VERSION ""

NS_ :

BS_:

BU_: Battery_Management_Cntrl_1 PowertrainControlModule AtmosphericSensor SafetyRestraintSystem2 Aftertreatment_2_GasOutlet Aftertreatment_2_GasIntake DieselParticulateFilterControl Turbocharger SafetyRestraintSystem1 CabDisplay2 Aftertreatment_1_GasOutlet Aftertreatment_1_GasIntake OnBoardDataLogger OffBoardDiagnosticTool2 OffBoardDiagnosticTool1 FileServer ParkingBrakeController SeatController2 FanDriveController SteeringColumnUnit CommunicationUnitRadio CommunicationUnitSatellite CommunicationUnitCellular PropulsionBatteryCharger ChassisController2 ChassisController1 EngineValveControl AuxiliaryHeater2 AuxiliaryHeater1 ClutchUnit RampControl InformationSystem1 SuspensionSystemController2 OilSensor VehicleDynamicStability ExhaustEmissionController TransmissionDisplay2 TransmissionDisplay1 ClimateControl2 WaterPumpController RearAxleSteeringController LightingOperatorControl SeatController1 IgnitionController2 IgnitionController1 TirePressureController CabController2 CabController1 PneumaticSystemController SuspensionSystemController1 HydraulicPumpController EnduranceBrakingSystem RetarderExhaustEngine2 OnBoardDiagnosticUnit HeadwayController RetarderExhaustEngine1 CabDisplay1 ManagementComputer VirtualTerminal OffVehicleGateway PowerTakeOffFront HitchControl AuxiliaryValveControl BodyController TractorTrailerBridge1 StarterSystem ElectricalSystem VehicleSecurity VehicleNavigation AerodynamicControl ElectricalChargingSystem ClimateControl1 TripRecorder InstrumentCluster SuspensionDriveAxle2 SuspensionDriveAxle1 SuspensionSteerAxle SteeringController FuelSystem CruiseControl RetarderDriveline RetarderEngine BrakesDriveAxle2 BrakesDriveAxle1 BrakesSystemController BrakesSteerAxle AxleDrive2 AxleDrive1 AxleSteering PowerTakeOff ShiftConsoleSecondary ShiftConsolePrimary Transmission2 Transmission1 Engine2 Engine1

BO_ 2566705662 DM53: 22 Vector__XXX
 SG_ DTC1 : 16|32@1+ (1,0) [0|4294967295] "" Vector__XXX
 SG_ FlashProtectLamp : 8|2@1+ (1,0) [0|3] "" Vector__XXX
 SG_ FlashAmberWarningLamp : 10|2@1+ (1,0) [0|3] "" Vector__XXX
 SG_ FlashRedStopLamp : 12|2@1+ (1,0) [0|3] "" Vector__XXX
 SG_ FlashMalfuncIndicatorLamp : 14|2@1+ (1,0) [0|3] "" Vector__XXX
 SG_ ProtectLampStatus : 0|2@1+ (1,0) [0|3] "" Vector__XXX
 SG_ AmberWarningLampStatus : 2|2@1+ (1,0) [0|3] "" Vector__XXX
 SG_ RedStopLampState : 4|2@1+ (1,0) [0|3] "" Vector__XXX
 SG_ MalfunctionIndicatorLampStatus : 6|2@1+ (1,0) [0|3] "" Vector__XXX
 SG_ DTC5 : 144|32@1+ (1,0) [0|4294967295] "" Vector__XXX
 SG_ DTC4 : 112|32@1+ (1,0) [0|4294967295] "" Vector__XXX
 SG_ DTC3 : 80|32@1+ (1,0) [0|4294967295] "" Vector__XXX
 SG_ DTC2 : 48|32@1+ (1,0) [0|4294967295] "" Vector__XXX

BO_ 2566706174 DM55: 0 Vector__XXX

BO_ 2349465342 SRASI_2304: 8 Vector__XXX
 SG_ StaticRollAngleStatus_5583 : 8|3@1+ (1,0) [0|7] "" Vector__XXX
 SG_ StaticRollAngle_5582 : 0|8@1+ (1,-125) [-90|90] "deg" Vector__XXX

BO_ 2498777086 ECCAI2: 8 Vector__XXX
 SG_ EngCyl2AverageCombustionDuration : 48|16@1+ (0.0078125,0) [0|501.99] "deg" Vector__XXX
 SG_ EngCyl2AvrgCntrOfCmbustionTiming : 32|16@1+ (0.0078125,-250) [-250|250.992] "deg" Vector__XXX
 SG_ EngCyl2AvrgStrtOfCmbustionTiming : 16|16@1+ (0.0078125,-250) [-250|250.992] "deg" Vector__XXX
 SG_ EngCyl2IndctedMeanEffectivePress : 0|16@1+ (0.0001220703125,-1) [-1|6.84362793] "MPa" Vector__XXX

BO_ 2498776830 ECCAI1: 8 Vector__XXX
 SG_ EngCyl1AverageCombustionDuration : 48|16@1+ (0.0078125,0) [0|501.99] "deg" Vector__XXX
 SG_ EngCyl1AvrgCntrOfCmbustionTiming : 32|16@1+ (0.0078125,-250) [-250|250.992] "deg" Vector__XXX
 SG_ EngCyl1AvrgStrtOfCmbustionTiming : 16|16@1+ (0.0078125,-250) [-250|250.992] "deg" Vector__XXX
 SG_ EngCyl1IndctedMeanEffectivePress : 0|16@1+ (0.0001220703125,-1) [-1|6.84362793] "MPa" Vector__XXX

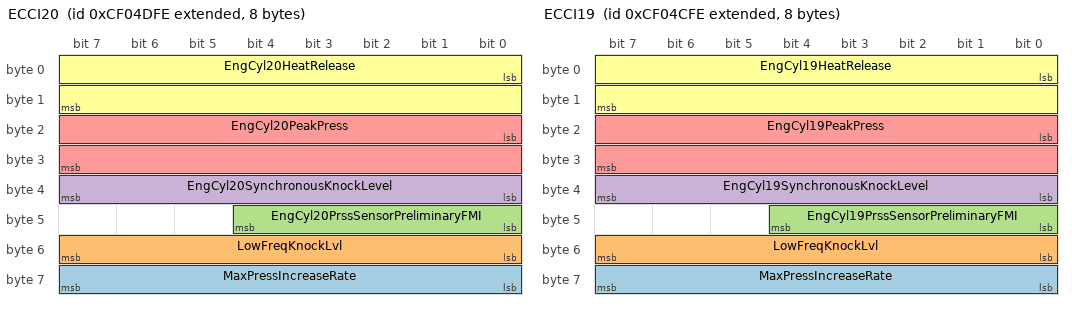
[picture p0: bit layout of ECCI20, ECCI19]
BO_ 2364558846 ECCI20: 8 Vector__XXX
 SG_ MaxPressIncreaseRate : 56|8@1+ (16,0) [0|4000] "kPa/deg crank angle" Vector__XXX
 SG_ LowFreqKnockLvl : 48|8@1+ (1,0) [0|250] "%" Vector__XXX
 SG_ EngCyl20PrssSensorPreliminaryFMI : 40|5@1+ (1,0) [0|31] "" Vector__XXX
 SG_ EngCyl20SynchronousKnockLevel : 32|8@1+ (1,0) [0|250] "%" Vector__XXX
 SG_ EngCyl20PeakPress : 16|16@1+ (0.0009765625,0) [0|62.74902344] "MPa" Vector__XXX
 SG_ EngCyl20HeatRelease : 0|16@1+ (0.0001220703125,-1) [-1|6.84362793] "kJ/l" Vector__XXX

BO_ 2364558590 ECCI19: 8 Vector__XXX
 SG_ MaxPressIncreaseRate : 56|8@1+ (16,0) [0|4000] "kPa/deg crank angle" Vector__XXX
 SG_ LowFreqKnockLvl : 48|8@1+ (1,0) [0|250] "%" Vector__XXX
 SG_ EngCyl19PrssSensorPreliminaryFMI : 40|5@1+ (1,0) [0|31] "" Vector__XXX
 SG_ EngCyl19SynchronousKnockLevel : 32|8@1+ (1,0) [0|250] "%" Vector__XXX
 SG_ EngCyl19PeakPress : 16|16@1+ (0.0009765625,0) [0|62.74902344] "MPa" Vector__XXX
 SG_ EngCyl19HeatRelease : 0|16@1+ (0.0001220703125,-1) [-1|6.84362793] "kJ/l" Vector__XXX

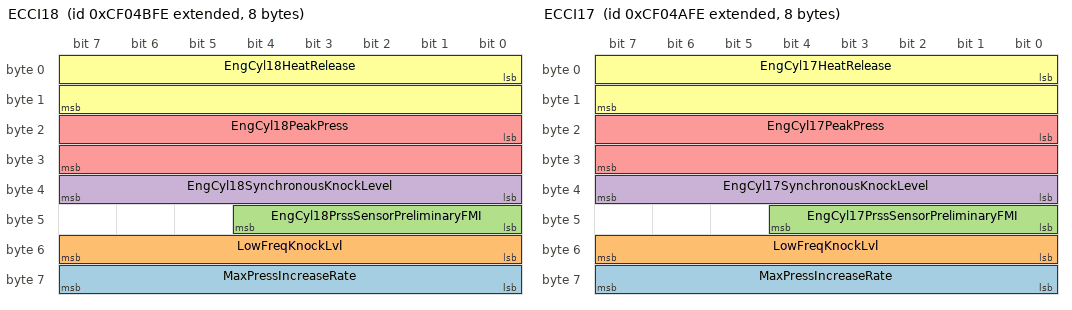
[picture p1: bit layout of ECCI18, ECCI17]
BO_ 2364558334 ECCI18: 8 Vector__XXX
 SG_ MaxPressIncreaseRate : 56|8@1+ (16,0) [0|4000] "kPa/deg crank angle" Vector__XXX
 SG_ LowFreqKnockLvl : 48|8@1+ (1,0) [0|250] "%" Vector__XXX
 SG_ EngCyl18PrssSensorPreliminaryFMI : 40|5@1+ (1,0) [0|31] "" Vector__XXX
 SG_ EngCyl18SynchronousKnockLevel : 32|8@1+ (1,0) [0|250] "%" Vector__XXX
 SG_ EngCyl18PeakPress : 16|16@1+ (0.0009765625,0) [0|62.74902344] "MPa" Vector__XXX
 SG_ EngCyl18HeatRelease : 0|16@1+ (0.0001220703125,-1) [-1|6.84362793] "kJ/l" Vector__XXX

BO_ 2364558078 ECCI17: 8 Vector__XXX
 SG_ MaxPressIncreaseRate : 56|8@1+ (16,0) [0|4000] "kPa/deg crank angle" Vector__XXX
 SG_ LowFreqKnockLvl : 48|8@1+ (1,0) [0|250] "%" Vector__XXX
 SG_ EngCyl17PrssSensorPreliminaryFMI : 40|5@1+ (1,0) [0|31] "" Vector__XXX
 SG_ EngCyl17SynchronousKnockLevel : 32|8@1+ (1,0) [0|250] "%" Vector__XXX
 SG_ EngCyl17PeakPress : 16|16@1+ (0.0009765625,0) [0|62.74902344] "MPa" Vector__XXX
 SG_ EngCyl17HeatRelease : 0|16@1+ (0.0001220703125,-1) [-1|6.84362793] "kJ/l" Vector__XXX

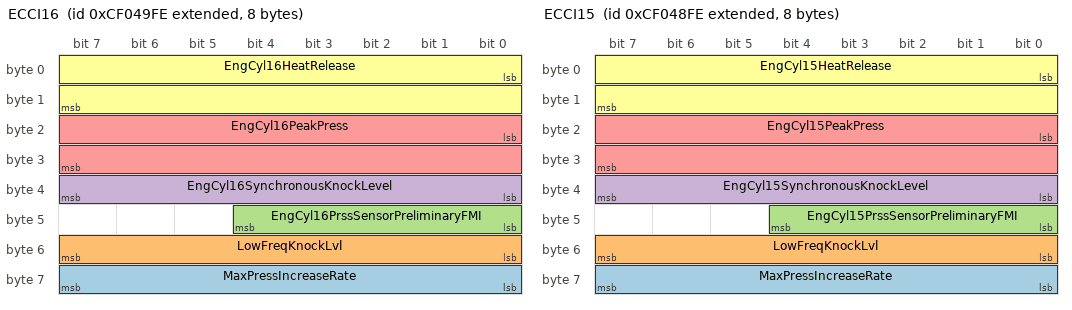
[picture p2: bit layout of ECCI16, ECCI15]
BO_ 2364557822 ECCI16: 8 Vector__XXX
 SG_ MaxPressIncreaseRate : 56|8@1+ (16,0) [0|4000] "kPa/deg crank angle" Vector__XXX
 SG_ LowFreqKnockLvl : 48|8@1+ (1,0) [0|250] "%" Vector__XXX
 SG_ EngCyl16PrssSensorPreliminaryFMI : 40|5@1+ (1,0) [0|31] "" Vector__XXX
 SG_ EngCyl16SynchronousKnockLevel : 32|8@1+ (1,0) [0|250] "%" Vector__XXX
 SG_ EngCyl16PeakPress : 16|16@1+ (0.0009765625,0) [0|62.74902344] "MPa" Vector__XXX
 SG_ EngCyl16HeatRelease : 0|16@1+ (0.0001220703125,-1) [-1|6.84362793] "kJ/l" Vector__XXX

BO_ 2364557566 ECCI15: 8 Vector__XXX
 SG_ MaxPressIncreaseRate : 56|8@1+ (16,0) [0|4000] "kPa/deg crank angle" Vector__XXX
 SG_ LowFreqKnockLvl : 48|8@1+ (1,0) [0|250] "%" Vector__XXX
 SG_ EngCyl15PrssSensorPreliminaryFMI : 40|5@1+ (1,0) [0|31] "" Vector__XXX
 SG_ EngCyl15SynchronousKnockLevel : 32|8@1+ (1,0) [0|250] "%" Vector__XXX
 SG_ EngCyl15PeakPress : 16|16@1+ (0.0009765625,0) [0|62.74902344] "MPa" Vector__XXX
 SG_ EngCyl15HeatRelease : 0|16@1+ (0.0001220703125,-1) [-1|6.84362793] "kJ/l" Vector__XXX

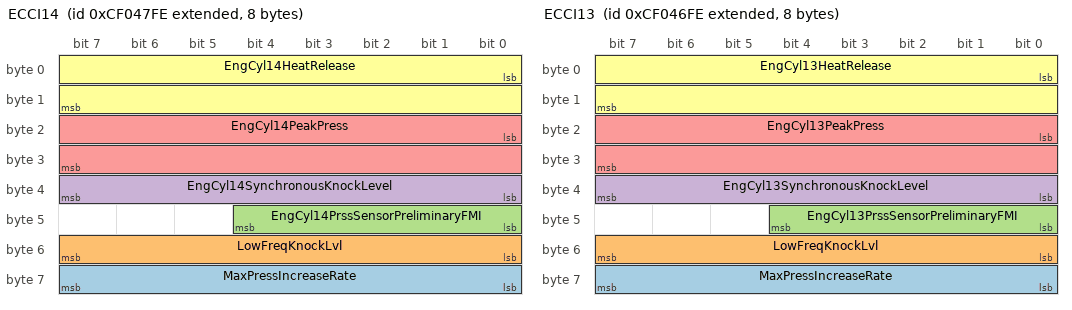
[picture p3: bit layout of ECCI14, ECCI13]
BO_ 2364557310 ECCI14: 8 Vector__XXX
 SG_ MaxPressIncreaseRate : 56|8@1+ (16,0) [0|4000] "kPa/deg crank angle" Vector__XXX
 SG_ LowFreqKnockLvl : 48|8@1+ (1,0) [0|250] "%" Vector__XXX
 SG_ EngCyl14PrssSensorPreliminaryFMI : 40|5@1+ (1,0) [0|31] "" Vector__XXX
 SG_ EngCyl14SynchronousKnockLevel : 32|8@1+ (1,0) [0|250] "%" Vector__XXX
 SG_ EngCyl14PeakPress : 16|16@1+ (0.0009765625,0) [0|62.74902344] "MPa" Vector__XXX
 SG_ EngCyl14HeatRelease : 0|16@1+ (0.0001220703125,-1) [-1|6.84362793] "kJ/l" Vector__XXX

BO_ 2364557054 ECCI13: 8 Vector__XXX
 SG_ MaxPressIncreaseRate : 56|8@1+ (16,0) [0|4000] "kPa/deg crank angle" Vector__XXX
 SG_ LowFreqKnockLvl : 48|8@1+ (1,0) [0|250] "%" Vector__XXX
 SG_ EngCyl13PrssSensorPreliminaryFMI : 40|5@1+ (1,0) [0|31] "" Vector__XXX
 SG_ EngCyl13SynchronousKnockLevel : 32|8@1+ (1,0) [0|250] "%" Vector__XXX
 SG_ EngCyl13PeakPress : 16|16@1+ (0.0009765625,0) [0|62.74902344] "MPa" Vector__XXX
 SG_ EngCyl13HeatRelease : 0|16@1+ (0.0001220703125,-1) [-1|6.84362793] "kJ/l" Vector__XXX

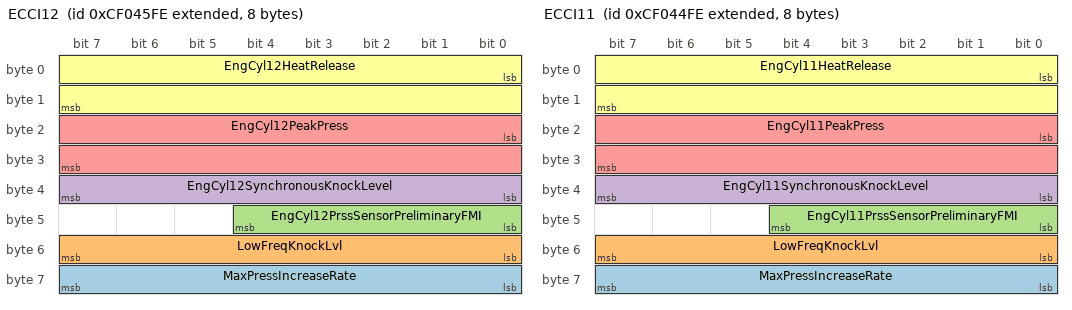
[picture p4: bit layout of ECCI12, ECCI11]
BO_ 2364556798 ECCI12: 8 Vector__XXX
 SG_ MaxPressIncreaseRate : 56|8@1+ (16,0) [0|4000] "kPa/deg crank angle" Vector__XXX
 SG_ LowFreqKnockLvl : 48|8@1+ (1,0) [0|250] "%" Vector__XXX
 SG_ EngCyl12PrssSensorPreliminaryFMI : 40|5@1+ (1,0) [0|31] "" Vector__XXX
 SG_ EngCyl12SynchronousKnockLevel : 32|8@1+ (1,0) [0|250] "%" Vector__XXX
 SG_ EngCyl12PeakPress : 16|16@1+ (0.0009765625,0) [0|62.74902344] "MPa" Vector__XXX
 SG_ EngCyl12HeatRelease : 0|16@1+ (0.0001220703125,-1) [-1|6.84362793] "kJ/l" Vector__XXX

BO_ 2364556542 ECCI11: 8 Vector__XXX
 SG_ MaxPressIncreaseRate : 56|8@1+ (16,0) [0|4000] "kPa/deg crank angle" Vector__XXX
 SG_ LowFreqKnockLvl : 48|8@1+ (1,0) [0|250] "%" Vector__XXX
 SG_ EngCyl11PrssSensorPreliminaryFMI : 40|5@1+ (1,0) [0|31] "" Vector__XXX
 SG_ EngCyl11SynchronousKnockLevel : 32|8@1+ (1,0) [0|250] "%" Vector__XXX
 SG_ EngCyl11PeakPress : 16|16@1+ (0.0009765625,0) [0|62.74902344] "MPa" Vector__XXX
 SG_ EngCyl11HeatRelease : 0|16@1+ (0.0001220703125,-1) [-1|6.84362793] "kJ/l" Vector__XXX

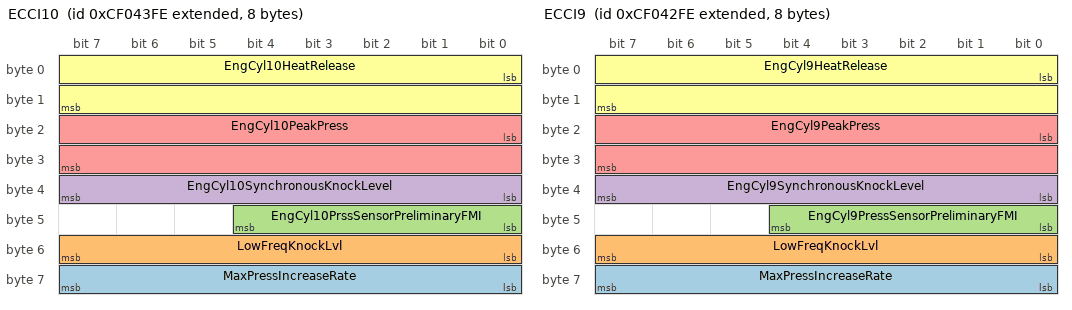
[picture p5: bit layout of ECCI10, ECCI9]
BO_ 2364556286 ECCI10: 8 Vector__XXX
 SG_ MaxPressIncreaseRate : 56|8@1+ (16,0) [0|4000] "kPa/deg crank angle" Vector__XXX
 SG_ LowFreqKnockLvl : 48|8@1+ (1,0) [0|250] "%" Vector__XXX
 SG_ EngCyl10PrssSensorPreliminaryFMI : 40|5@1+ (1,0) [0|31] "" Vector__XXX
 SG_ EngCyl10SynchronousKnockLevel : 32|8@1+ (1,0) [0|250] "%" Vector__XXX
 SG_ EngCyl10PeakPress : 16|16@1+ (0.0009765625,0) [0|62.74902344] "MPa" Vector__XXX
 SG_ EngCyl10HeatRelease : 0|16@1+ (0.0001220703125,-1) [-1|6.84362793] "kJ/l" Vector__XXX

BO_ 2364556030 ECCI9: 8 Vector__XXX
 SG_ MaxPressIncreaseRate : 56|8@1+ (16,0) [0|4000] "kPa/deg crank angle" Vector__XXX
 SG_ LowFreqKnockLvl : 48|8@1+ (1,0) [0|250] "%" Vector__XXX
 SG_ EngCyl9PressSensorPreliminaryFMI : 40|5@1+ (1,0) [0|31] "" Vector__XXX
 SG_ EngCyl9SynchronousKnockLevel : 32|8@1+ (1,0) [0|250] "%" Vector__XXX
 SG_ EngCyl9PeakPress : 16|16@1+ (0.0009765625,0) [0|62.74902344] "MPa" Vector__XXX
 SG_ EngCyl9HeatRelease : 0|16@1+ (0.0001220703125,-1) [-1|6.84362793] "kJ/l" Vector__XXX

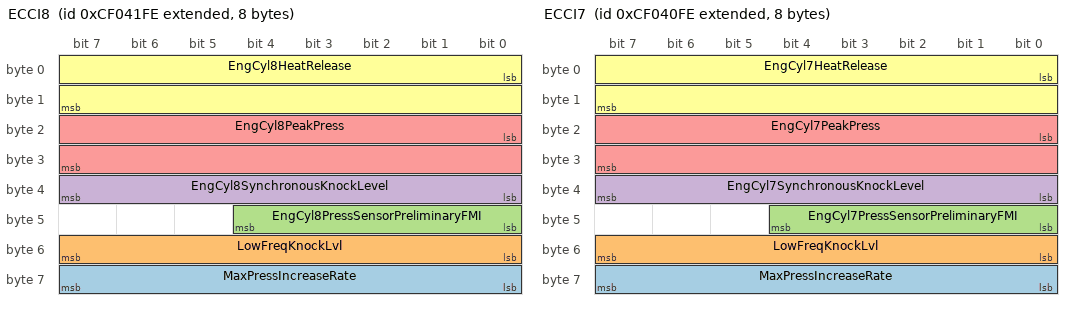
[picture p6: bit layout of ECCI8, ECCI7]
BO_ 2364555774 ECCI8: 8 Vector__XXX
 SG_ MaxPressIncreaseRate : 56|8@1+ (16,0) [0|4000] "kPa/deg crank angle" Vector__XXX
 SG_ LowFreqKnockLvl : 48|8@1+ (1,0) [0|250] "%" Vector__XXX
 SG_ EngCyl8PressSensorPreliminaryFMI : 40|5@1+ (1,0) [0|31] "" Vector__XXX
 SG_ EngCyl8SynchronousKnockLevel : 32|8@1+ (1,0) [0|250] "%" Vector__XXX
 SG_ EngCyl8PeakPress : 16|16@1+ (0.0009765625,0) [0|62.74902344] "MPa" Vector__XXX
 SG_ EngCyl8HeatRelease : 0|16@1+ (0.0001220703125,-1) [-1|6.84362793] "kJ/l" Vector__XXX

BO_ 2364555518 ECCI7: 8 Vector__XXX
 SG_ MaxPressIncreaseRate : 56|8@1+ (16,0) [0|4000] "kPa/deg crank angle" Vector__XXX
 SG_ LowFreqKnockLvl : 48|8@1+ (1,0) [0|250] "%" Vector__XXX
 SG_ EngCyl7PressSensorPreliminaryFMI : 40|5@1+ (1,0) [0|31] "" Vector__XXX
 SG_ EngCyl7SynchronousKnockLevel : 32|8@1+ (1,0) [0|250] "%" Vector__XXX
 SG_ EngCyl7PeakPress : 16|16@1+ (0.0009765625,0) [0|62.74902344] "MPa" Vector__XXX
 SG_ EngCyl7HeatRelease : 0|16@1+ (0.0001220703125,-1) [-1|6.84362793] "kJ/l" Vector__XXX

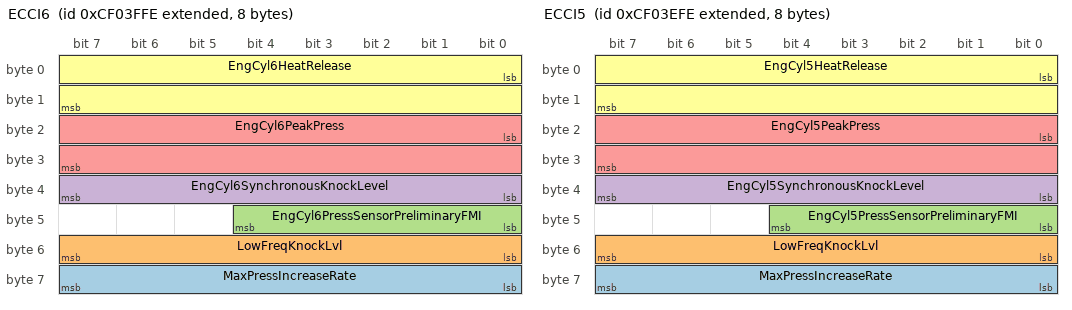
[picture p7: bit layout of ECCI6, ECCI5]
BO_ 2364555262 ECCI6: 8 Vector__XXX
 SG_ MaxPressIncreaseRate : 56|8@1+ (16,0) [0|4000] "kPa/deg crank angle" Vector__XXX
 SG_ LowFreqKnockLvl : 48|8@1+ (1,0) [0|250] "%" Vector__XXX
 SG_ EngCyl6PressSensorPreliminaryFMI : 40|5@1+ (1,0) [0|31] "" Vector__XXX
 SG_ EngCyl6SynchronousKnockLevel : 32|8@1+ (1,0) [0|250] "%" Vector__XXX
 SG_ EngCyl6PeakPress : 16|16@1+ (0.0009765625,0) [0|62.74902344] "MPa" Vector__XXX
 SG_ EngCyl6HeatRelease : 0|16@1+ (0.0001220703125,-1) [-1|6.84362793] "kJ/l" Vector__XXX

BO_ 2364555006 ECCI5: 8 Vector__XXX
 SG_ MaxPressIncreaseRate : 56|8@1+ (16,0) [0|4000] "kPa/deg crank angle" Vector__XXX
 SG_ LowFreqKnockLvl : 48|8@1+ (1,0) [0|250] "%" Vector__XXX
 SG_ EngCyl5PressSensorPreliminaryFMI : 40|5@1+ (1,0) [0|31] "" Vector__XXX
 SG_ EngCyl5SynchronousKnockLevel : 32|8@1+ (1,0) [0|250] "%" Vector__XXX
 SG_ EngCyl5PeakPress : 16|16@1+ (0.0009765625,0) [0|62.74902344] "MPa" Vector__XXX
 SG_ EngCyl5HeatRelease : 0|16@1+ (0.0001220703125,-1) [-1|6.84362793] "kJ/l" Vector__XXX

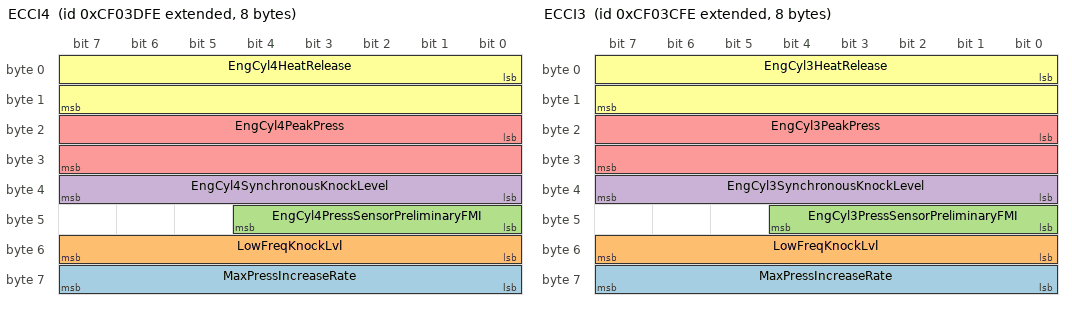
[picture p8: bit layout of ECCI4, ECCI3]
BO_ 2364554750 ECCI4: 8 Vector__XXX
 SG_ MaxPressIncreaseRate : 56|8@1+ (16,0) [0|4000] "kPa/deg crank angle" Vector__XXX
 SG_ LowFreqKnockLvl : 48|8@1+ (1,0) [0|250] "%" Vector__XXX
 SG_ EngCyl4PressSensorPreliminaryFMI : 40|5@1+ (1,0) [0|31] "" Vector__XXX
 SG_ EngCyl4SynchronousKnockLevel : 32|8@1+ (1,0) [0|250] "%" Vector__XXX
 SG_ EngCyl4PeakPress : 16|16@1+ (0.0009765625,0) [0|62.74902344] "MPa" Vector__XXX
 SG_ EngCyl4HeatRelease : 0|16@1+ (0.0001220703125,-1) [-1|6.84362793] "kJ/l" Vector__XXX

BO_ 2364554494 ECCI3: 8 Vector__XXX
 SG_ MaxPressIncreaseRate : 56|8@1+ (16,0) [0|4000] "kPa/deg crank angle" Vector__XXX
 SG_ LowFreqKnockLvl : 48|8@1+ (1,0) [0|250] "%" Vector__XXX
 SG_ EngCyl3PressSensorPreliminaryFMI : 40|5@1+ (1,0) [0|31] "" Vector__XXX
 SG_ EngCyl3SynchronousKnockLevel : 32|8@1+ (1,0) [0|250] "%" Vector__XXX
 SG_ EngCyl3PeakPress : 16|16@1+ (0.0009765625,0) [0|62.74902344] "MPa" Vector__XXX
 SG_ EngCyl3HeatRelease : 0|16@1+ (0.0001220703125,-1) [-1|6.84362793] "kJ/l" Vector__XXX

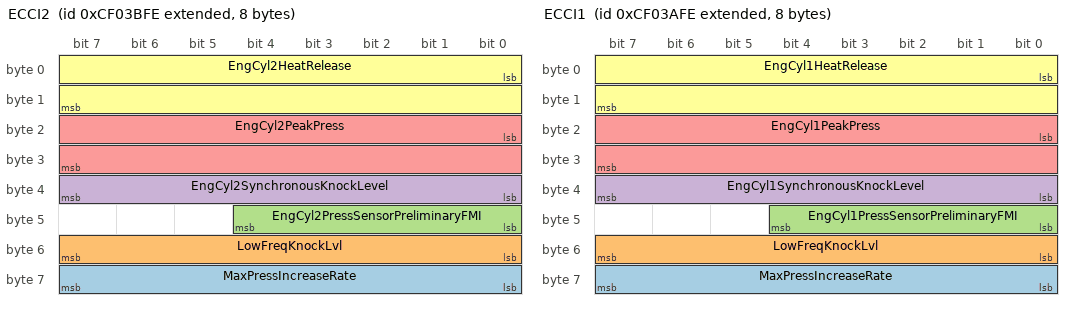
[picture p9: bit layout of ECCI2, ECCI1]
BO_ 2364554238 ECCI2: 8 Vector__XXX
 SG_ MaxPressIncreaseRate : 56|8@1+ (16,0) [0|4000] "kPa/deg crank angle" Vector__XXX
 SG_ LowFreqKnockLvl : 48|8@1+ (1,0) [0|250] "%" Vector__XXX
 SG_ EngCyl2PressSensorPreliminaryFMI : 40|5@1+ (1,0) [0|31] "" Vector__XXX
 SG_ EngCyl2SynchronousKnockLevel : 32|8@1+ (1,0) [0|250] "%" Vector__XXX
 SG_ EngCyl2PeakPress : 16|16@1+ (0.0009765625,0) [0|62.74902344] "MPa" Vector__XXX
 SG_ EngCyl2HeatRelease : 0|16@1+ (0.0001220703125,-1) [-1|6.84362793] "kJ/l" Vector__XXX

BO_ 2364553982 ECCI1: 8 Vector__XXX
 SG_ MaxPressIncreaseRate : 56|8@1+ (16,0) [0|4000] "kPa/deg crank angle" Vector__XXX
 SG_ LowFreqKnockLvl : 48|8@1+ (1,0) [0|250] "%" Vector__XXX
 SG_ EngCyl1PressSensorPreliminaryFMI : 40|5@1+ (1,0) [0|31] "" Vector__XXX
 SG_ EngCyl1SynchronousKnockLevel : 32|8@1+ (1,0) [0|100] "%" Vector__XXX
 SG_ EngCyl1PeakPress : 16|16@1+ (0.0009765625,0) [0|62.74902344] "MPa" Vector__XXX
 SG_ EngCyl1HeatRelease : 0|16@1+ (0.0001220703125,-1) [-1|6.84362793] "kJ/l" Vector__XXX

BO_ 2364553726 EASI: 8 Vector__XXX
 SG_ EngTotalIntakeMassAirFlowRate : 16|16@1+ (0.0009765625,0) [0|62.74902344] "kg/s" Vector__XXX
 SG_ EngDesiredAirFuelRatio : 0|16@1+ (0.001,0) [0|64.255] "" Vector__XXX

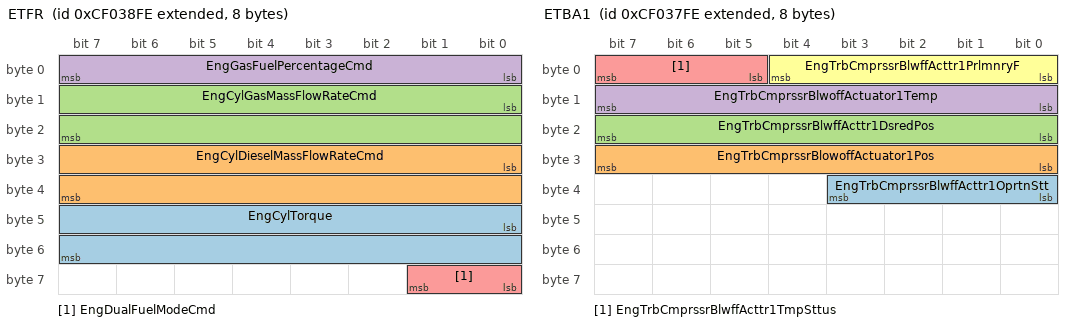
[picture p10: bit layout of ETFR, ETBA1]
BO_ 2364553470 ETFR: 8 Vector__XXX
 SG_ EngCylTorque : 40|16@1+ (1,0) [0|64255] "Nm" Vector__XXX
 SG_ EngCylDieselMassFlowRateCmd : 24|16@1+ (6.103515625E-005,0) [0|3.921813965] "kg/s" Vector__XXX
 SG_ EngCylGasMassFlowRateCmd : 8|16@1+ (6.103515625E-005,0) [0|3.921813965] "kg/s" Vector__XXX
 SG_ EngGasFuelPercentageCmd : 0|8@1+ (0.5,0) [0|100] "%" Vector__XXX
 SG_ EngDualFuelModeCmd : 56|2@1+ (1,0) [0|100] "" Vector__XXX

BO_ 2364553214 ETBA1: 8 Vector__XXX
 SG_ EngTrbCmprssrBlwffActtr1OprtnStt : 32|4@1+ (1,0) [0|15] "" Vector__XXX
 SG_ EngTrbCmprssrBlowoffActuator1Pos : 24|8@1+ (0.4,0) [0|100] "%" Vector__XXX
 SG_ EngTrbCmprssrBlwffActtr1DsredPos : 16|8@1+ (0.4,0) [0|100] "%" Vector__XXX
 SG_ EngTrbCmprssrBlwoffActuator1Temp : 8|8@1+ (1,-40) [-40|210] "°C" Vector__XXX
 SG_ EngTrbCmprssrBlwffActtr1TmpSttus : 5|3@1+ (1,0) [0|7] "" Vector__XXX
 SG_ EngTrbCmprssrBlwffActtr1PrlmnryF : 0|5@1+ (1,0) [0|31] "" Vector__XXX

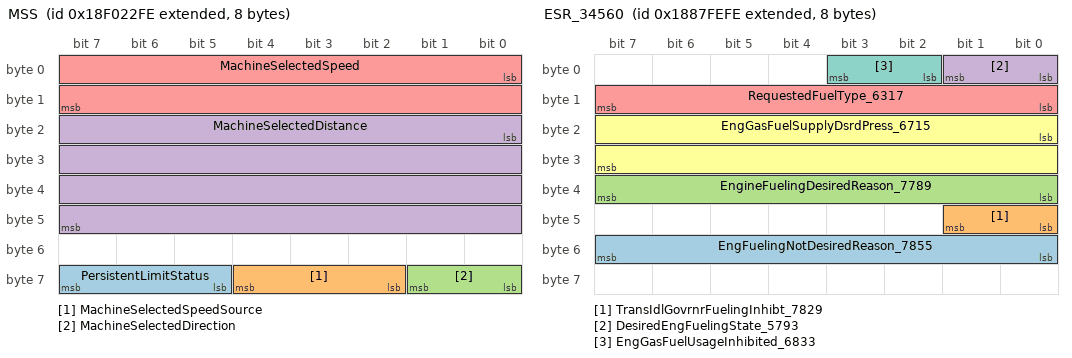
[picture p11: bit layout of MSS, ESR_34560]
BO_ 2565874430 MSS: 8 Vector__XXX
 SG_ PersistentLimitStatus : 61|3@1+ (1,0) [0|0] "" Vector__XXX
 SG_ MachineSelectedSpeedSource : 58|3@1+ (1,0) [0|0] "" Vector__XXX
 SG_ MachineSelectedDirection : 56|2@1+ (1,0) [0|0] "" Vector__XXX
 SG_ MachineSelectedDistance : 16|32@1+ (1,0) [0|0] "" Vector__XXX
 SG_ MachineSelectedSpeed : 0|16@1+ (1,0) [0|0] "" Vector__XXX

BO_ 2565873918 EBS25: 8 Vector__XXX

BO_ 2565873662 EBS26: 8 Vector__XXX

BO_ 2364546814 GC2: 8 Vector__XXX
 SG_ GeneratorGoverningBias : 0|16@1+ (0.004,-125) [-125|125] "%" Vector__XXX

BO_ 2565872638 GPM17: 8 Vector__XXX

BO_ 2565865214 PropA_61184: 8 Vector__XXX
 SG_ ManufacturerSpecfn_2550 : 0|64@1+ (1,0) [0|0] "" Vector__XXX

BO_ 2565340926 VT21: 8 Vector__XXX

BO_ 2565275390 VT12: 8 Vector__XXX

BO_ 2566767614 EEC15: 8 Vector__XXX
 SG_ AccelPedal2Channel3 : 24|8@1+ (0.4,0) [0|100] "%" Vector__XXX
 SG_ AccelPedal2Channel2 : 16|8@1+ (0.4,0) [0|100] "%" Vector__XXX
 SG_ AccelPedal1Channel3 : 8|8@1+ (0.4,0) [0|100] "%" Vector__XXX
 SG_ AccelPedal1Channel2 : 0|8@1+ (0.4,0) [0|100] "%" Vector__XXX

BO_ 2559049470 ESR_34560: 8 Vector__XXX
 SG_ EngFuelingNotDesiredReason_7855 : 48|8@1+ (1,0) [0|255] "" Vector__XXX
 SG_ TransIdlGovrnrFuelingInhibt_7829 : 40|2@1+ (1,0) [0|3] "" Vector__XXX
 SG_ EngineFuelingDesiredReason_7789 : 32|8@1- (1,0) [0|0] "" Vector__XXX
 SG_ DesiredEngFuelingState_5793 : 0|2@1+ (1,0) [0|3] "" Vector__XXX
 SG_ RequestedFuelType_6317 : 8|8@1+ (1,0) [0|255] "" Vector__XXX
 SG_ EngGasFuelSupplyDsrdPress_6715 : 16|16@1+ (0.5,0) [0|32127.5] "kPa" Vector__XXX
 SG_ EngGasFuelUsageInhibited_6833 : 2|2@1+ (1,0) [0|3] "" Vector__XXX

BO_ 2349596414 AEBS2_2816: 8 Vector__XXX
 SG_ AEBS2MessageChecksum_5683 : 60|4@1+ (1,0) [0|15] "" Vector__XXX
 SG_ AEBS2MessageCounter_5682 : 56|4@1+ (1,0) [0|15] "" Vector__XXX
 SG_ DrvrActDmndFrAdvEmrgncyBrk_5681 : 0|2@1+ (1,0) [0|3] "" Vector__XXX

BO_ 2563702526 KWP3: 8 Vector__XXX

BO_ 2563636990 KWP4: 8 Vector__XXX

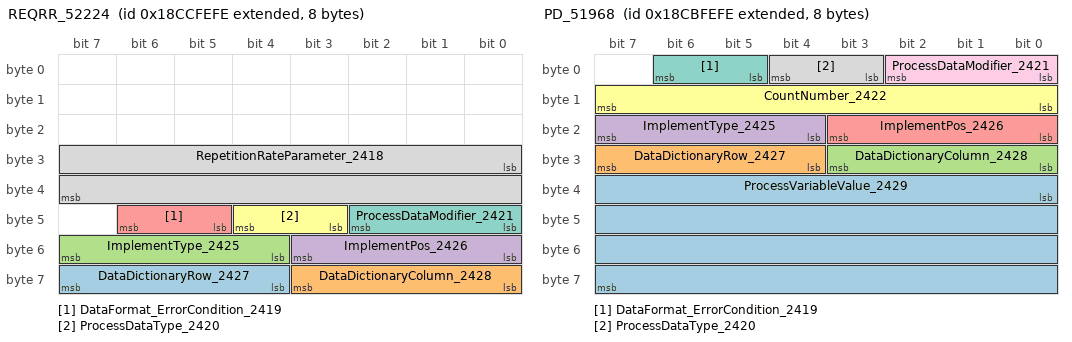
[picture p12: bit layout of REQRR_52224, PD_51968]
BO_ 2563571454 REQRR_52224: 8 Vector__XXX
 SG_ DataDictionaryRow_2427 : 60|4@1+ (1,0) [0|0] "" Vector__XXX
 SG_ DataDictionaryColumn_2428 : 56|4@1+ (1,0) [0|0] "" Vector__XXX
 SG_ ImplementType_2425 : 52|4@1+ (1,0) [0|0] "" Vector__XXX
 SG_ ImplementPos_2426 : 48|4@1+ (1,0) [0|0] "" Vector__XXX
 SG_ DataFormat_ErrorCondition_2419 : 45|2@1+ (1,0) [0|0] "" Vector__XXX
 SG_ ProcessDataType_2420 : 43|2@1+ (1,0) [0|0] "" Vector__XXX
 SG_ ProcessDataModifier_2421 : 40|3@1+ (1,0) [0|0] "" Vector__XXX
 SG_ RepetitionRateParameter_2418 : 24|16@1+ (1,0) [0|0] "" Vector__XXX

BO_ 2563505918 PD_51968: 8 Vector__XXX
 SG_ ProcessVariableValue_2429 : 32|32@1+ (1,0) [0|0] "" Vector__XXX
 SG_ DataDictionaryRow_2427 : 28|4@1+ (1,0) [0|0] "" Vector__XXX
 SG_ DataDictionaryColumn_2428 : 24|4@1+ (1,0) [0|0] "" Vector__XXX
 SG_ ImplementType_2425 : 20|4@1+ (1,0) [0|0] "" Vector__XXX
 SG_ ImplementPos_2426 : 16|4@1+ (1,0) [0|0] "" Vector__XXX
 SG_ CountNumber_2422 : 8|8@1+ (1,0) [0|0] "" Vector__XXX
 SG_ DataFormat_ErrorCondition_2419 : 5|2@1+ (1,0) [0|0] "" Vector__XXX
 SG_ ProcessDataType_2420 : 3|2@1+ (1,0) [0|0] "" Vector__XXX
 SG_ ProcessDataModifier_2421 : 0|3@1+ (1,0) [0|0] "" Vector__XXX

BO_ 2563309310 ETPCM: 8 Vector__XXX

BO_ 2563243774 ETPDT: 8 Vector__XXX

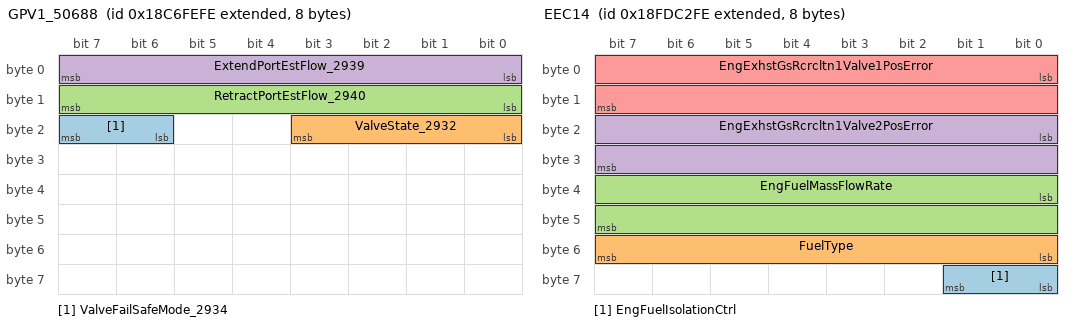
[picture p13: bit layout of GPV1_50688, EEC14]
BO_ 2563178238 GPV1_50688: 8 Vector__XXX
 SG_ ValveFailSafeMode_2934 : 22|2@1+ (1,0) [0|0] "" Vector__XXX
 SG_ ValveState_2932 : 16|4@1+ (1,0) [0|0] "" Vector__XXX
 SG_ RetractPortEstFlow_2940 : 8|8@1+ (1,0) [0|0] "" Vector__XXX
 SG_ ExtendPortEstFlow_2939 : 0|8@1+ (1,0) [0|0] "" Vector__XXX

BO_ 2563112702 GPV2_50432: 8 Vector__XXX
 SG_ ReturnPortPress_2943 : 48|8@1+ (1,0) [0|0] "" Vector__XXX
 SG_ RetractPortPress_2942 : 32|16@1+ (1,0) [0|0] "" Vector__XXX
 SG_ ExtendPortPress_2941 : 16|16@1+ (1,0) [0|0] "" Vector__XXX
 SG_ RetractPortMeasuredFlow_2938 : 8|8@1+ (1,0) [0|0] "" Vector__XXX
 SG_ ExtendPortMeasuredFlow_2937 : 0|8@1+ (1,0) [0|0] "" Vector__XXX

BO_ 2563047166 GPV3_50176: 8 Vector__XXX
 SG_ PortFlowCmd_2944 : 0|8@1+ (1,0) [0|0] "" Vector__XXX

BO_ 2562785022 PCM16: 8 Vector__XXX

BO_ 2562719486 PCM15: 8 Vector__XXX

BO_ 2562653950 PCM14: 8 Vector__XXX

BO_ 2562588414 PCM13: 8 Vector__XXX

BO_ 2562522878 PCM12: 8 Vector__XXX

BO_ 2562457342 PCM11: 8 Vector__XXX

BO_ 2562391806 PCM10: 8 Vector__XXX

BO_ 2562326270 PCM9: 8 Vector__XXX

BO_ 2562260734 PCM8: 8 Vector__XXX

BO_ 2562195198 PCM7: 8 Vector__XXX

BO_ 2562129662 PCM6: 8 Vector__XXX

BO_ 2562064126 PCM5: 8 Vector__XXX

BO_ 2561998590 PCM4: 8 Vector__XXX

BO_ 2561933054 PCM3: 8 Vector__XXX

BO_ 2561867518 PCM2: 8 Vector__XXX

BO_ 2561801982 PCM1: 8 Vector__XXX

BO_ 2561736446 CIM: 8 Vector__XXX

BO_ 2561670910 PLM: 8 Vector__XXX

BO_ 2561539838 GSC: 8 Vector__XXX

BO_ 2561474302 GMS: 8 Vector__XXX

BO_ 2561408766 FSC: 8 Vector__XXX

BO_ 2560294654 GPM18_39424: 8 Vector__XXX

BO_ 2358509310 NM_37632: 8 Vector__XXX
 SG_ VehicleSystemQualifierFlag : 12|1@1+ (1,0) [0|1] "" Vector__XXX
 SG_ VehicleSystemInstanceQualifierFl : 13|1@1+ (1,0) [0|1] "" Vector__XXX
 SG_ NameChecksum : 0|8@1+ (1,0) [0|0] "" Vector__XXX
 SG_ NMControlModeIndicator : 16|4@1+ (1,0) [0|15] "" Vector__XXX
 SG_ ManufacturerCodeQualifierFlag : 8|1@1+ (1,0) [0|1] "" Vector__XXX
 SG_ IndustryGroupQualifierFlag : 14|1@1+ (1,0) [0|1] "" Vector__XXX
 SG_ FunctionQualifierFlag : 11|1@1+ (1,0) [0|1] "" Vector__XXX
 SG_ FunctionInstanceQualifierFlag : 10|1@1+ (1,0) [0|1] "" Vector__XXX
 SG_ ErrorCode : 0|8@1+ (1,0) [0|0] "" Vector__XXX
 SG_ ECUInstanceQualifierFlag : 9|1@1+ (1,0) [0|1] "" Vector__XXX
 SG_ CommandVehicleSystemInstance : 56|4@1+ (1,0) [0|15] "" Vector__XXX
 SG_ CommandVehicleSystem : 49|7@1+ (1,0) [0|127] "" Vector__XXX
 SG_ CommandManufacturerCode : 21|11@1+ (1,0) [0|2047] "" Vector__XXX
 SG_ CommandIndustryGroup : 60|3@1+ (1,0) [0|7] "" Vector__XXX
 SG_ CommandFunctionInstance : 35|5@1+ (1,0) [0|31] "" Vector__XXX
 SG_ CommandFunction : 40|8@1+ (1,0) [0|255] "" Vector__XXX
 SG_ CommandECUInstance : 32|3@1+ (1,0) [0|7] "" Vector__XXX
 SG_ CommandArbitraryAddressCapable : 63|1@1+ (1,0) [0|1] "" Vector__XXX
 SG_ ArbitraryAddressCapableQualifier : 15|1@1+ (1,0) [0|1] "" Vector__XXX

BO_ 2559508222 SCMCC: 8 Vector__XXX

BO_ 2559442686 SCCCM: 8 Vector__XXX

BO_ 2559377150 CCP_CRO: 8 Vector__XXX

BO_ 2559311614 CCP_DTO: 8 Vector__XXX

BO_ 2558983934 SPOC_34304: 8 Vector__XXX
 SG_ SwitchedPowerOutput18Cmd_6002 : 36|2@1+ (1,0) [0|3] "" Vector__XXX
 SG_ SwitchedPowerOutput19Cmd_6001 : 34|2@1+ (1,0) [0|3] "" Vector__XXX
 SG_ SwitchedPowerOutput20Cmd_6000 : 32|2@1+ (1,0) [0|3] "" Vector__XXX
 SG_ SwitchedPowerOutput13Cmd_5999 : 30|2@1+ (1,0) [0|3] "" Vector__XXX
 SG_ SwitchedPowerOutput14Cmd_5998 : 28|2@1+ (1,0) [0|3] "" Vector__XXX
 SG_ SwitchedPowerOutput15Cmd_5997 : 26|2@1+ (1,0) [0|3] "" Vector__XXX
 SG_ SwitchedPowerOutput16Cmd_5996 : 24|2@1+ (1,0) [0|3] "" Vector__XXX
 SG_ SwitchedPowerOutput9Cmd_5995 : 22|2@1+ (1,0) [0|3] "" Vector__XXX
 SG_ SwitchedPowerOutput10Cmd_5994 : 20|2@1+ (1,0) [0|3] "" Vector__XXX
 SG_ SwitchedPowerOutput29Cmd_6015 : 62|2@1+ (1,0) [0|3] "" Vector__XXX
 SG_ SwitchedPowerOutput30Cmd_6014 : 60|2@1+ (1,0) [0|3] "" Vector__XXX
 SG_ SwitchedPowerOutput31Cmd_6013 : 58|2@1+ (1,0) [0|3] "" Vector__XXX
 SG_ SwitchedPowerOutput32Cmd_6012 : 56|2@1+ (1,0) [0|3] "" Vector__XXX
 SG_ SwitchedPowerOutput25Cmd_6011 : 54|2@1+ (1,0) [0|3] "" Vector__XXX
 SG_ SwitchedPowerOutput26Cmd_6010 : 52|2@1+ (1,0) [0|3] "" Vector__XXX
 SG_ SwitchedPowerOutput27Cmd_6009 : 50|2@1+ (1,0) [0|3] "" Vector__XXX
 SG_ SwitchedPowerOutput28Cmd_6008 : 48|2@1+ (1,0) [0|3] "" Vector__XXX
 SG_ SwitchedPowerOutput21Cmd_6007 : 46|2@1+ (1,0) [0|3] "" Vector__XXX
 SG_ SwitchedPowerOutput22Cmd_6006 : 44|2@1+ (1,0) [0|3] "" Vector__XXX
 SG_ SwitchedPowerOutput23Cmd_6005 : 42|2@1+ (1,0) [0|3] "" Vector__XXX
 SG_ SwitchedPowerOutput24Cmd_6004 : 40|2@1+ (1,0) [0|3] "" Vector__XXX
 SG_ SwitchedPowerOutput17Cmd_6003 : 38|2@1+ (1,0) [0|3] "" Vector__XXX
 SG_ SwitchedPowerOutput11Cmd_5993 : 18|2@1+ (1,0) [0|3] "" Vector__XXX
 SG_ SwitchedPowerOutput12Cmd_5992 : 16|2@1+ (1,0) [0|3] "" Vector__XXX
 SG_ SwitchedPowerOutput5Cmd_5991 : 14|2@1+ (1,0) [0|3] "" Vector__XXX
 SG_ SwitchedPowerOutput6Cmd_5990 : 12|2@1+ (1,0) [0|3] "" Vector__XXX
 SG_ SwitchedPowerOutput7Cmd_5989 : 10|2@1+ (1,0) [0|3] "" Vector__XXX
 SG_ SwitchedPowerOutput8Cmd_5988 : 8|2@1+ (1,0) [0|3] "" Vector__XXX
 SG_ SwitchedPowerOutput1Cmd_5987 : 6|2@1+ (1,0) [0|3] "" Vector__XXX
 SG_ SwitchedPowerOutput2Cmd_5986 : 4|2@1+ (1,0) [0|3] "" Vector__XXX
 SG_ SwitchedPowerOutput3Cmd_5985 : 2|2@1+ (1,0) [0|3] "" Vector__XXX
 SG_ SwitchedPowerOutput4Cmd_5984 : 0|2@1+ (1,0) [0|3] "" Vector__XXX

BO_ 2349727486 TC2_3328: 8 Vector__XXX
 SG_ TransMode10_6570 : 2|2@1+ (1,0) [0|3] "" Vector__XXX
 SG_ TransMode9_6569 : 0|2@1+ (1,0) [0|3] "" Vector__XXX

BO_ 2550988542 EEC16_3072: 8 Vector__XXX
 SG_ EngineClutchEngageReqStatus_7844 : 10|2@1+ (1,0) [0|3] "" Vector__XXX
 SG_ ReadyForClutchEngmntStatus_7847 : 8|2@1+ (1,0) [0|3] "" Vector__XXX
 SG_ AccelPedalPos3_28 : 0|8@1+ (0.4,0) [0|100] "%" Vector__XXX

BO_ 2550595326 CAM21_1536: 8 Vector__XXX

BO_ 2550529790 CAM11_1280: 8 Vector__XXX

BO_ 2566767358 EEC14: 8 Vector__XXX
 SG_ EngFuelIsolationCtrl : 56|2@1+ (1,0) [0|3] "" Vector__XXX
 SG_ FuelType : 48|8@1+ (1,0) [0|255] "" Vector__XXX
 SG_ EngFuelMassFlowRate : 32|16@1+ (0.005,0) [0|321.275] "g/s" Vector__XXX
 SG_ EngExhstGsRcrcltn1Valve2PosError : 16|16@1+ (0.004,-125) [-125|132.02] "%" Vector__XXX
 SG_ EngExhstGsRcrcltn1Valve1PosError : 0|16@1+ (0.004,-125) [-125|132.02] "%" Vector__XXX

BO_ 2566706686 AT1P1I: 8 Vector__XXX
 SG_ TwoMotorSpd : 8|16@1+ (0.5,0) [0|32127.5] "rpm" Vector__XXX
 SG_ Htr : 0|8@1+ (0.4,0) [0|100] "%" Vector__XXX

BO_ 2566705406 EPSI: 8 Vector__XXX
 SG_ AFT1ParticulateSnsrCur : 32|16@1+ (0.00390625,0) [0|127] "µA" Vector__XXX
 SG_ AFT2ParticulateSnsr : 16|16@1+ (0.0125,0) [0|803.1875] "mg/m³" Vector__XXX
 SG_ AFT1ParticulateSnsr : 0|16@1+ (0.0125,0) [0|803.1875] "mg/m³" Vector__XXX

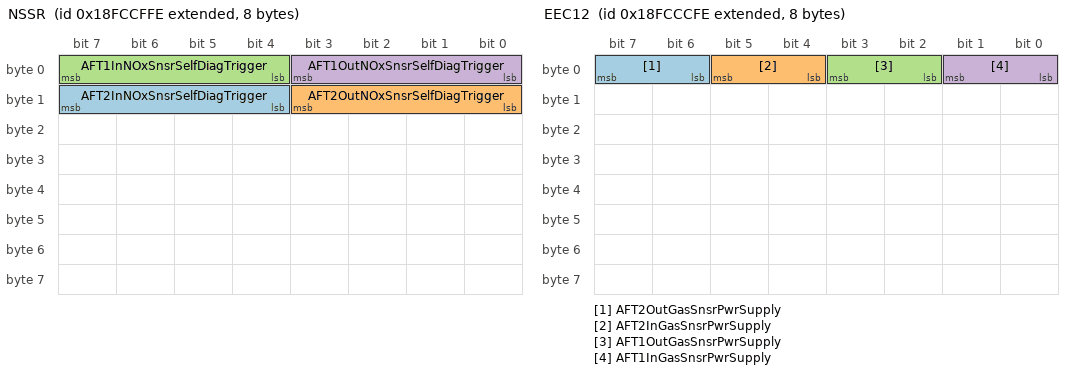
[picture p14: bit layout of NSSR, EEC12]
BO_ 2566705150 NSSR: 8 Vector__XXX
 SG_ AFT2InNOxSnsrSelfDiagTrigger : 12|4@1+ (1,0) [0|15] "" Vector__XXX
 SG_ AFT2OutNOxSnsrSelfDiagTrigger : 8|4@1+ (1,0) [0|15] "" Vector__XXX
 SG_ AFT1InNOxSnsrSelfDiagTrigger : 4|4@1+ (1,0) [0|15] "" Vector__XXX
 SG_ AFT1OutNOxSnsrSelfDiagTrigger : 0|4@1+ (1,0) [0|15] "" Vector__XXX

BO_ 2566704382 EEC12: 8 Vector__XXX
 SG_ AFT2OutGasSnsrPwrSupply : 6|2@1+ (1,0) [0|3] "" Vector__XXX
 SG_ AFT2InGasSnsrPwrSupply : 4|2@1+ (1,0) [0|3] "" Vector__XXX
 SG_ AFT1OutGasSnsrPwrSupply : 2|2@1+ (1,0) [0|3] "" Vector__XXX
 SG_ AFT1InGasSnsrPwrSupply : 0|2@1+ (1,0) [0|3] "" Vector__XXX

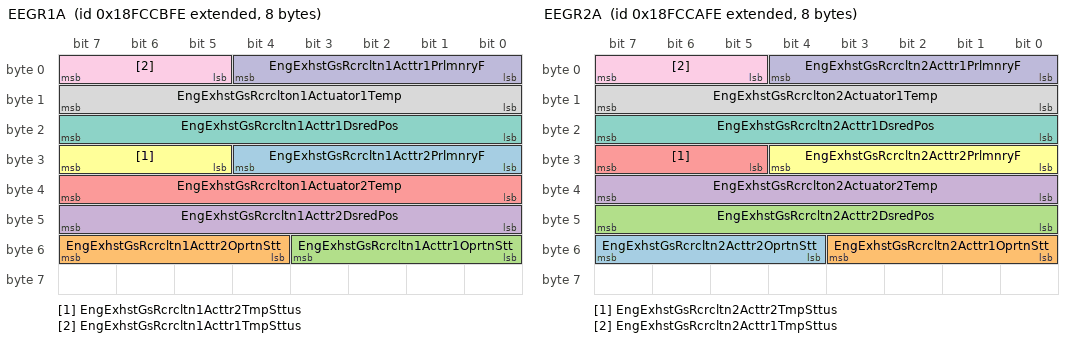
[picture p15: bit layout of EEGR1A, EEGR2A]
BO_ 2566704126 EEGR1A: 8 Vector__XXX
 SG_ EngExhstGsRcrcltn1Acttr2PrlmnryF : 24|5@1+ (1,0) [0|31] "" Vector__XXX
 SG_ EngExhstGsRcrcltn1Acttr2OprtnStt : 52|4@1+ (1,0) [0|15] "" Vector__XXX
 SG_ EngExhstGsRcrcltn1Acttr1OprtnStt : 48|4@1+ (1,0) [0|15] "" Vector__XXX
 SG_ EngExhstGsRcrcltn1Acttr2DsredPos : 40|8@1+ (0.4,0) [0|100] "%" Vector__XXX
 SG_ EngExhstGsRcrclton1Actuator2Temp : 32|8@1+ (1,-40) [-40|210] "°C" Vector__XXX
 SG_ EngExhstGsRcrcltn1Acttr2TmpSttus : 29|3@1+ (1,0) [0|7] "" Vector__XXX
 SG_ EngExhstGsRcrcltn1Acttr1DsredPos : 16|8@1+ (0.4,0) [0|100] "%" Vector__XXX
 SG_ EngExhstGsRcrclton1Actuator1Temp : 8|8@1+ (1,-40) [-40|210] "°C" Vector__XXX
 SG_ EngExhstGsRcrcltn1Acttr1TmpSttus : 5|3@1+ (1,0) [0|7] "" Vector__XXX
 SG_ EngExhstGsRcrcltn1Acttr1PrlmnryF : 0|5@1+ (1,0) [0|31] "" Vector__XXX

BO_ 2566703870 EEGR2A: 8 Vector__XXX
 SG_ EngExhstGsRcrcltn2Acttr2OprtnStt : 52|4@1+ (1,0) [0|15] "" Vector__XXX
 SG_ EngExhstGsRcrcltn2Acttr1OprtnStt : 48|4@1+ (1,0) [0|15] "" Vector__XXX
 SG_ EngExhstGsRcrcltn2Acttr2DsredPos : 40|8@1+ (0.4,0) [0|100] "%" Vector__XXX
 SG_ EngExhstGsRcrclton2Actuator2Temp : 32|8@1+ (1,-40) [-40|210] "°C" Vector__XXX
 SG_ EngExhstGsRcrcltn2Acttr2TmpSttus : 29|3@1+ (1,0) [0|7] "" Vector__XXX
 SG_ EngExhstGsRcrcltn2Acttr2PrlmnryF : 24|5@1+ (1,0) [0|31] "" Vector__XXX
 SG_ EngExhstGsRcrcltn2Acttr1DsredPos : 16|8@1+ (0.4,0) [0|100] "%" Vector__XXX
 SG_ EngExhstGsRcrclton2Actuator1Temp : 8|8@1+ (1,-40) [-40|210] "°C" Vector__XXX
 SG_ EngExhstGsRcrcltn2Acttr1TmpSttus : 5|3@1+ (1,0) [0|7] "" Vector__XXX
 SG_ EngExhstGsRcrcltn2Acttr1PrlmnryF : 0|5@1+ (1,0) [0|31] "" Vector__XXX

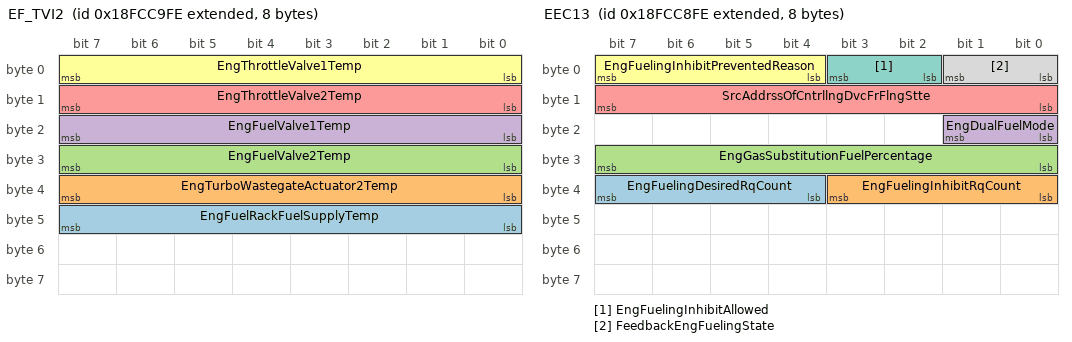
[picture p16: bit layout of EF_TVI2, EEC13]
BO_ 2566703614 EF_TVI2: 8 Vector__XXX
 SG_ EngFuelRackFuelSupplyTemp : 40|8@1+ (1,-40) [-40|210] "°C" Vector__XXX
 SG_ EngTurboWastegateActuator2Temp : 32|8@1+ (1,-40) [-40|210] "°C" Vector__XXX
 SG_ EngFuelValve2Temp : 24|8@1+ (1,-40) [-40|210] "°C" Vector__XXX
 SG_ EngFuelValve1Temp : 16|8@1+ (1,-40) [-40|210] "°C" Vector__XXX
 SG_ EngThrottleValve2Temp : 8|8@1+ (1,-40) [-40|210] "°C" Vector__XXX
 SG_ EngThrottleValve1Temp : 0|8@1+ (1,-40) [-40|210] "°C" Vector__XXX

BO_ 2566703358 EEC13: 8 Vector__XXX
 SG_ EngFuelingDesiredRqCount : 36|4@1+ (1,0) [0|15] "" Vector__XXX
 SG_ EngFuelingInhibitRqCount : 32|4@1+ (1,0) [0|15] "" Vector__XXX
 SG_ EngGasSubstitutionFuelPercentage : 24|8@1+ (0.5,0) [0|125] "%" Vector__XXX
 SG_ EngDualFuelMode : 16|2@1+ (1,0) [0|3] "" Vector__XXX
 SG_ SrcAddrssOfCntrllngDvcFrFlngStte : 8|8@1+ (1,0) [0|255] "" Vector__XXX
 SG_ EngFuelingInhibitPreventedReason : 4|4@1+ (1,0) [0|15] "" Vector__XXX
 SG_ EngFuelingInhibitAllowed : 2|2@1+ (1,0) [0|3] "" Vector__XXX
 SG_ FeedbackEngFuelingState : 0|2@1+ (1,0) [0|3] "" Vector__XXX

BO_ 2566702590 A1SCREGT2: 8 Vector__XXX
 SG_ IntmdTempPreliminaryFMI : 16|5@1+ (1,0) [0|31] "" Vector__XXX
 SG_ IntmdTemp : 0|16@1+ (0.03125,-273) [-273|1734.96875] "°C" Vector__XXX

BO_ 2566702334 A2SCREGT2: 8 Vector__XXX
 SG_ IntmdTempPreliminaryFMI : 16|5@1+ (1,0) [0|31] "" Vector__XXX
 SG_ IntmdTemp : 0|16@1+ (0.03125,-273) [-273|1734.96875] "°C" Vector__XXX

BO_ 2566702078 GFI4: 8 Vector__XXX
 SG_ SupplyGasMethanePercentage : 0|16@1+ (0.0025,0) [0|160.6375] "%" Vector__XXX

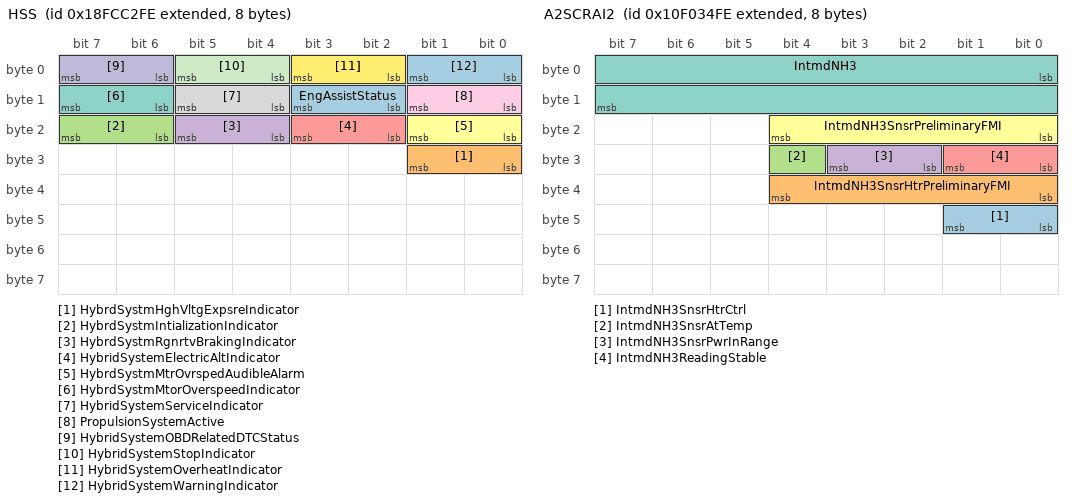
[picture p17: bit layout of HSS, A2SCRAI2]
BO_ 2566701822 HSS: 8 Vector__XXX
 SG_ EngAssistStatus : 10|2@1+ (1,0) [0|3] "" Vector__XXX
 SG_ HybrdSystmHghVltgExpsreIndicator : 24|2@1+ (1,0) [0|3] "" Vector__XXX
 SG_ HybrdSystmIntializationIndicator : 22|2@1+ (1,0) [0|3] "" Vector__XXX
 SG_ HybrdSystmRgnrtvBrakingIndicator : 20|2@1+ (1,0) [0|3] "" Vector__XXX
 SG_ HybridSystemElectricAltIndicator : 18|2@1+ (1,0) [0|3] "" Vector__XXX
 SG_ HybrdSystmMtrOvrspedAudibleAlarm : 16|2@1+ (1,0) [0|3] "" Vector__XXX
 SG_ HybrdSystmMtorOverspeedIndicator : 14|2@1+ (1,0) [0|3] "" Vector__XXX
 SG_ HybridSystemServiceIndicator : 12|2@1+ (1,0) [0|3] "" Vector__XXX
 SG_ PropulsionSystemActive : 8|2@1+ (1,0) [0|3] "" Vector__XXX
 SG_ HybridSystemOBDRelatedDTCStatus : 6|2@1+ (1,0) [0|3] "" Vector__XXX
 SG_ HybridSystemStopIndicator : 4|2@1+ (1,0) [0|3] "" Vector__XXX
 SG_ HybridSystemOverheatIndicator : 2|2@1+ (1,0) [0|3] "" Vector__XXX
 SG_ HybridSystemWarningIndicator : 0|2@1+ (1,0) [0|3] "" Vector__XXX

BO_ 2431661310 A2SCRAI2: 8 Vector__XXX
 SG_ IntmdNH3SnsrHtrCtrl : 40|2@1+ (1,0) [0|3] "" Vector__XXX
 SG_ IntmdNH3SnsrHtrPreliminaryFMI : 32|5@1+ (1,0) [0|31] "" Vector__XXX
 SG_ IntmdNH3SnsrAtTemp : 28|1@1+ (1,0) [0|1] "" Vector__XXX
 SG_ IntmdNH3SnsrPwrInRange : 26|2@1+ (1,0) [0|3] "" Vector__XXX
 SG_ IntmdNH3ReadingStable : 24|2@1+ (1,0) [0|3] "" Vector__XXX
 SG_ IntmdNH3SnsrPreliminaryFMI : 16|5@1+ (1,0) [0|31] "" Vector__XXX
 SG_ IntmdNH3 : 0|16@1+ (0.1,-200) [-200|6225.5] "ppm" Vector__XXX

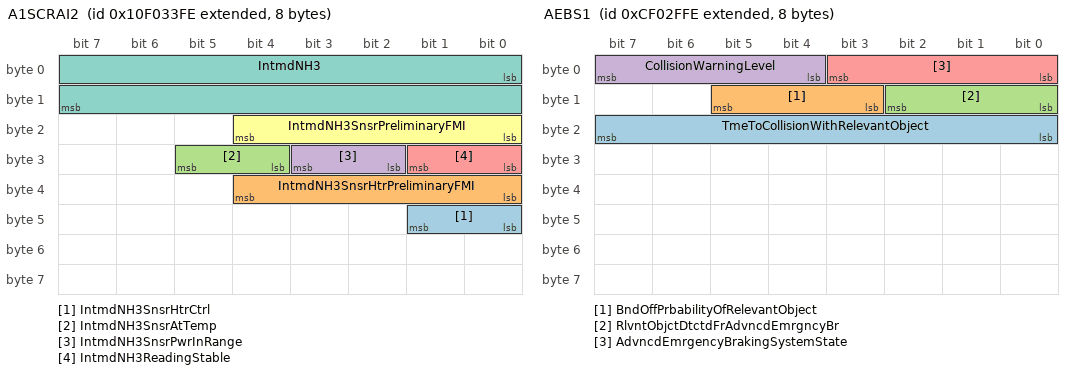
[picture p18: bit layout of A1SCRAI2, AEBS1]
BO_ 2431661054 A1SCRAI2: 8 Vector__XXX
 SG_ IntmdNH3SnsrHtrCtrl : 40|2@1+ (1,0) [0|3] "" Vector__XXX
 SG_ IntmdNH3SnsrHtrPreliminaryFMI : 32|5@1+ (1,0) [0|31] "" Vector__XXX
 SG_ IntmdNH3SnsrAtTemp : 28|2@1+ (1,0) [0|3] "" Vector__XXX
 SG_ IntmdNH3SnsrPwrInRange : 26|2@1+ (1,0) [0|3] "" Vector__XXX
 SG_ IntmdNH3ReadingStable : 24|2@1+ (1,0) [0|3] "" Vector__XXX
 SG_ IntmdNH3SnsrPreliminaryFMI : 16|5@1+ (1,0) [0|31] "" Vector__XXX
 SG_ IntmdNH3 : 0|16@1+ (0.1,-200) [-200|6225.5] "ppm" Vector__XXX

BO_ 2230334206 LDISP: 8 Vector__XXX
 SG_ LnrDsplcmntSnsrSnsrFigureOfMerit : 16|2@1+ (1,0) [0|3] "" Vector__XXX
 SG_ MeasuredLinearDisplacement : 0|16@1+ (0.1,0) [0|6425.5] "mm" Vector__XXX

BO_ 2230333950 WAND: 8 Vector__XXX
 SG_ WandSensorFigureOfMerit : 16|2@1+ (1,0) [0|3] "" Vector__XXX
 SG_ WandAngle : 0|16@1+ (0.002,-64) [-64|64.51] "deg" Vector__XXX

BO_ 2364551422 WS: 8 Vector__XXX
 SG_ WirelessSignalStrength1 : 48|8@1+ (0.5,-125) [-125|0] "dBm" Vector__XXX
 SG_ TransmitterID1 : 24|24@1+ (1,0) [0|16449635] "" Vector__XXX
 SG_ TransmitterCmdState : 20|4@1+ (1,0) [0|15] "" Vector__XXX
 SG_ WirelessRollingMessageCounter : 0|16@1+ (1,0) [0|64255] "" Vector__XXX

BO_ 2364551166 AEBS1: 8 Vector__XXX
 SG_ TmeToCollisionWithRelevantObject : 16|8@1+ (0.05,0) [0|12.5] "s" Vector__XXX
 SG_ BndOffPrbabilityOfRelevantObject : 11|3@1+ (1,0) [0|7] "" Vector__XXX
 SG_ RlvntObjctDtctdFrAdvncdEmrgncyBr : 8|3@1+ (1,0) [0|7] "" Vector__XXX
 SG_ CollisionWarningLevel : 4|4@1+ (1,0) [0|15] "" Vector__XXX
 SG_ AdvncdEmrgencyBrakingSystemState : 0|4@1+ (1,0) [0|15] "" Vector__XXX

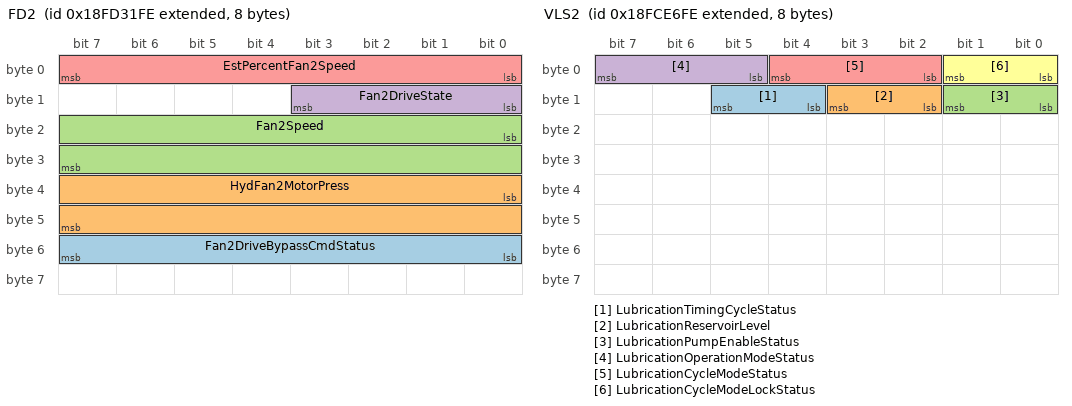
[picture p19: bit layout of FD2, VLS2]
BO_ 2566730238 FD2: 8 Vector__XXX
 SG_ Fan2DriveBypassCmdStatus : 48|8@1+ (0.4,0) [0|100] "%" Vector__XXX
 SG_ HydFan2MotorPress : 32|16@1+ (0.5,0) [0|32127.5] "kPa" Vector__XXX
 SG_ Fan2Speed : 16|16@1+ (0.125,0) [0|8031.875] "rpm" Vector__XXX
 SG_ Fan2DriveState : 8|4@1+ (1,0) [0|15] "" Vector__XXX
 SG_ EstPercentFan2Speed : 0|8@1+ (0.4,0) [0|100] "%" Vector__XXX

BO_ 2566711038 VLS2: 8 Vector__XXX
 SG_ LubricationTimingCycleStatus : 12|2@1+ (1,0) [0|3] "" Vector__XXX
 SG_ LubricationReservoirLevel : 10|2@1+ (1,0) [0|3] "" Vector__XXX
 SG_ LubricationPumpEnableStatus : 8|2@1+ (1,0) [0|3] "" Vector__XXX
 SG_ LubricationOperationModeStatus : 5|3@1+ (1,0) [0|7] "" Vector__XXX
 SG_ LubricationCycleModeStatus : 2|3@1+ (1,0) [0|7] "" Vector__XXX
 SG_ LubricationCycleModeLockStatus : 0|2@1+ (1,0) [0|3] "" Vector__XXX

BO_ 2566710782 HOP: 8 Vector__XXX
 SG_ HydOilTemp : 48|16@1+ (0.03125,-273) [-273|1734.96875] "°C" Vector__XXX
 SG_ HydOilRelativeDielectricity : 32|16@1+ (0.0001220703125,0) [0|7.844] "" Vector__XXX
 SG_ HydOilDensity : 16|16@1+ (3.052E-005,0) [0|1.961] "g/cc" Vector__XXX
 SG_ HydOilDynamicViscosity : 0|16@1+ (0.015625,0) [0|1003.984375] "Cp" Vector__XXX

BO_ 2566710526 EFP: 8 Vector__XXX
 SG_ EngFuelTemp : 48|16@1+ (0.03125,-273) [-273|1734.96875] "°C" Vector__XXX
 SG_ EngFuelDielectricity : 32|16@1+ (0.0001220703125,0) [0|7.844] "" Vector__XXX
 SG_ EngFuelDensity : 16|16@1+ (3.052E-005,0) [0|1.961] "g/cc" Vector__XXX
 SG_ EngFuelDynamicViscosity : 0|16@1+ (0.015625,0) [0|1003.984375] "Cp" Vector__XXX

BO_ 2432492542 EBCC: 8 Vector__XXX
 SG_ DsredEngTurbo2TurbineOutletPress : 32|8@1+ (2,0) [0|500] "kPa" Vector__XXX
 SG_ EngTurbo2TurbineOutletPress : 24|8@1+ (2,0) [0|500] "kPa" Vector__XXX
 SG_ EngExhaustBrakeActuatorCmd : 16|8@1+ (0.4,0) [0|100] "%" Vector__XXX
 SG_ DsredEngTurbo1TurbineOutletPress : 8|8@1+ (2,0) [0|500] "kPa" Vector__XXX
 SG_ EngTurbo1TurbineOutletPress : 0|8@1+ (2,0) [0|500] "kPa" Vector__XXX

CM_ BO_ 2566705662 "Active Service Only DTCs";
CM_ SG_ 2566705662 DTC1 "Diagnostic Trouble Code";
CM_ SG_ 2566705662 FlashProtectLamp "This parameter provides the capability to flash the engine protect lamp


00 - Slow Flash (1 Hz, 50 % duty cycle)
01 - Fast Flash (2 Hz or faster, 50% duty cycle)
10 - Reserved
11 - Unavailable / Do Not Flash";
CM_ SG_ 2566705662 FlashAmberWarningLamp "This parameter provides the capability to flash the AWL

00 - Slow Flash (1 Hz, 50 % duty cycle)
01 - Fast Flash (2 Hz or faster, 50% duty cycle)
10 - Reserved
11 - Unavailable / Do Not Flash";
CM_ SG_ 2566705662 FlashRedStopLamp "This parameter provides the capability to flash the RSL


00 - Slow Flash (1 Hz, 50 % duty cycle)
01 - Fast Flash (2 Hz or faster, 50% duty cycle)
10 - Reserved
11 - Unavailable / Do Not Flash";
CM_ SG_ 2566705662 FlashMalfuncIndicatorLamp "This parameter provides the capability to flash the MIL
00 - Slow Flash (1 Hz, 50 % duty cycle)
01 - Fast Flash (2 Hz or faster, 50% duty cycle)
10 - Class C DTC
11 - Unavailable / Do Not Flash
Note:  State 10 is for WWH OBD discriminatory ...";
CM_ SG_ 2566705662 ProtectLampStatus "This lamp is used to relay trouble code information that is reporting a problem with a vehicle system that is most probably not electronic subsystem related. For instance, engine coolant temperature is exceeding its prescribed temperature range.
00 ...";
CM_ SG_ 2566705662 AmberWarningLampStatus "This lamp is used to relay trouble code information that is reporting a problem with the vehicle system but the vehicle need not be immediately stopped. 

00     Lamp Off
01     Lamp On
10     Reserved
11     Not available";
CM_ SG_ 2566705662 RedStopLampState "This lamp is used to relay trouble code information that is of a severe enough condition that it warrants stopping the vehicle.

00     Lamp Off
01     Lamp On
10     Reserved
11     Not available";
CM_ SG_ 2566705662 MalfunctionIndicatorLampStatus "A lamp used to relay only emissions-related trouble code information. This lamp is only illuminated when there is an emission-related trouble code active.
00     Lamp Off
01     Lamp On
10     Short MIL for WWH OBD
11     Not available
Note ...";
CM_ SG_ 2566705662 DTC5 "Diagnostic Trouble Code";
CM_ SG_ 2566705662 DTC4 "Diagnostic Trouble Code";
CM_ SG_ 2566705662 DTC3 "Diagnostic Trouble Code";
CM_ SG_ 2566705662 DTC2 "Diagnostic Trouble Code";
CM_ BO_ 2566706174 "Diagnostic Data Clear/Reset for All Service Only DTCs
All of the diagnostic information pertaining to the active service only diagnostic trouble codes and previously active diagnostic trouble codes should be erased as well as the DTCs.";
CM_ BO_ 2349465342 "Static Roll Angle Sensor Information - Contains Static Roll Angle Data and Status of the Static Roll Angle Sensor";
CM_ SG_ 2349465342 StaticRollAngleStatus_5583 "Status of the transmitted roll angle data.

000 = Sensor Busy
001 = Sensor OK
010 = Sensor Defect
011 = Sensor Reboots
100 = Angle Data Invalid
101 = Reserved
110 = Error
111 = Not available";
CM_ SG_ 2349465342 StaticRollAngle_5582 "The measured static roll angle between the vehicle y-axis and the ground plane about the X-axis.  The sign of the roll angle is determined in accordance to the right-hand rule about the X-axis, as specified in SAE J670.  Roll angle is the same for ...";
CM_ BO_ 2498777086 "Engine Cylinder 2 Combustion Average Information
Used to transmit the average of combustion parameters of Engine Cylinder 2.
This PGN is transmitted at a defined ratio of the engine speed. The transmission rate is dependent on
SPN 6394 - Number ...";
CM_ SG_ 2498777086 EngCyl2AverageCombustionDuration "Average duration of combustion calculated over defined number of combustion cycles for engine cylinder 2 with reference to the crank angle.  Combustion duration is the difference between end of combustion and start of combustion expressed, in this ...";
CM_ SG_ 2498777086 EngCyl2AvrgCntrOfCmbustionTiming "Average timing calculated over defined number of combustion cycles for the center of combustion in engine cylinder 2 with reference to the crank angle.  Center of Combustion is used to indicate the combustion efficiency.  When the combustion happens ...";
CM_ SG_ 2498777086 EngCyl2AvrgStrtOfCmbustionTiming "Average start of combustion timing calculated over defined number of combustion cycles for engine cylinder 2 with reference to the crank angle.  When the combustion happens after the TDC (Top Dead Center) of this cylinder, the timing is referred in ...";
CM_ SG_ 2498777086 EngCyl2IndctedMeanEffectivePress "Average cylinder pressure calculated over defined number of combustion cycles for engine cylinder 2.  Negative range is to cover thermodynamic behavior during misfire.";
CM_ BO_ 2498776830 "Engine Cylinder 1 Combustion Average Information
Used to transmit the average of combustion parameters of Engine Cylinder 1.
This PGN is transmitted at a defined ratio of the engine speed. The transmission rate is dependent on
SPN 6394 - Number ...";
CM_ SG_ 2498776830 EngCyl1AverageCombustionDuration "Average duration of combustion calculated over defined number of combustion cycles for engine cylinder 1 with reference to the crank angle.  Combustion duration is the difference between end of combustion and start of combustion expressed, in this ...";
CM_ SG_ 2498776830 EngCyl1AvrgCntrOfCmbustionTiming "Average timing calculated over defined number of combustion cycles for the center of combustion in engine cylinder 1 with reference to the crank angle.  Center of Combustion is used to indicate the combustion efficiency.  When the combustion happens ...";
CM_ SG_ 2498776830 EngCyl1AvrgStrtOfCmbustionTiming "Average start of combustion timing calculated over defined number of combustion cycles for engine cylinder 1 with reference to the crank angle.  When the combustion happens after the TDC (Top Dead Center) of this cylinder, the timing is referred in ...";
CM_ SG_ 2498776830 EngCyl1IndctedMeanEffectivePress "Average cylinder pressure calculated over defined number of combustion cycles for engine cylinder 1.   Negative range is to cover thermodynamic behavior during misfire.";
CM_ BO_ 2364558846 "Engine Cylinder 20 Combustion Information
Used to communicate combustion information of Engine Cylinder 20. The PGN is transmitted at the end of every combustion in Cylinder 20.";
CM_ SG_ 2364558846 MaxPressIncreaseRate "The maximum slope, in degrees of crank angle, of the pressure increase in engine cylinder 20 during the combustion cycle.";
CM_ SG_ 2364558846 LowFreqKnockLvl "Indicates the level of low frequency knock for engine cylinder 20. This knock occurs at frequencies below the typical knock level reported on SPNs 1371 & 6474.  The level of low frequency knock is reported using a relative scale where 0% is least ...";
CM_ SG_ 2364558846 EngCyl20PrssSensorPreliminaryFMI "Used to identify the applicable J1939-73 FMI detected in the engine cylinder 20 pressure sensor.  When there is no failure FMI 31 is sent. In the case of multiple failures the most severe is communicated.";
CM_ SG_ 2364558846 EngCyl20SynchronousKnockLevel "Used to indicate the level of knock for engine cylinder 20. The level of knock is reported using a relative scale where 0% is least level of knock, and increasing levels indicate more knock until 100% indicates the most severe level of knock allowed ...";
CM_ SG_ 2364558846 EngCyl20PeakPress "Peak pressure in engine cylinder 20 in combustion cycle.";
CM_ SG_ 2364558846 EngCyl20HeatRelease "The amount of heat produced during combustion in engine cylinder 20.  The negative range is to cover thermodynamic behavior during misfire.";
CM_ BO_ 2364558590 "Engine Cylinder 19 Combustion Information
Used to communicate combustion information of Engine Cylinder 19. The PGN is transmitted at the end of every combustion in Cylinder 19.";
CM_ SG_ 2364558590 MaxPressIncreaseRate "The maximum slope, in degrees of crank angle, of the pressure increase in engine cylinder 19 during the combustion cycle.";
CM_ SG_ 2364558590 LowFreqKnockLvl "Indicates the level of low frequency knock for engine cylinder 19. This knock occurs at frequencies below the typical knock level reported on SPNs 1370 & 6470.  The level of low frequency knock is reported using a relative scale where 0% is least ...";
CM_ SG_ 2364558590 EngCyl19PrssSensorPreliminaryFMI "Used to identify the applicable J1939-73 FMI detected in the engine cylinder 19 pressure sensor.  When there is no failure FMI 31 is sent. In the case of multiple failures the most severe is communicated.";
CM_ SG_ 2364558590 EngCyl19SynchronousKnockLevel "Used to indicate the level of knock for engine cylinder 19. The level of knock is reported using a relative scale where 0% is least level of knock, and increasing levels indicate more knock until 100% indicates the most severe level of knock allowed ...";
CM_ SG_ 2364558590 EngCyl19PeakPress "Peak pressure in engine cylinder 19 in combustion cycle.";
CM_ SG_ 2364558590 EngCyl19HeatRelease "The amount of heat produced during combustion in engine cylinder 19.  The negative range is to cover thermodynamic behavior during misfire.";
CM_ BO_ 2364558334 "Engine Cylinder 18 Combustion Information
Used to communicate combustion information of Engine Cylinder 18. The PGN is transmitted at the end of every combustion in Cylinder 18.";
CM_ SG_ 2364558334 MaxPressIncreaseRate "The maximum slope, in degrees of crank angle, of the pressure increase in engine cylinder 18 during the combustion cycle.";
CM_ SG_ 2364558334 LowFreqKnockLvl "Indicates the level of low frequency knock for engine cylinder 18. This knock occurs at frequencies below the typical knock level reported on SPNs 1369 & 6466.  The level of low frequency knock is reported using a relative scale where 0% is least ...";
CM_ SG_ 2364558334 EngCyl18PrssSensorPreliminaryFMI "Used to identify the applicable J1939-73 FMI detected in the engine cylinder 18 pressure sensor.  When there is no failure FMI 31 is sent. In the case of multiple failures the most severe is communicated.";
CM_ SG_ 2364558334 EngCyl18SynchronousKnockLevel "Used to indicate the level of knock for engine cylinder 18. The level of knock is reported using a relative scale where 0% is least level of knock, and increasing levels indicate more knock until 100% indicates the most severe level of knock allowed ...";
CM_ SG_ 2364558334 EngCyl18PeakPress "Peak pressure in engine cylinder 18 in combustion cycle.";
CM_ SG_ 2364558334 EngCyl18HeatRelease "The amount of heat produced during combustion in engine cylinder 18.  The negative range is to cover thermodynamic behavior during misfire.";
CM_ BO_ 2364558078 "Engine Cylinder 17 Combustion Information
Used to communicate combustion information of Engine Cylinder 17. The PGN is transmitted at the end of every combustion in Cylinder 17.";
CM_ SG_ 2364558078 MaxPressIncreaseRate "The maximum slope, in degrees of crank angle, of the pressure increase in engine cylinder 17 during the combustion cycle.";
CM_ SG_ 2364558078 LowFreqKnockLvl "Indicates the level of low frequency knock for engine cylinder 17. This knock occurs at frequencies below the typical knock level reported on SPNs 1368 & 6462.  The level of low frequency knock is reported using a relative scale where 0% is least ...";
CM_ SG_ 2364558078 EngCyl17PrssSensorPreliminaryFMI "Used to identify the applicable J1939-73 FMI detected in the engine cylinder 17 pressure sensor.  When there is no failure FMI 31 is sent. In the case of multiple failures the most severe is communicated.";
CM_ SG_ 2364558078 EngCyl17SynchronousKnockLevel "Used to indicate the level of knock for engine cylinder 17. The level of knock is reported using a relative scale where 0% is least level of knock, and increasing levels indicate more knock until 100% indicates the most severe level of knock allowed ...";
CM_ SG_ 2364558078 EngCyl17PeakPress "Peak pressure in engine cylinder 17 in combustion cycle.";
CM_ SG_ 2364558078 EngCyl17HeatRelease "The amount of heat produced during combustion in engine cylinder 17.  The negative range is to cover thermodynamic behavior during misfire.";
CM_ BO_ 2364557822 "Engine Cylinder 16 Combustion Information
Used to communicate combustion information of Engine Cylinder 16. The PGN is transmitted at the end of every combustion in Cylinder 16.";
CM_ SG_ 2364557822 MaxPressIncreaseRate "The maximum slope, in degrees of crank angle, of the pressure increase in engine cylinder 16 during the combustion cycle.";
CM_ SG_ 2364557822 LowFreqKnockLvl "Indicates the level of low frequency knock for engine cylinder 16. This knock occurs at frequencies below the typical knock level reported on SPNs 1367 & 6458.  The level of low frequency knock is reported using a relative scale where 0% is least ...";
CM_ SG_ 2364557822 EngCyl16PrssSensorPreliminaryFMI "Used to identify the applicable J1939-73 FMI detected in the engine cylinder 16 pressure sensor.  When there is no failure FMI 31 is sent. In the case of multiple failures the most severe is communicated.";
CM_ SG_ 2364557822 EngCyl16SynchronousKnockLevel "Used to indicate the level of knock for engine cylinder 16. The level of knock is reported using a relative scale where 0% is least level of knock, and increasing levels indicate more knock until 100% indicates the most severe level of knock allowed ...";
CM_ SG_ 2364557822 EngCyl16PeakPress "Peak pressure in engine cylinder 16 in combustion cycle.";
CM_ SG_ 2364557822 EngCyl16HeatRelease "The amount of heat produced during combustion in engine cylinder 16.  The negative range is to cover thermodynamic behavior during misfire.";
CM_ BO_ 2364557566 "Engine Cylinder 15 Combustion Information
Used to communicate combustion information of Engine Cylinder 15. The PGN is transmitted at the end of every combustion in Cylinder 15.";
CM_ SG_ 2364557566 MaxPressIncreaseRate "The maximum slope, in degrees of crank angle, of the pressure increase in engine cylinder 15 during the combustion cycle.";
CM_ SG_ 2364557566 LowFreqKnockLvl "Indicates the level of low frequency knock for engine cylinder 15. This knock occurs at frequencies below the typical knock level reported on SPNs 1366 & 6454.  The level of low frequency knock is reported using a relative scale where 0% is least ...";
CM_ SG_ 2364557566 EngCyl15PrssSensorPreliminaryFMI "Used to identify the applicable J1939-73 FMI detected in the engine cylinder 15 pressure sensor.  When there is no failure FMI 31 is sent. In the case of multiple failures the most severe is communicated.";
CM_ SG_ 2364557566 EngCyl15SynchronousKnockLevel "Used to indicate the level of knock for engine cylinder 15. The level of knock is reported using a relative scale where 0% is least level of knock, and increasing levels indicate more knock until 100% indicates the most severe level of knock allowed ...";
CM_ SG_ 2364557566 EngCyl15PeakPress "Peak pressure in engine cylinder 15 in combustion cycle.";
CM_ SG_ 2364557566 EngCyl15HeatRelease "The amount of heat produced during combustion in engine cylinder 15.  The negative range is to cover thermodynamic behavior during misfire.";
CM_ BO_ 2364557310 "Engine Cylinder 14 Combustion Information
Used to communicate combustion information of Engine Cylinder 14. The PGN is transmitted at the end of every combustion in Cylinder 14.";
CM_ SG_ 2364557310 MaxPressIncreaseRate "The maximum slope, in degrees of crank angle, of the pressure increase in engine cylinder 14 during the combustion cycle.";
CM_ SG_ 2364557310 LowFreqKnockLvl "Indicates the level of low frequency knock for engine cylinder 14. This knock occurs at frequencies below the typical knock level reported on SPNs 1365 & 6450.  The level of low frequency knock is reported using a relative scale where 0% is least ...";
CM_ SG_ 2364557310 EngCyl14PrssSensorPreliminaryFMI "Used to identify the applicable J1939-73 FMI detected in the engine cylinder 14 pressure sensor.  When there is no failure FMI 31 is sent. In the case of multiple failures the most severe is communicated.";
CM_ SG_ 2364557310 EngCyl14SynchronousKnockLevel "Used to indicate the level of knock for engine cylinder 14. The level of knock is reported using a relative scale where 0% is least level of knock, and increasing levels indicate more knock until 100% indicates the most severe level of knock allowed ...";
CM_ SG_ 2364557310 EngCyl14PeakPress "Peak pressure in engine cylinder 14 in combustion cycle.";
CM_ SG_ 2364557310 EngCyl14HeatRelease "The amount of heat produced during combustion in engine cylinder 14.  The negative range is to cover thermodynamic behavior during misfire.";
CM_ BO_ 2364557054 "Engine Cylinder 13 Combustion Information
Used to communicate combustion information of Engine Cylinder 13. The PGN is transmitted at the end of every combustion in Cylinder 13.";
CM_ SG_ 2364557054 MaxPressIncreaseRate "The maximum slope, in degrees of crank angle, of the pressure increase in engine cylinder 13 during the combustion cycle.";
CM_ SG_ 2364557054 LowFreqKnockLvl "Indicates the level of low frequency knock for engine cylinder 13. This knock occurs at frequencies below the typical knock level reported on SPNs 1364 & 6446.  The level of low frequency knock is reported using a relative scale where 0% is least ...";
CM_ SG_ 2364557054 EngCyl13PrssSensorPreliminaryFMI "Used to identify the applicable J1939-73 FMI detected in the engine cylinder 13 pressure sensor.  When there is no failure FMI 31 is sent. In the case of multiple failures the most severe is communicated.";
CM_ SG_ 2364557054 EngCyl13SynchronousKnockLevel "Used to indicate the level of knock for engine cylinder 13. The level of knock is reported using a relative scale where 0% is least level of knock, and increasing levels indicate more knock until 100% indicates the most severe level of knock allowed ...";
CM_ SG_ 2364557054 EngCyl13PeakPress "Peak pressure in engine cylinder 13 in combustion cycle.";
CM_ SG_ 2364557054 EngCyl13HeatRelease "The amount of heat produced during combustion in engine cylinder 13.  The negative range is to cover thermodynamic behavior during misfire.";
CM_ BO_ 2364556798 "Engine Cylinder 12 Combustion Information
Used to communicate combustion information of Engine Cylinder 12. The PGN is transmitted at the end of every combustion in Cylinder 12.";
CM_ SG_ 2364556798 MaxPressIncreaseRate "The maximum slope, in degrees of crank angle, of the pressure increase in engine cylinder 12 during the combustion cycle.";
CM_ SG_ 2364556798 LowFreqKnockLvl "Indicates the level of low frequency knock for engine cylinder 12. This knock occurs at frequencies below the typical knock level reported on SPNs 1363 & 6442.  The level of low frequency knock is reported using a relative scale where 0% is least ...";
CM_ SG_ 2364556798 EngCyl12PrssSensorPreliminaryFMI "Used to identify the applicable J1939-73 FMI detected in the engine cylinder 12 pressure sensor.  When there is no failure FMI 31 is sent. In the case of multiple failures the most severe is communicated.";
CM_ SG_ 2364556798 EngCyl12SynchronousKnockLevel "Used to indicate the level of knock for engine cylinder 12. The level of knock is reported using a relative scale where 0% is least level of knock, and increasing levels indicate more knock until 100% indicates the most severe level of knock allowed ...";
CM_ SG_ 2364556798 EngCyl12PeakPress "Peak pressure in engine cylinder 12 in combustion cycle.";
CM_ SG_ 2364556798 EngCyl12HeatRelease "The amount of heat produced during combustion in engine cylinder 12.  The negative range is to cover thermodynamic behavior during misfire.";
CM_ BO_ 2364556542 "Engine Cylinder 11 Combustion Information
Used to communicate combustion information of Engine Cylinder 11. The PGN is transmitted at the end of every combustion in Cylinder 11.";
CM_ SG_ 2364556542 MaxPressIncreaseRate "The maximum slope, in degrees of crank angle, of the pressure increase in engine cylinder 11 during the combustion cycle.";
CM_ SG_ 2364556542 LowFreqKnockLvl "Indicates the level of low frequency knock for engine cylinder 11. This knock occurs at frequencies below the typical knock level reported on SPNs 1362 & 6438.  The level of low frequency knock is reported using a relative scale where 0% is least ...";
CM_ SG_ 2364556542 EngCyl11PrssSensorPreliminaryFMI "Used to identify the applicable J1939-73 FMI detected in the engine cylinder 11 pressure sensor.  When there is no failure FMI 31 is sent. In the case of multiple failures the most severe is communicated.";
CM_ SG_ 2364556542 EngCyl11SynchronousKnockLevel "Used to indicate the level of knock for engine cylinder 11. The level of knock is reported using a relative scale where 0% is least level of knock, and increasing levels indicate more knock until 100% indicates the most severe level of knock allowed ...";
CM_ SG_ 2364556542 EngCyl11PeakPress "Peak pressure in engine cylinder 11 in combustion cycle.";
CM_ SG_ 2364556542 EngCyl11HeatRelease "The amount of heat produced during combustion in engine cylinder 11.  The negative range is to cover thermodynamic behavior during misfire.";
CM_ BO_ 2364556286 "Engine Cylinder 10 Combustion Information
Used to communicate combustion information of Engine Cylinder 10. The PGN is transmitted at the end of every combustion in Cylinder 10.";
CM_ SG_ 2364556286 MaxPressIncreaseRate "The maximum slope, in degrees of crank angle, of the pressure increase in engine cylinder 10 during the combustion cycle.";
CM_ SG_ 2364556286 LowFreqKnockLvl "Indicates the level of low frequency knock for engine cylinder 10. This knock occurs at frequencies below the typical knock level reported on SPNs 1361 & 6434.  The level of low frequency knock is reported using a relative scale where 0% is least ...";
CM_ SG_ 2364556286 EngCyl10PrssSensorPreliminaryFMI "Used to identify the applicable J1939-73 FMI detected in the engine cylinder 10 pressure sensor.  When there is no failure FMI 31 is sent. In the case of multiple failures the most severe is communicated.";
CM_ SG_ 2364556286 EngCyl10SynchronousKnockLevel "Used to indicate the level of knock for engine cylinder 10. The level of knock is reported using a relative scale where 0% is least level of knock, and increasing levels indicate more knock until 100% indicates the most severe level of knock allowed ...";
CM_ SG_ 2364556286 EngCyl10PeakPress "Peak pressure in engine cylinder 10 in combustion cycle.";
CM_ SG_ 2364556286 EngCyl10HeatRelease "The amount of heat produced during combustion in engine cylinder 10.  The negative range is to cover thermodynamic behavior during misfire.";
CM_ BO_ 2364556030 "Engine Cylinder 9 Combustion Information
Used to communicate combustion information of Engine Cylinder 9. The PGN is transmitted at the end of every combustion in Cylinder 9.";
CM_ SG_ 2364556030 MaxPressIncreaseRate "The maximum slope, in degrees of crank angle, of the pressure increase in engine cylinder 9 during the combustion cycle.";
CM_ SG_ 2364556030 LowFreqKnockLvl "Indicates the level of low frequency knock for engine cylinder 9. This knock occurs at frequencies below the typical knock level reported on SPNs 1360 & 6430.  The level of low frequency knock is reported using a relative scale where 0% is least ...";
CM_ SG_ 2364556030 EngCyl9PressSensorPreliminaryFMI "Used to identify the applicable J1939-73 FMI detected in the engine cylinder 9 pressure sensor.  When there is no failure FMI 31 is sent. In the case of multiple failures the most severe is communicated.";
CM_ SG_ 2364556030 EngCyl9SynchronousKnockLevel "Used to indicate the level of knock for engine cylinder 9. The level of knock is reported using a relative scale where 0% is least level of knock, and increasing levels indicate more knock until 100% indicates the most severe level of knock allowed ...";
CM_ SG_ 2364556030 EngCyl9PeakPress "Peak pressure in engine cylinder 9 in combustion cycle.";
CM_ SG_ 2364556030 EngCyl9HeatRelease "The amount of heat produced during combustion in engine cylinder 9.  The negative range is to cover thermodynamic behavior during misfire.";
CM_ BO_ 2364555774 "Engine Cylinder 8 Combustion Information
Used to communicate combustion information of Engine Cylinder 8. The PGN is transmitted at the end of every combustion in Cylinder 8.";
CM_ SG_ 2364555774 MaxPressIncreaseRate "The maximum slope, in degrees of crank angle, of the pressure increase in engine cylinder 8 during the combustion cycle.";
CM_ SG_ 2364555774 LowFreqKnockLvl "Indicates the level of low frequency knock for engine cylinder 8. This knock occurs at frequencies below the typical knock level reported on SPNs 1359 & 6426.  The level of low frequency knock is reported using a relative scale where 0% is least ...";
CM_ SG_ 2364555774 EngCyl8PressSensorPreliminaryFMI "Used to identify the applicable J1939-73 FMI detected in the engine cylinder 8 pressure sensor.  When there is no failure FMI 31 is sent. In the case of multiple failures the most severe is communicated.";
CM_ SG_ 2364555774 EngCyl8SynchronousKnockLevel "Used to indicate the level of knock for engine cylinder 8. The level of knock is reported using a relative scale where 0% is least level of knock, and increasing levels indicate more knock until 100% indicates the most severe level of knock allowed ...";
CM_ SG_ 2364555774 EngCyl8PeakPress "Peak pressure in engine cylinder 8 in combustion cycle.";
CM_ SG_ 2364555774 EngCyl8HeatRelease "The amount of heat produced during combustion in engine cylinder 8.  The negative range is to cover thermodynamic behavior during misfire.";
CM_ BO_ 2364555518 "Engine Cylinder 7 Combustion Information
Used to communicate combustion information of Engine Cylinder 7. The PGN is transmitted at the end of every combustion in Cylinder 7.";
CM_ SG_ 2364555518 MaxPressIncreaseRate "The maximum slope, in degrees of crank angle, of the pressure increase in engine cylinder 7 during the combustion cycle.";
CM_ SG_ 2364555518 LowFreqKnockLvl "Indicates the level of low frequency knock for engine cylinder 7. This knock occurs at frequencies below the typical knock level reported on SPNs 1358 & 6422.  The level of low frequency knock is reported using a relative scale where 0% is least ...";
CM_ SG_ 2364555518 EngCyl7PressSensorPreliminaryFMI "Used to identify the applicable J1939-73 FMI detected in the engine cylinder 7 pressure sensor.  When there is no failure FMI 31 is sent. In the case of multiple failures the most severe is communicated.";
CM_ SG_ 2364555518 EngCyl7SynchronousKnockLevel "Used to indicate the level of knock for engine cylinder 7. The level of knock is reported using a relative scale where 0% is least level of knock, and increasing levels indicate more knock until 100% indicates the most severe level of knock allowed ...";
CM_ SG_ 2364555518 EngCyl7PeakPress "Peak pressure in engine cylinder 7 in combustion cycle.";
CM_ SG_ 2364555518 EngCyl7HeatRelease "The amount of heat produced during combustion in engine cylinder 7.  The negative range is to cover thermodynamic behavior during misfire.";
CM_ BO_ 2364555262 "Engine Cylinder 6 Combustion Information
Used to communicate combustion information of Engine Cylinder 6. The PGN is transmitted at the end of every combustion in Cylinder 6.";
CM_ SG_ 2364555262 MaxPressIncreaseRate "The maximum slope, in degrees of crank angle, of the pressure increase in engine cylinder 6 during the combustion cycle.";
CM_ SG_ 2364555262 LowFreqKnockLvl "Indicates the level of low frequency knock for engine cylinder 6. This knock occurs at frequencies below the typical knock level reported on SPNs 1357 & 6418.  The level of low frequency knock is reported using a relative scale where 0% is least ...";
CM_ SG_ 2364555262 EngCyl6PressSensorPreliminaryFMI "Used to identify the applicable J1939-73 FMI detected in the engine cylinder 6 pressure sensor.  When there is no failure FMI 31 is sent. In the case of multiple failures the most severe is communicated.";
CM_ SG_ 2364555262 EngCyl6SynchronousKnockLevel "Used to indicate the level of knock for engine cylinder 6. The level of knock is reported using a relative scale where 0% is least level of knock, and increasing levels indicate more knock until 100% indicates the most severe level of knock allowed ...";
CM_ SG_ 2364555262 EngCyl6PeakPress "Peak pressure in engine cylinder 6 in combustion cycle.";
CM_ SG_ 2364555262 EngCyl6HeatRelease "The amount of heat produced during combustion in engine cylinder 6.  The negative range is to cover thermodynamic behavior during misfire.";
CM_ BO_ 2364555006 "Engine Cylinder 5 Combustion Information
Used to communicate combustion information of Engine Cylinder 5. The PGN is transmitted at the end of every combustion in Cylinder 5.";
CM_ SG_ 2364555006 MaxPressIncreaseRate "The maximum slope, in degrees of crank angle, of the pressure increase in engine cylinder 5 during the combustion cycle.";
CM_ SG_ 2364555006 LowFreqKnockLvl "Indicates the level of low frequency knock for engine cylinder 5. This knock occurs at frequencies below the typical knock level reported on SPNs 1356 & 6414.  The level of low frequency knock is reported using a relative scale where 0% is least ...";
CM_ SG_ 2364555006 EngCyl5PressSensorPreliminaryFMI "Used to identify the applicable J1939-73 FMI detected in the engine cylinder 5 pressure sensor.  When there is no failure FMI 31 is sent. In the case of multiple failures the most severe is communicated.";
CM_ SG_ 2364555006 EngCyl5SynchronousKnockLevel "Used to indicate the level of knock for engine cylinder 6. The level of knock is reported using a relative scale where 0% is least level of knock, and increasing levels indicate more knock until 100% indicates the most severe level of knock allowed ...";
CM_ SG_ 2364555006 EngCyl5PeakPress "Peak pressure in engine cylinder 5 in combustion cycle.";
CM_ SG_ 2364555006 EngCyl5HeatRelease "The amount of heat produced during combustion in engine cylinder 5.  The negative range is to cover thermodynamic behavior during misfire.";
CM_ BO_ 2364554750 "Engine Cylinder 4 Combustion Information
Used to communicate combustion information of Engine Cylinder 4. The PGN is transmitted at the end of every combustion in Cylinder 4.";
CM_ SG_ 2364554750 MaxPressIncreaseRate "The maximum slope, in degrees of crank angle, of the pressure increase in engine cylinder 4 during the combustion cycle.";
CM_ SG_ 2364554750 LowFreqKnockLvl "Indicates the level of low frequency knock for engine cylinder 4. This knock occurs at frequencies below the typical knock level reported on SPNs 1355 & 6410.  The level of low frequency knock is reported using a relative scale where 0% is least ...";
CM_ SG_ 2364554750 EngCyl4PressSensorPreliminaryFMI "Used to identify the applicable J1939-73 FMI detected in the engine cylinder 4 pressure sensor.  When there is no failure FMI 31 is sent. In the case of multiple failures the most severe is communicated.";
CM_ SG_ 2364554750 EngCyl4SynchronousKnockLevel "Used to indicate the level of knock for engine cylinder 4. The level of knock is reported using a relative scale where 0% is least level of knock, and increasing levels indicate more knock until 100% indicates the most severe level of knock allowed ...";
CM_ SG_ 2364554750 EngCyl4PeakPress "Peak pressure in engine cylinder 4 in combustion cycle.";
CM_ SG_ 2364554750 EngCyl4HeatRelease "The amount of heat produced during combustion in engine cylinder 4.  The negative range is to cover thermodynamic behavior during misfire.";
CM_ BO_ 2364554494 "Engine Cylinder 3 Combustion Information
Used to communicate combustion information of Engine Cylinder 3. The PGN is transmitted at the end of every combustion in Cylinder 3.";
CM_ SG_ 2364554494 MaxPressIncreaseRate "The maximum slope, in degrees of crank angle, of the pressure increase in engine cylinder 3 during the combustion cycle.";
CM_ SG_ 2364554494 LowFreqKnockLvl "Indicates the level of low frequency knock for engine cylinder 3. This knock occurs at frequencies below the typical knock level reported on SPNs 1354 & 6406.  The level of low frequency knock is reported using a relative scale where 0% is least ...";
CM_ SG_ 2364554494 EngCyl3PressSensorPreliminaryFMI "Used to identify the applicable J1939-73 FMI detected in the engine cylinder 3 pressure sensor.  When there is no failure FMI 31 is sent. In the case of multiple failures the most severe is communicated.";
CM_ SG_ 2364554494 EngCyl3SynchronousKnockLevel "Used to indicate the level of knock for engine cylinder 3. The level of knock is reported using a relative scale where 0% is least level of knock, and increasing levels indicate more knock until 100% indicates the most severe level of knock allowed ...";
CM_ SG_ 2364554494 EngCyl3PeakPress "Peak pressure in engine cylinder 3 in combustion cycle.";
CM_ SG_ 2364554494 EngCyl3HeatRelease "The amount of heat produced during combustion in engine cylinder 3.  The negative range is to cover thermodynamic behavior during misfire.";
CM_ BO_ 2364554238 "Engine Cylinder 2 Combustion Information
Used to communicate combustion information of Engine Cylinder 2. The PGN is transmitted at the end of every combustion in Cylinder 2.";
CM_ SG_ 2364554238 MaxPressIncreaseRate "The maximum slope, in degrees of crank angle, of the pressure increase in engine cylinder 2 during the combustion cycle.";
CM_ SG_ 2364554238 LowFreqKnockLvl "Indicates the level of low frequency knock for engine cylinder 2. This knock occurs at frequencies below the typical knock level reported on SPNs 1353 & 6402.  The level of low frequency knock is reported using a relative scale where 0% is least ...";
CM_ SG_ 2364554238 EngCyl2PressSensorPreliminaryFMI "Used to identify the applicable J1939-73 FMI detected in the engine cylinder 2 pressure sensor.  When there is no failure FMI 31 is sent. In the case of multiple failures the most severe is communicated.";
CM_ SG_ 2364554238 EngCyl2SynchronousKnockLevel "Used to indicate the level of knock for engine cylinder 2. The level of knock is reported using a relative scale where 0% is least level of knock, and increasing levels indicate more knock until 100% indicates the most severe level of knock allowed ...";
CM_ SG_ 2364554238 EngCyl2PeakPress "Peak pressure in engine cylinder 2 in combustion cycle.";
CM_ SG_ 2364554238 EngCyl2HeatRelease "The amount of heat produced during combustion in engine cylinder 2.  The negative range is to cover thermodynamic behavior during misfire.";
CM_ BO_ 2364553982 "Engine Cylinder 1 Combustion Information
Used to communicate combustion information of Engine Cylinder 1. The PGN is transmitted at the end of every combustion in Cylinder 1.";
CM_ SG_ 2364553982 MaxPressIncreaseRate "The maximum slope, in degrees of crank angle, of the pressure increase in engine cylinder 1 during the combustion cycle.";
CM_ SG_ 2364553982 LowFreqKnockLvl "Indicates the level of low frequency knock for engine cylinder 1. This knock occurs at frequencies below the typical knock level reported on SPNs 1352 & 6398. The level of low frequency knock is reported using a relative scale where 0% is least ...";
CM_ SG_ 2364553982 EngCyl1PressSensorPreliminaryFMI "Used to identify the applicable J1939-73 FMI detected in the engine cylinder 1 pressure sensor.  When there is no failure FMI 31 is sent. In the case of multiple failures the most severe is communicated.";
CM_ SG_ 2364553982 EngCyl1SynchronousKnockLevel "Used to indicate the level of knock for engine cylinder 1. The level of knock is reported using a relative scale where 0% is least level of knock, and increasing levels indicate more knock until 100% indicates the most severe level of knock allowed ...";
CM_ SG_ 2364553982 EngCyl1PeakPress "Peak pressure in engine cylinder 1 in combustion cycle.";
CM_ SG_ 2364553982 EngCyl1HeatRelease "The amount of heat produced during combustion in Engine cylinder 1. The negative range is to cover thermodynamic behavior during misfire.";
CM_ BO_ 2364553726 "Engine Air System Information
Used to transmit parameters related to air systems.";
CM_ SG_ 2364553726 EngTotalIntakeMassAirFlowRate "Mass Flow rate of air entering the engine. This also includes the amount of exhaust gas recirculated, if any.";
CM_ SG_ 2364553726 EngDesiredAirFuelRatio "Reports the desired Air Fuel ratio for the engine.

Air Fuel Ratio specifies the amount of air required to completely burn one unit of fuel in the engine to meet the required engine performance and emission standards.";
CM_ BO_ 2364553470 "Engine Torque / Fuel Request
Used to transmit requested information for engine torque and fuel rate.";
CM_ SG_ 2364553470 EngCylTorque "Calculated engine torque output per cylinder.";
CM_ SG_ 2364553470 EngCylDieselMassFlowRateCmd "Commanded Mass Flow rate of diesel fuel delivered to the engine normalized per cylinder.";
CM_ SG_ 2364553470 EngCylGasMassFlowRateCmd "Commanded Mass Flow rate of gaseous fuel delivered to the engine normalized per cylinder.";
CM_ SG_ 2364553470 EngGasFuelPercentageCmd "Percentage of Gaseous fuel used, in terms of % mass of fuel. 0% means no Gaseous fuel used and 100 % means completely gaseous fuel is used.
Gas substitution is the process for a dual fuel engine system of substituting gas, e.g. natural gas, for ...";
CM_ SG_ 2364553470 EngDualFuelModeCmd "Request to enable dual fuel mode.

00 = De-activate dual fuel mode
01 = Activate dual fuel mode
10 = Reserved
11 = Not available";
CM_ BO_ 2364553214 "Engine Turbocharger Blowoff Actuator 1
Used to transmit Engine Turbocharger Blowoff Actuator parameters";
CM_ SG_ 2364553214 EngTrbCmprssrBlwffActtr1OprtnStt "Used to identify the status of Engine Turbocharger Compressor Blowoff Actuator 1.
0000 - Normal
0001 - Alarm (fully operational but needs service)
0010 - Alarm High Severity (functional but transient performance may be reduced)
0011 - Derate ...";
CM_ SG_ 2364553214 EngTrbCmprssrBlowoffActuator1Pos "Actual position of the turbocharger compressor blowoff actuator, where 0% represents fully closed and 100% represents fully open.";
CM_ SG_ 2364553214 EngTrbCmprssrBlwffActtr1DsredPos "The requested position of the Engine Turbocharger Compressor Blowoff actuator by the engine ECU, where 0% represents bypass fully closed and 100% represents fully open.  This is the position that the device is attempting to achieve.";
CM_ SG_ 2364553214 EngTrbCmprssrBlwoffActuator1Temp "Temperature of the Engine Turbocharger Compressor Bypass Actuator 1 drive circuitry. Temperature excursions may affect the torque output.";
CM_ SG_ 2364553214 EngTrbCmprssrBlwffActtr1TmpSttus "Used to identify the status of the Engine Turbocharger Compresssor Blowoff Actuator 1 drive circuitry temperature. Temperature excursions may affect the torque output.
000 - High Most severe
001 - High Least severe
010 - In Range
011 - Low Least ...";
CM_ SG_ 2364553214 EngTrbCmprssrBlwffActtr1PrlmnryF "Used to identify the applicable J1939-73 FMI detected in the Engine Turbocharger Blowoff Actuator 1 by the manufacturer's software. When there is no failure FMI 31 is transmitted. When there are multiple failures, the most severe is transmitted.";
CM_ BO_ 2565874430 "Machine Selected Speed
Message that provides the current machine selected speed, direction, and source parameters.";
CM_ SG_ 2565874430 PersistentLimitStatus "Reports the tractor ECU's present limit status associated with a parameter whose commands are presistent  (i.e. hitch position).
000 - Not limited
001 - Operator limited/controlled (Request cannot be implemented)
010 - Limited high (only lower ...";
CM_ SG_ 2565874430 MachineSelectedSpeedSource "Indicates the speed source that is currently being reported in the machine speed parameter.
000 - Wheel-based speed
001 - Ground-based speed
010 - Navigation-based speed
011 - 'Blended' speed
100 - 'Simulated' speed
101 - 110 - Reserved
111 - ...";
CM_ SG_ 2565874430 MachineSelectedDirection "Indicates the current direction of travel of the machine.

00 - Reverse
01 - Forward
10 - Error indication
11 - Not available";
CM_ SG_ 2565874430 MachineSelectedDistance "Actual distance traveled by the machine based on the value of selected machine speed.  When distance exceeds 4211081.215 m, the value should be reset to zero and incremented as additional distance accrues.";
CM_ SG_ 2565874430 MachineSelectedSpeed "Reports the value of one of the currently available machine speeds (wheel, ground, or navigational-based) which the machine has determined to best represent the machine's speed.";
CM_ BO_ 2565873918 "Electronic Brake System #2/5
Message to transmit data of the towed vehicle to the towing vehicle. See ISO 11992-2.";
CM_ BO_ 2565873662 "Electronic Brake System #2/6
Message to transmit data of the towed vehicle to the towing vehicle. See ISO 11992-2.";
CM_ BO_ 2364546814 "Generator Control 2
Contains parameters that allow the generator control system to control the engine and to provide information about the generator control system";
CM_ SG_ 2364546814 GeneratorGoverningBias "Control signal used to govern the genset's speed or load (depending on isochronous or utility parallel operation, respectively)
NOTE:  If this method of engine control is used, the PGN 0 (TSC1) is not expected to be received by the engine ...";
CM_ BO_ 2565872638 "General Purpose Message #1/7
Message to transmit data of the towing vehicle to the towed vehicle. See ISO 11992-3.";
CM_ BO_ 2565865214 "Proprietary A
This proprietary PG uses the Destination Specific PDU Format allowing manufacturers to direct their proprietary communications to a specific destination node.";
CM_ BO_ 2565340926 "Node-to-Virtual Terminal";
CM_ BO_ 2565275390 "Virtual Terminal-to-Node";
CM_ BO_ 2566767614 "Electronic Engine Controller 15";
CM_ SG_ 2566767614 AccelPedal2Channel3 "Sensor output 3 for the accelerator pedal #2 position when using a redundant-style sensor.  The ratio of actual accelerator pedal position to maximum pedal position. This is for the second occurrence of the accelerator pedal. Although it is used as ...";
CM_ SG_ 2566767614 AccelPedal2Channel2 "Sensor output 2 for the accelerator pedal #2 position when using a redundant-style sensor.  The ratio of actual accelerator pedal position to maximum pedal position. This is for the second occurrence of the accelerator pedal. Although it is used as ...";
CM_ SG_ 2566767614 AccelPedal1Channel3 "Sensor output 3 for the accelerator pedal #1 position when using a redundant-style sensor.  The ratio of actual accelerator pedal position to maximum pedal position. This is for the first occurrence of the accelerator pedal. Although it is used as ...";
CM_ SG_ 2566767614 AccelPedal1Channel2 "Sensor output 2 for the accelerator pedal #1 position when using a redundant-style sensor.  The ratio of actual accelerator pedal position to maximum pedal position. This is for the first occurrence of the accelerator pedal. Although it is used as ...";
CM_ BO_ 2559049470 "Engine State Requests";
CM_ SG_ 2559049470 EngFuelingNotDesiredReason_7855 "This parameter conveys the reason a device wants the engine to inhibit fuelling.";
CM_ SG_ 2559049470 TransIdlGovrnrFuelingInhibt_7829 "This parameter is a command provided to the Engine Control Module (ECM) from the Transmission Control Module (TCM) to inhibit idle governor fueling in the unlikely event that transmission has detected a failure preventing driveline disengagement.";
CM_ SG_ 2559049470 EngineFuelingDesiredReason_7789 "This parameter conveys the reason a device wants the engine running.";
CM_ SG_ 2559049470 DesiredEngFuelingState_5793 "Devices send this request to the engine controller to:
(a) Shut off engine fueling, but remain prepared to re-start quickly by not shutting down the control system, or
(b) Keep the engine running.
00 Fueling not desired (shut off engine fueling)
 ...";
CM_ SG_ 2559049470 RequestedFuelType_6317 "Engine controller receives this request from another control module to select the type of fuel to be used for engine operation.
0x00 - Not available - NONE
0x01 - Gasoline/petrol - GAS
0x02 - Methanol - METH
0x03 - Ethanol - ETH
0x04 - Diesel - ...";
CM_ SG_ 2559049470 EngGasFuelSupplyDsrdPress_6715 "Desired gage pressure of gaseous fuel supply to the engine.";
CM_ SG_ 2559049470 EngGasFuelUsageInhibited_6833 "Used to request that the engine should not be allowed to use gaseous fuel for engine cylinder combustion. This state is relevant for dual fuel systems and would be used when conditions are detected that make it unsafe or not appropriate to use ...";
CM_ BO_ 2349596414 "Advanced Emergency Braking System 2 - Advanced Emergency Braking System message 2.";
CM_ SG_ 2349596414 AEBS2MessageChecksum_5683 "Used to check the message checksum of the transmitting (HMI) unit within the AEBS2 system.
Checksum = (Byte1 + Byte2 + Byte3 + Byte4 + Byte5 + Byte6 + Byte7 + (message counter & 0x0F) + message ID low byte + message ID mid low byte + message ID mid ...";
CM_ SG_ 2349596414 AEBS2MessageCounter_5682 "The message counter is increased with every transmitted AEBS2 message.  After reaching a value of 0xF the next value will be 0.";
CM_ SG_ 2349596414 DrvrActDmndFrAdvEmrgncyBrk_5681 "According to the Vienna world convention on road traffic the driver must be provided with means to deactivate an Advanced Emergency Braking System. This command is to be transmitted from the respective HMI unit to the AEBS unit.
00 - the driver ...";
CM_ BO_ 2563702526 "Reserved for ISO 15765
KWP2000 Mixed physical addressing";
CM_ BO_ 2563636990 "Reserved for ISO 15765
KWP2000 Mixed functional addressing";
CM_ BO_ 2563571454 "Request for Repetition Rate - This message allows the system to adapt the bus bandwidth to the needs of the user of messages.";
CM_ SG_ 2563571454 DataDictionaryRow_2427 "This 4 bit parameter indicates the Row that is to be used within the specific Data Dictionary Table identified by the Implement Type. This is the Group (GRUP) in LBS documents.";
CM_ SG_ 2563571454 DataDictionaryColumn_2428 "This 4 bit parameter indicates the Column that is to be used within the specific Data Dictionary Table identified by the Implement Type. This is the Instance (INST) in LBS documents.";
CM_ SG_ 2563571454 ImplementType_2425 "This 4 bit parameter indicates which data dictionary page is to be used to locate the identity of the following data.";
CM_ SG_ 2563571454 ImplementPos_2426 "This 4 bit parameter of this message will indicate which Implement is referenced within a set of identical Implements.  The numbering is to start with 1 at the leftmost, foremost, bottom most implement.  The numbering will then increment from left ...";
CM_ SG_ 2563571454 DataFormat_ErrorCondition_2419 "This 2 bit parameter that indicates the format or availability of the data in the following Process Data Parameter.
00 Data format is Long Integer
01 Data format is Floating
10 Data format is unsigned Long Integer
11 Not Available or error
Data ...";
CM_ SG_ 2563571454 ProcessDataType_2420 "This 2 bit parameter indicates what the data in the following Process Data Parameters is to be used for. See Table A.2.
00 Data is Set Point
01 Data is Actual values
10 Message is Set Point request
11 Message is Actual value request
Data is Set ...";
CM_ SG_ 2563571454 ProcessDataModifier_2421 "This 3 bit parameter that indicates how the data in the following Process Data Parameters is to be used when combined with the Process Data Type parameter. See Table A.2.

NOTE: Process Data Type is included since MOD is a function of PD";
CM_ SG_ 2563571454 RepetitionRateParameter_2418 "This parameter defines the repetition rate of the specified PGN.";
CM_ BO_ 2563505918 "Process Data Message - The Process Data message has been defined as a destination specific message implying that the sender must decide which implement should receive the message.Working Set).";
CM_ SG_ 2563505918 ProcessVariableValue_2429 "This 4 byte parameter contains the actual data  for the Process Data Message.";
CM_ SG_ 2563505918 DataDictionaryRow_2427 "This 4 bit parameter indicates the Row that is to be used within the specific Data Dictionary Table identified by the Implement Type. This is the Group (GRUP) in LBS documents.";
CM_ SG_ 2563505918 DataDictionaryColumn_2428 "This 4 bit parameter indicates the Column that is to be used within the specific Data Dictionary Table identified by the Implement Type. This is the Instance (INST) in LBS documents.";
CM_ SG_ 2563505918 ImplementType_2425 "This 4 bit parameter indicates which data dictionary page is to be used to locate the identity of the following data.";
CM_ SG_ 2563505918 ImplementPos_2426 "This 4 bit parameter of this message will indicate which Implement is referenced within a set of identical Implements.  The numbering is to start with 1 at the leftmost, foremost, bottom most implement.  The numbering will then increment from left ...";
CM_ SG_ 2563505918 CountNumber_2422 "This parameter indicates which member of the set of possible entities is being referenced. The means of generating this Count Number is explained in the following clause.";
CM_ SG_ 2563505918 DataFormat_ErrorCondition_2419 "This 2 bit parameter that indicates the format or availability of the data in the following Process Data Parameter.
00 Data format is Long Integer
01 Data format is Floating
10 Data format is unsigned Long Integer
11 Not Available or error
Data ...";
CM_ SG_ 2563505918 ProcessDataType_2420 "This 2 bit parameter indicates what the data in the following Process Data Parameters is to be used for. See Table A.2.
00 Data is Set Point
01 Data is Actual values
10 Message is Set Point request
11 Message is Actual value request
Data is Set ...";
CM_ SG_ 2563505918 ProcessDataModifier_2421 "This 3 bit parameter that indicates how the data in the following Process Data Parameters is to be used when combined with the Process Data Type parameter. See Table A.2.

NOTE: Process Data Type is included since MOD is a function of PD";
CM_ BO_ 2563309310 "Extended Transport Protocol - Connection Management
Defined in ISO 11783-6  Annex L";
CM_ BO_ 2563243774 "Extended Transport Protocol - Data Transfer
Defined in ISO 11783-6  Annex L";
CM_ BO_ 2563178238 "General Purpose Valve Estimated Flow - This message provides the estimated flow of a general purpose valve.  Defined in ISO 11783-7.";
CM_ SG_ 2563178238 ValveFailSafeMode_2934 "Command for setting the fail safe mode of a general purpose valve.

00 Block
01 Float
10 Reserved
11 Don’t Care";
CM_ SG_ 2563178238 ValveState_2932 "The measured state of the general purpose valve.   With float enabled, hydraulic fluid may flow to or from the tractor as driven by the implement.
0000            Blocked
0001            Extend
0010            Retract
0011            Floating
 ...";
CM_ SG_ 2563178238 RetractPortEstFlow_2940 "The value reported by the controller of flow through the extend port of an auxiliary valve of a tractor";
CM_ SG_ 2563178238 ExtendPortEstFlow_2939 "The value reported by the controller of flow through the extend port of an auxiliary valve of a tractor";
CM_ BO_ 2563112702 "General Purpose Valve Measured Flow - This message provides the measurement of a general purpose valve.  Defined in ISO11783-7.";
CM_ SG_ 2563112702 ReturnPortPress_2943 "The measured nominal pressure at the return port of an auxiliary valve of a tractor";
CM_ SG_ 2563112702 RetractPortPress_2942 "The measured nominal pressure at the retract port of an auxiliary valve of a tractor";
CM_ SG_ 2563112702 ExtendPortPress_2941 "The measured nominal pressure at the extend port of an auxiliary valve of a tractor";
CM_ SG_ 2563112702 RetractPortMeasuredFlow_2938 "The measured flow through the retract port of an auxiliary valve of a tractor";
CM_ SG_ 2563112702 ExtendPortMeasuredFlow_2937 "The measured flow through the extend port of an auxiliary valve of a tractor";
CM_ BO_ 2563047166 "General Purpose Valve Command - This message provides control of the flow through a general purpose valve.  Defined in ISO 11783-7.";
CM_ SG_ 2563047166 PortFlowCmd_2944 "The command to set the flow through the extend or retract port of an auxiliary valve of a tractor";
CM_ BO_ 2562785022 "Proprietarily Configurable Message #16
Proprietarily Configuration message for use in J1939-74.";
CM_ BO_ 2562719486 "Proprietarily Configurable Message #15
Proprietarily Configuration message for use in J1939-74.";
CM_ BO_ 2562653950 "Proprietarily Configurable Message #14
Proprietarily Configuration message for use in J1939-74.";
CM_ BO_ 2562588414 "Proprietarily Configurable Message #13
Proprietarily Configuration message for use in J1939-74.";
CM_ BO_ 2562522878 "Proprietarily Configurable Message #12
Proprietarily Configuration message for use in J1939-74.";
CM_ BO_ 2562457342 "Proprietarily Configurable Message #11
Proprietarily Configuration message for use in J1939-74.";
CM_ BO_ 2562391806 "Proprietarily Configurable Message #10
Proprietarily Configuration message for use in J1939-74.";
CM_ BO_ 2562326270 "Proprietarily Configurable Message #9
Proprietarily Configuration message for use in J1939-74.";
CM_ BO_ 2562260734 "Proprietarily Configurable Message #8
Proprietarily Configuration message for use in J1939-74.";
CM_ BO_ 2562195198 "Proprietarily Configurable Message #7
Proprietarily Configuration message for use in J1939-74.";
CM_ BO_ 2562129662 "Proprietarily Configurable Message #6
Proprietarily Configuration message for use in J1939-74.";
CM_ BO_ 2562064126 "Proprietarily Configurable Message #5
Proprietarily Configuration message for use in J1939-74.";
CM_ BO_ 2561998590 "Proprietarily Configurable Message #4
Proprietarily Configuration message for use in J1939-74.";
CM_ BO_ 2561933054 "Proprietarily Configurable Message #3
Proprietarily Configuration message for use in J1939-74.";
CM_ BO_ 2561867518 "Proprietarily Configurable Message #2
Proprietarily Configuration message for use in J1939-74.";
CM_ BO_ 2561801982 "Proprietarily Configurable Message #1
Proprietarily Configuration message for use in J1939-74.";
CM_ BO_ 2561736446 "Configuration Identification Message
Message used to identify the data content (by SPN) of one of the configurable messages
(identified by PGN).";
CM_ BO_ 2561670910 "Parameter Locate Message
This message is designed to cause other CAs to respond with the identity of any message that they send in which the particular parameter (identified by specific SPN) is contained";
CM_ BO_ 2561539838 "Agricultural Guidance System Command
Steering command expressed as desired curvature";
CM_ BO_ 2561474302 "Agricultural Guidance Machine Info
Machine system feedback detailing status of machine relative to guidance operation";
CM_ BO_ 2561408766 "File Server to Client (ECU) message
Used for obtaining status of the client, volume handling, file access, file handling and directory handling.  Description of messages is given in ISO 11783 Part 13.";
CM_ BO_ 2560294654 "General Purpose Message #1/8
Message to transmit data of the towing vehicle to the towed vehicle. See ISO 11992-3.";
CM_ BO_ 2358509310 "A message to change fields of the NAME of a CA";
CM_ BO_ 2559508222 "Sequence Control Master-to-Sequence Control Client
The PGN is for a sequence control system, such as a headland management system, which includes tractor and implement functions in one system.";
CM_ BO_ 2559442686 "Sequence Control Client-to-Sequence Control Master
This PGN is for sending response messages from control functions to a Sequence Control Master on the tractor and connected implement(s).";
CM_ BO_ 2559377150 "CCP Command Receive Object
The CRO message is the one of two PGNs needed by the CAN Calibration Protocol. It is sent by a tool to send queries or commands to a target ECU.";
CM_ BO_ 2559311614 "CCP Data Transmission Object
The DTO message is the one of two PGNs needed by the CAN Calibration Protocol. It is sent by an ECU in response tool to tool queries or commands.";
CM_ BO_ 2558983934 "Switched Power Outputs Command - The switched power outputs command is sent to the Power Distribution Module (PDM) to change the state of the PDM's switched power outputs.
This command is sent to the PDM as needed to change the power outputs, but no ...";
CM_ SG_ 2558983934 SwitchedPowerOutput18Cmd_6002 "Desired state of Switched Power Output #18. Used to set the desired state.

00 - Output off
01 - Output on
10 - Reserved
11 - Take no action";
CM_ SG_ 2558983934 SwitchedPowerOutput19Cmd_6001 "Desired state of Switched Power Output #19. Used to set the desired state.

00 - Output off
01 - Output on
10 - Reserved
11 - Take no action";
CM_ SG_ 2558983934 SwitchedPowerOutput20Cmd_6000 "Desired state of Switched Power Output #20. Used to set the desired state.

00 - Output off
01 - Output on
10 - Reserved
11 - Take no action";
CM_ SG_ 2558983934 SwitchedPowerOutput13Cmd_5999 "Desired state of Switched Power Output #13. Used to set the desired state.

00 - Output off
01 - Output on
10 - Reserved
11 - Take no action";
CM_ SG_ 2558983934 SwitchedPowerOutput14Cmd_5998 "Desired state of Switched Power Output #14. Used to set the desired state.

00 - Output off
01 - Output on
10 - Reserved
11 - Take no action";
CM_ SG_ 2558983934 SwitchedPowerOutput15Cmd_5997 "Desired state of Switched Power Output #15. Used to set the desired state.

00 - Output off
01 - Output on
10 - Reserved
11 - Take no action";
CM_ SG_ 2558983934 SwitchedPowerOutput16Cmd_5996 "Desired state of Switched Power Output #16. Used to set the desired state.

00 - Output off
01 - Output on
10 - Reserved
11 - Take no action";
CM_ SG_ 2558983934 SwitchedPowerOutput9Cmd_5995 "Desired state of Switched Power Output #9. Used to set the desired state.

00 - Output off
01 - Output on
10 - Reserved
11 - Take no action";
CM_ SG_ 2558983934 SwitchedPowerOutput10Cmd_5994 "Desired state of Switched Power Output #10. Used to set the desired state.

00 - Output off
01 - Output on
10 - Reserved
11 - Take no action";
CM_ SG_ 2558983934 SwitchedPowerOutput29Cmd_6015 "Desired state of Switched Power Output #29. Used to set the desired state.

00 - Output off
01 - Output on
10 - Reserved
11 - Take no action";
CM_ SG_ 2558983934 SwitchedPowerOutput30Cmd_6014 "Desired state of Switched Power Output #30. Used to set the desired state.

00 - Output off
01 - Output on
10 - Reserved
11 - Take no action";
CM_ SG_ 2558983934 SwitchedPowerOutput31Cmd_6013 "Desired state of Switched Power Output #31. Used to set the desired state.

00 - Output off
01 - Output on
10 - Reserved
11 - Take no action";
CM_ SG_ 2558983934 SwitchedPowerOutput32Cmd_6012 "Desired state of Switched Power Output #32. Used to set the desired state.

00 - Output off
01 - Output on
10 - Reserved
11 - Take no action";
CM_ SG_ 2558983934 SwitchedPowerOutput25Cmd_6011 "Desired state of Switched Power Output #25. Used to set the desired state.

00 - Output off
01 - Output on
10 - Reserved
11 - Take no action";
CM_ SG_ 2558983934 SwitchedPowerOutput26Cmd_6010 "Desired state of Switched Power Output #26. Used to set the desired state.

00 - Output off
01 - Output on
10 - Reserved
11 - Take no action";
CM_ SG_ 2558983934 SwitchedPowerOutput27Cmd_6009 "Desired state of Switched Power Output #27. Used to set the desired state.

00 - Output off
01 - Output on
10 - Reserved
11 - Take no action";
CM_ SG_ 2558983934 SwitchedPowerOutput28Cmd_6008 "Desired state of Switched Power Output #28. Used to set the desired state.

00 - Output off
01 - Output on
10 - Reserved
11 - Take no action";
CM_ SG_ 2558983934 SwitchedPowerOutput21Cmd_6007 "Desired state of Switched Power Output #21. Used to set the desired state.

00 - Output off
01 - Output on
10 - Reserved
11 - Take no action";
CM_ SG_ 2558983934 SwitchedPowerOutput22Cmd_6006 "Desired state of Switched Power Output #22. Used to set the desired state.

00 - Output off
01 - Output on
10 - Reserved
11 - Take no action";
CM_ SG_ 2558983934 SwitchedPowerOutput23Cmd_6005 "Desired state of Switched Power Output #23. Used to set the desired state.

00 - Output off
01 - Output on
10 - Reserved
11 - Take no action";
CM_ SG_ 2558983934 SwitchedPowerOutput24Cmd_6004 "Desired state of Switched Power Output #24. Used to set the desired state.

00 - Output off
01 - Output on
10 - Reserved
11 - Take no action";
CM_ SG_ 2558983934 SwitchedPowerOutput17Cmd_6003 "Desired state of Switched Power Output #17. Used to set the desired state.

00 - Output off
01 - Output on
10 - Reserved
11 - Take no action";
CM_ SG_ 2558983934 SwitchedPowerOutput11Cmd_5993 "Desired state of Switched Power Output #11. Used to set the desired state.

00 - Output off
01 - Output on
10 - Reserved
11 - Take no action";
CM_ SG_ 2558983934 SwitchedPowerOutput12Cmd_5992 "Desired state of Switched Power Output #12. Used to set the desired state.

00 - Output off
01 - Output on
10 - Reserved
11 - Take no action";
CM_ SG_ 2558983934 SwitchedPowerOutput5Cmd_5991 "Desired state of Switched Power Output #5. Used to set the desired state.

00 - Output off
01 - Output on
10 - Reserved
11 - Take no action";
CM_ SG_ 2558983934 SwitchedPowerOutput6Cmd_5990 "Desired state of Switched Power Output #6. Used to set the desired state.

00 - Output off
01 - Output on
10 - Reserved
11 - Take no action";
CM_ SG_ 2558983934 SwitchedPowerOutput7Cmd_5989 "Desired state of Switched Power Output #7. Used to set the desired state.

00 - Output off
01 - Output on
10 - Reserved
11 - Take no action";
CM_ SG_ 2558983934 SwitchedPowerOutput8Cmd_5988 "Desired state of Switched Power Output #8. Used to set the desired state.

00 - Output off
01 - Output on
10 - Reserved
11 - Take no action";
CM_ SG_ 2558983934 SwitchedPowerOutput1Cmd_5987 "Desired state of Switched Power Output #1. Used to set the desired state.

00 - Output off
01 - Output on
10 - Reserved
11 - Take no action";
CM_ SG_ 2558983934 SwitchedPowerOutput2Cmd_5986 "Desired state of Switched Power Output #2. Used to set the desired state.

00 - Output off
01 - Output on
10 - Reserved
11 - Take no action";
CM_ SG_ 2558983934 SwitchedPowerOutput3Cmd_5985 "Desired state of Switched Power Output #3. Used to set the desired state.

00 - Output off
01 - Output on
10 - Reserved
11 - Take no action";
CM_ SG_ 2558983934 SwitchedPowerOutput4Cmd_5984 "Desired state of Switched Power Output #4. Used to set the desired state.

00 - Output off
01 - Output on
10 - Reserved
11 - Take no action";
CM_ BO_ 2349727486 "Transmission Control 2 - Used to communicate transmission control information";
CM_ SG_ 2349727486 TransMode10_6570 "Indicates whether transmission mode 10 is enabled. Modes are manufacturer specific and are not necessarily mutually exclusive. See also SPN 6568. 

00 Disable
01 Enable
10 Reserved
11 Take no action";
CM_ SG_ 2349727486 TransMode9_6569 "Indicates whether transmission mode 9 is enabled. Modes are manufacturer specific and are not necessarily mutually exclusive. See also SPN 6567. 

00 Disable
01 Enable
10 Reserved
11 Take no action";
CM_ BO_ 2550988542 "Electronic Engine Controller 16";
CM_ SG_ 2550988542 AccelPedalPos3_28 "The ratio of actual position of the third analog engine speed/torque request input device (such as an accelerator pedal or throttle lever) to the maximum position of the input device.  This parameter is intended for the third accelerator control in ...";
CM_ BO_ 2550595326 "CANopen Application Message #2/1
Message to transmit data of the towed vehicle to the towing vehicle. See ISO 11992-3.";
CM_ BO_ 2550529790 "CANopen Application Message #1/1
Message to transmit data of the towing vehicle to the towed vehicle. See ISO 11992-3.";
CM_ BO_ 2566767358 "Electronic Engine Controller 14";
CM_ SG_ 2566767358 EngFuelIsolationCtrl "Control setting for fuel isolation. In a single injector dual fuel system when using just diesel fuel, diesel must not be allowed to migrate into the gaseous fuel system. When the fuel isolation valve is closed the engine uses dual fuel by allowing ...";
CM_ SG_ 2566767358 FuelType "Type of fuel currently being utilized by the vehicle
Data Byte - Scaling - External Display
0x00 - Not available - NONE
0x01 - Gasoline/petrol - GAS
0x02 - Methanol - METH
0x03 - Ethanol - ETH
0x04 - Diesel - DSL
0x05 - Liquefied Petroleum ...";
CM_ SG_ 2566767358 EngFuelMassFlowRate "Mass of liquid fuel consumed by engine per unit of time.";
CM_ SG_ 2566767358 EngExhstGsRcrcltn1Valve2PosError "The position error of the Exhaust Gas Recirculation 1 valve 2, determined as the actual position (SPN 3821) minus the commanded position (SPN 3822).";
CM_ SG_ 2566767358 EngExhstGsRcrcltn1Valve1PosError "The position error of the Exhaust Gas Recirculation 1 valve, determined as the actual position (SPN 27) minus the commanded position (SPN 2791).";
CM_ BO_ 2566706686 "Aftertreatment 1 Diesel Exhaust Fluid Pump 1 Information
Contains information on Diesel Exhaust Fluid Pumps";
CM_ SG_ 2566706686 TwoMotorSpd "Rotational speed of the motor driving the second pump for the diesel exhaust fluid used in aftertreatment system 1 (exhaust bank 1).";
CM_ SG_ 2566706686 Htr "Percentage of heating applied to the aftertreatment 1 diesel exhaust fluid pump heater. A value of 0% means no heating applied, a value of 100% means full heating applied. The diesel exhaust fluid pump heater warms the diesel exhaust fluid in the ...";
CM_ BO_ 2566705406 "Engine Particulate Sensor Information";
CM_ SG_ 2566705406 AFT1ParticulateSnsrCur "Raw aftertreatment 1 PM sensor electical current reading.";
CM_ SG_ 2566705406 AFT2ParticulateSnsr "The particulate sensor measures the mass concentration of particulate matter in the exhaust downstream of the DPF in exhaust bank 2.";
CM_ SG_ 2566705406 AFT1ParticulateSnsr "The particulate sensor measures the mass concentration of particulate matter in the exhaust downstream of the DPF in exhaust bank 1.";
CM_ BO_ 2566705150 "NOx Sensor Self-Diagnosis Request
Request to initiate the self-diagnosis of the NOx sensors implemented in the system.
This request may be sent at any time, but should not be sent if the status parameter indicates the self-diagnosis is not ...";
CM_ SG_ 2566705150 AFT2InNOxSnsrSelfDiagTrigger "Signal to trigger the self-diagnosis of NOx sensor ATI2 (Aftertreatment Intake Bank 2)
0000 Diagnostic mode disabled
0001 NOx Sensor ATI2 Self Diagnosis Request at Lambda=1.0
0010 NOx Sensor ATI2 Self Diagnosis Request at partial load
0011 NOx ...";
CM_ SG_ 2566705150 AFT2OutNOxSnsrSelfDiagTrigger "Signal to trigger the self-diagnosis of NOx sensor ATO2 (Aftertreatment Outlet Bank 2)
0000 Diagnostic mode disabled
0001 NOx Sensor ATO2 Self Diagnosis Request at Lambda=1.0
0010 NOx Sensor ATO2 Self Diagnosis Request at partial load
0011 NOx ...";
CM_ SG_ 2566705150 AFT1InNOxSnsrSelfDiagTrigger "Signal to trigger the self-diagnosis of NOx sensor ATI1 (Aftertreatment Intake Bank 1)
0000 Diagnostic mode disabled
0001 NOx Sensor ATI1 Self Diagnosis Request at Lambda=1.0
0010 NOx Sensor ATI1 Self Diagnosis Request at partial load
0011 NOx ...";
CM_ SG_ 2566705150 AFT1OutNOxSnsrSelfDiagTrigger "Signal to trigger the self-diagnosis of NOx sensor ATO1 (Aftertreatment Outlet Bank 1)
0000 Diagnostic mode disabled
0001 NOx Sensor ATO1 Self Diagnosis Request at Lambda=1.0
0010 NOx Sensor ATO1 Self Diagnosis Request at partial load
0011 NOx ...";
CM_ BO_ 2566704382 "Electronic Engine Controller 12
Engine Related Parameters";
CM_ SG_ 2566704382 AFT2OutGasSnsrPwrSupply "State signal which indicates when the Aftertreatment 2 Outlet Gas Sensor driver output is being driven.  On means the ECU is powering the Aftertreatment 2 Intake Gas Sensor.  Note that the ECU is external to the sensor.
00 - Off
01 - On: The ECU ...";
CM_ SG_ 2566704382 AFT2InGasSnsrPwrSupply "State signal which indicates when the Aftertreatment 2 Intake Gas Sensor driver output is being driven.  On means the ECU is powering the Aftertreatment 2 Intake Gas Sensor.  Note that the ECU is external to the sensor.
00 - Off
01 - On: The ECU ...";
CM_ SG_ 2566704382 AFT1OutGasSnsrPwrSupply "State signal which indicates when the Aftertreatment 1 Outlet Gas Sensor driver output is being driven.  On means the ECU is powering the Aftertreatment 1 Intake Gas Sensor.  Note that the ECU is external to the sensor.
00 - Off
01 - On: The ECU ...";
CM_ SG_ 2566704382 AFT1InGasSnsrPwrSupply "State signal which indicates when the Aftertreatment 1 Intake Gas Sensor driver output is being driven.  On means the ECU is powering the Aftertreatment 1 Intake Gas Sensor.  Note that the ECU is external to the sensor.
00 - Off
01 - On: The ECU ...";
CM_ BO_ 2566704126 "Engine Exhaust Gas Recirculation 1 Actuator
Engine Exhaust Gas Recirculation 1 Actuator related parameters";
CM_ SG_ 2566704126 EngExhstGsRcrcltn1Acttr2PrlmnryF "Used to identify the applicable J1939-73 FMI detected in the Engine Exhaust Gas Recirculation 1 Actuator 2 by the manufacturer’s software. When there is no failure FMI 31 is transmitted. When there are multiple failures, the most severe is ...";
CM_ SG_ 2566704126 EngExhstGsRcrcltn1Acttr2OprtnStt "Used to identify the status of Exhaust Gas Recirculation 1 Actuator 2
0000 - Normal
0001 - Alarm (fully operational but needs service)
0010 - Alarm High Severity (functional but transient performance may be reduced)
0011 - Derate Active (torque ...";
CM_ SG_ 2566704126 EngExhstGsRcrcltn1Acttr1OprtnStt "Used to identify the status of Exhaust Gas Recirculation 1 Actuator 1
0000 - Normal
0001 - Alarm (fully operational but needs service)
0010 - Alarm High Severity (functional but transient performance may be reduced)
0011 - Derate Active (torque ...";
CM_ SG_ 2566704126 EngExhstGsRcrcltn1Acttr2DsredPos "The requested position of the Engine Exhaust Gas Recirculation 1 Actuator 2 by the engine ECU, where 0% represents fully closed and 100% represents fully open.

This is the position that the device is attempting to achieve.";
CM_ SG_ 2566704126 EngExhstGsRcrclton1Actuator2Temp "Temperature of the Engine Exhaust Gas Recirculation 1 Actuator 2 drive circuitry.  Temperature excursions may affect the torque output.";
CM_ SG_ 2566704126 EngExhstGsRcrcltn1Acttr2TmpSttus "Used to identify the status of the Engine Exhaust Gas Recirculation 1 Actuator 2 drive circuitry temperature.  Temperature excursions may affect the torque output.
000 - High Most severe
001 - High Least severe
010 - In Range
011 - Low Least ...";
CM_ SG_ 2566704126 EngExhstGsRcrcltn1Acttr1DsredPos "The requested position of the Engine Exhaust Gas Recirculation 1 Actuator 1 by the engine ECU, where 0% represents fully closed and 100% represents fully open.

This is the position that the device is attempting to achieve.";
CM_ SG_ 2566704126 EngExhstGsRcrclton1Actuator1Temp "Temperature of the Engine Exhaust Gas Recirculation 1 Actuator 1 drive circuitry.  Temperature excursions may affect the torque output.";
CM_ SG_ 2566704126 EngExhstGsRcrcltn1Acttr1TmpSttus "Used to identify the status of the Engine Exhaust Gas Recirculation 1 Actuator 1 drive circuitry temperature.  Temperature excursions may affect the torque output.
000 - High Most severe
001 - High Least severe
010 - In Range
011 - Low Least ...";
CM_ SG_ 2566704126 EngExhstGsRcrcltn1Acttr1PrlmnryF "Used to identify the applicable J1939-73 FMI detected in the Engine Exhaust Gas Recirculation 1 Actuator 1 by the manufacturer’s software. When there is no failure FMI 31 is transmitted. When there are multiple failures, the most severe is ...";
CM_ BO_ 2566703870 "Engine Exhaust Gas Recirculation 2 Actuator
Engine Exhaust Gas Recirculation 2 Actuator related parameters";
CM_ SG_ 2566703870 EngExhstGsRcrcltn2Acttr2OprtnStt "Used to identify the status of Exhaust Gas Recirculation 2 Actuator 2
0000 - Normal
0001 - Alarm (fully operational but needs service)
0010 - Alarm High Severity (functional but transient performance may be reduced)
0011 - Derate Active (torque ...";
CM_ SG_ 2566703870 EngExhstGsRcrcltn2Acttr1OprtnStt "Used to identify the status of Exhaust Gas Recirculation 2 Actuator 1
0000 - Normal
0001 - Alarm (fully operational but needs service)
0010 - Alarm High Severity (functional but transient performance may be reduced)
0011 - Derate Active (torque ...";
CM_ SG_ 2566703870 EngExhstGsRcrcltn2Acttr2DsredPos "The requested position of the Engine Exhaust Gas Recirculation 2 Actuator 2 by the engine ECU, where 0% represents fully closed and 100% represents fully open.

This is the position that the device is attempting to achieve.";
CM_ SG_ 2566703870 EngExhstGsRcrclton2Actuator2Temp "Temperature of the Engine Exhaust Gas Recirculation 2 Actuator 2 drive circuitry.  Temperature excursions may affect the torque output.";
CM_ SG_ 2566703870 EngExhstGsRcrcltn2Acttr2TmpSttus "Used to identify the status of the Engine Exhaust Gas Recirculation 2 Actuator 2 drive circuitry temperature.  Temperature excursions may affect the torque output.
000 - High Most severe
001 - High Least severe
010 - In Range
011 - Low Least ...";
CM_ SG_ 2566703870 EngExhstGsRcrcltn2Acttr2PrlmnryF "Used to identify the applicable J1939-73 FMI detected in the Engine Exhaust Gas Recirculation 2 Actuator 2 by the manufacturer’s software. When there is no failure FMI 31 is transmitted. When there are multiple failures, the most severe is ...";
CM_ SG_ 2566703870 EngExhstGsRcrcltn2Acttr1DsredPos "The requested position of the Engine Exhaust Gas Recirculation 2 Actuator 1 by the engine ECU, where 0% represents fully closed and 100% represents fully open.

This is the position that the device is attempting to achieve.";
CM_ SG_ 2566703870 EngExhstGsRcrclton2Actuator1Temp "Temperature of the Engine Exhaust Gas Recirculation 2 Actuator 1 drive circuitry.  Temperature excursions may affect the torque output.";
CM_ SG_ 2566703870 EngExhstGsRcrcltn2Acttr1TmpSttus "Used to identify the status of the Engine Exhaust Gas Recirculation 2 Actuator 1 drive circuitry temperature.  Temperature excursions may affect the torque output.
000 - High Most severe
001 - High Least severe
010 - In Range
011 - Low Least ...";
CM_ SG_ 2566703870 EngExhstGsRcrcltn2Acttr1PrlmnryF "Used to identify the applicable J1939-73 FMI detected in the Engine Exhaust Gas Recirculation 2 Actuator 1 by the manufacturer’s software. When there is no failure FMI 31 is transmitted. When there are multiple failures, the most severe is ...";
CM_ BO_ 2566703614 "Engine Fuel/Throttle Valve Information 2
This PGN will be used to transmit the Feedback information from the Engine Throttle and Fuel Actuator.";
CM_ SG_ 2566703614 EngFuelRackFuelSupplyTemp "Temperature of fuel in the engine fuel rack.";
CM_ SG_ 2566703614 EngTurboWastegateActuator2Temp "Temperature of the Engine Turbocharger Wastegate Actuator 2 drive circuitry.  Temperature excursions may affect the torque output.";
CM_ SG_ 2566703614 EngFuelValve2Temp "Temperature of the Engine Fuel Valve 2 drive circuitry. Temperature excursions may affect the torque output.";
CM_ SG_ 2566703614 EngFuelValve1Temp "Temperature of the Engine Fuel Valve 1 drive circuitry. Temperature excursions may affect the torque output.";
CM_ SG_ 2566703614 EngThrottleValve2Temp "Temperature of the engine throttle valve 2 drive circuitry (SPN 3673).  Temperature excursions may affect the torque output.";
CM_ SG_ 2566703614 EngThrottleValve1Temp "Temperature of the engine throttle valve 1 drive circuitry (SPN 51).  Temperature excursions may affect the torque output.";
CM_ BO_ 2566703358 "Electronic Engine Controller 13";
CM_ SG_ 2566703358 EngFuelingDesiredRqCount "A signal issued by the engine control system indicating the number of devices from which the engine control system has received a “fueling desired” request. Requests included in this count are either from an external device via SPN 5793 Desired ...";
CM_ SG_ 2566703358 EngFuelingInhibitRqCount "A signal issued by the engine control system indicating the number of devices from which the engine control system has received a “fueling not desired” request. Requests included in this count are either from an external device via SPN 5793 Desired ...";
CM_ SG_ 2566703358 EngGasSubstitutionFuelPercentage "Percentage of Gaseous fuel used. 0% means no Gaseous fuel used and 100% means completely gaseous fuel is used.
Gas substitution is the process for a dual fuel engine system of substituting gas, e.g. natural gas, for some fraction of the primary ...";
CM_ SG_ 2566703358 EngDualFuelMode "Actual dual fuel mode, off or on.

00 = Actual dual fuel mode off
01 = Actual dual fuel mode on
10 = Reserved
11 = Not available";
CM_ SG_ 2566703358 SrcAddrssOfCntrllngDvcFrFlngStte "The J1939 source address of the device currently controlling the fueling state via SPN 5793.
254 (0xFE) is used to indicate that the Source Address of Controlling Device for Fueling State parameter is supported, but no device is currently ...";
CM_ SG_ 2566703358 EngFuelingInhibitPreventedReason "If Engine Fueling Inhibit Allowed (SPN 5795) indicates that the engine will not inhibit fueling, then this parameter will indicate the reason.
If more than one reason exists at the same time, then it is up to the manufacturer to decide which one to ...";
CM_ SG_ 2566703358 EngFuelingInhibitAllowed "This parameter is broadcast by the engine control system, and indicates to other devices on the network whether or not it will respond to requests to inhibit engine fueling via SPN 5793 Desired Engine Fueling State. With this information, devices ...";
CM_ SG_ 2566703358 FeedbackEngFuelingState "This parameter provides feedback to the network that SPN 5793 Desired Engine Fueling State was honored. SPN 5795 Engine Fueling Inhibit Allowed indicates the engine’s current ability to honor requests via SPN 5793 Desired Engine Fueling State.
00 = ...";
CM_ BO_ 2566702590 "Aftertreatment 1 SCR Exhaust Gas Temperature 2
This message contains SCR catalyst gas temperature information for aftertreatment system 1 (or bank 1).";
CM_ SG_ 2566702590 IntmdTempPreliminaryFMI "Used to identify the applicable J1939-73 FMI detected in the aftertreatment SCR intermediate temperature sensor by the manufacturer’s sensor control software in exhaust bank 1. When there is no failure FMI 31 is sent. In the case of multiple ...";
CM_ SG_ 2566702590 IntmdTemp "Temperature of engine combustion byproducts at an intermediate point in the SCR component in exhaust bank 1.";
CM_ BO_ 2566702334 "Aftertreatment 2 SCR Exhaust Gas Temperature 2
This message contains SCR catalyst gas temperature information for aftertreatment system 2 (or bank 2).";
CM_ SG_ 2566702334 IntmdTempPreliminaryFMI "Used to identify the applicable J1939-73 FMI detected in the aftertreatment SCR intermediate temperature sensor by the manufacturer’s sensor control software in exhaust bank 2. When there is no failure FMI 31 is sent. In the case of multiple ...";
CM_ SG_ 2566702334 IntmdTemp "Temperature of engine combustion byproducts at an intermediate point in the SCR component in exhaust bank 2.";
CM_ BO_ 2566702078 "Fuel Information 4 (Gaseous)
Gaseous fuel information 4";
CM_ SG_ 2566702078 SupplyGasMethanePercentage "The percentage of methane in the gas supplied to the engine.";
CM_ BO_ 2566701822 "Hybrid System Status
Status information of a hybrid system.";
CM_ SG_ 2566701822 EngAssistStatus "Provides the engine an indication of when the hybrid system is not mechanically assisting rotation (i.e. not motoring) the engine. When this parameter is in state 00, the engine can perform operations while free of potential hybrid system ...";
CM_ SG_ 2566701822 HybrdSystmHghVltgExpsreIndicator "This signal indicates the condition and state of the hybrid system high voltage exposure detection system (e.g. High
Voltage Interlock Loop [HVIL]). The high voltage exposure detection system is used to detect situations on a hybrid
vehicle where ...";
CM_ SG_ 2566701822 HybrdSystmIntializationIndicator "Signal from the hybrid system that indicates when it is initialized and ready to start the engine or other power source (e.g. fuel cell). The intent is that this would drive an indicator for the vehicle operator. If the operator attempts to start ...";
CM_ SG_ 2566701822 HybrdSystmRgnrtvBrakingIndicator "Signal from the hybrid system indicating when regenerative braking is active.

00 - Regenerative braking is inactive
01 - Regenerative braking is active
10 - Regenerative braking is disabled or faulted 
11 - Not Available";
CM_ SG_ 2566701822 HybridSystemElectricAltIndicator "Signal from the hybrid system indicating that the electric alternator is failed or needs servicing.  The alternator Indicator (e.g. dash lamp) is to be activated.
00 - Alternator Indicator is off
01 - Alternator Indicator is on
10 - Alternator ...";
CM_ SG_ 2566701822 HybrdSystmMtrOvrspedAudibleAlarm "Signal from the hybrid system indicating that the overspeed audible alarm should be activated.

00 - Motor Overspeed Audible Alarm is off
01 - Motor Overspeed Audible Alarm is on
10 - Error
11 - Not Available";
CM_ SG_ 2566701822 HybrdSystmMtorOverspeedIndicator "Signal from the hybrid system indicating that the hybrid system motor is exceeding maximum speed limit.
00 - Hybrid System Motor Overspeed Indicator is off
01 - Hybrid System Motor Overspeed Indicator is on continously
10 - Hybrid System Motor ...";
CM_ SG_ 2566701822 HybridSystemServiceIndicator "Signal from the hybrid system indicating that the hybrid system or one of its components requires servicing (e.g. oil change, coolant change).
00 - Hybrid Service Indicator is off
01 - Hybrid Service Indicator is on continously
10 - Hybrid ...";
CM_ SG_ 2566701822 PropulsionSystemActive "Indicates when the hybrid system is ready to provide or is actively providing propulsion as defined in ARB regulation 13CCR1971.1, which includes the amendments up to the Board hearing date of August 2012. This parameter is called out by the 1971.1 ...";
CM_ SG_ 2566701822 HybridSystemOBDRelatedDTCStatus "Signal from hybrid system indicating the status of OBD related DTCs
00 - Hybrid System does not have an active OBD related DTC
01 - Hybrid System has an active OBD related DTC
10 - SAE Reserved
11 - Not available
See \"SPN 6810\" in the ...";
CM_ SG_ 2566701822 HybridSystemStopIndicator "Signal from a hybrid system indicating that some aspect of its operation is not functioning correctly, and as a result, the vehicle must be stopped. The indicator is typically a lamp. Distinctions in meaning between the continuous and flashing ...";
CM_ SG_ 2566701822 HybridSystemOverheatIndicator "Signal from a hybrid system indicating that at least one of its monitored temperatures is above normal acceptable limits, and as a result, hybrid system operation may be altered or restricted. The indicator is typically a lamp. Distinctions in ...";
CM_ SG_ 2566701822 HybridSystemWarningIndicator "Signal from a hybrid system indicating that some aspect of its operation is not functioning correctly, and as a result, hybrid system operation may be altered or restricted. The indicator is typically a lamp. Distinctions in meaning between the ...";
CM_ BO_ 2431661310 "Aftertreatment 2 SCR Ammonia Information 2
This message contains aftertreatment intermediate ammonia information for aftertreatment system 2 (or bank 2).";
CM_ SG_ 2431661310 IntmdNH3SnsrHtrCtrl "Indicates the heater status in the warm-up process. Upon receiving a power-up command, the NH3 sensor ramps up according to a manufacturer defined profile. The Preheat 1, Preheat 2, and Automatic messages are regions within this profile in exhaust ...";
CM_ SG_ 2431661310 IntmdNH3SnsrHtrPreliminaryFMI "Used to identify the applicable J1939-73 FMI detected in the heater of the SCR intermediate NH3 exhaust sensor by the manufacturer’s sensor control software in exhaust bank 2. When there is no failure FMI 31 is sent. In the case of multiple failures ...";
CM_ SG_ 2431661310 IntmdNH3SnsrAtTemp "Indicates that the heater element of the aftertreatment SCR intermediate NH3 sensor is within the manufacturer’s specified range for accurate measurements in exhaust bank 2.
00 - Heater element is not in range
01 - Heater element is in range
10 - ...";
CM_ SG_ 2431661310 IntmdNH3SnsrPwrInRange "Indicates that the power supplied to the aftertreatment SCR intermediate NH3 sensor is within the manufacturer’s specification in exhaust bank 2.

00 - Heater element is not in range
01 - Heater element is in range
10 - Error
11 - Not available";
CM_ SG_ 2431661310 IntmdNH3ReadingStable "Indicates that the NH3 reading of the aftertreatment SCR intermediate NH3 sensor is stable as determined by the manufacturer’s control software in exhaust bank 2.

00 - Reading is not stable
01 - Reading is stable
10 - Error
11 - Not available";
CM_ SG_ 2431661310 IntmdNH3SnsrPreliminaryFMI "Used to identify the applicable J1939-73 FMI detected in the aftertreatment SCR intermediate NH3 sensor by the manufacturer’s sensor control software in exhaust bank 2. When there is no failure FMI 31 is sent. In the case of multiple failures the ...";
CM_ SG_ 2431661310 IntmdNH3 "The amount of NH3 in the exhaust aftertreatment system measured by a NH3 sensor at an intermediate point in the SCR system, represented in NH3 molecule parts per million non-NH3 molecules in exhaust bank 2.";
CM_ BO_ 2431661054 "Aftertreatment 1 SCR Ammonia Information 2
This message contains aftertreatment intermediate ammonia information for aftertreatment system 1 (or bank 1).";
CM_ SG_ 2431661054 IntmdNH3SnsrHtrCtrl "Indicates the heater status in the warm-up process. Upon receiving a power-up command, the NH3 sensor ramps up according to a manufacturer defined profile. The Preheat 1, Preheat 2, and Automatic messages are regions within this profile in exhaust ...";
CM_ SG_ 2431661054 IntmdNH3SnsrHtrPreliminaryFMI "Used to identify the applicable J1939-73 FMI detected in the heater of the outlet NH3 exhaust sensor by the manufacturer’s sensor control software in exhaust bank 1. When there is no failure FMI 31 is sent. In the case of multiple failures the most ...";
CM_ SG_ 2431661054 IntmdNH3SnsrAtTemp "Indicates that the heater element of the aftertreatment SCR intermediate NH3 sensor is within the manufacturer’s specified range for accurate measurements in exhaust bank 1.
00 - Heater element is not in range
01 - Heater element is in range
10 - ...";
CM_ SG_ 2431661054 IntmdNH3SnsrPwrInRange "Indicates that the power supplied to the aftertreatment SCR intermediate NH3 sensor is within the manufacturer’s specification in exhaust bank 1.

00 - Power is not in range
01 - Power is in range
10 - Error
11 - Not available";
CM_ SG_ 2431661054 IntmdNH3ReadingStable "Indicates that the NH3 reading of the aftertreatment SCR intermediate NH3 sensor is stable as determined by the manufacturer’s control software in exhaust bank 1.

00 - Reading is not stable
01 - Reading is stable
10 - Error
11 - Not available";
CM_ SG_ 2431661054 IntmdNH3SnsrPreliminaryFMI "Used to identify the applicable J1939-73 FMI detected in the aftertreatment SCR intermediate NH3 sensor by the manufacturer’s sensor control software in exhaust bank 1. When there is no failure FMI 31 is sent. In the case of multiple failures the ...";
CM_ SG_ 2431661054 IntmdNH3 "The amount of NH3 in the exhaust aftertreatment system measured by a NH3 sensor at an intermediate point in the SCR system, represented in NH3 molecule parts per million non-NH3 molecules in exhaust bank 1.";
CM_ BO_ 2230334206 "Linear Displacement Sensor
The Linear Displacement Sensor is an electromechanical sensor that detects the distance of an object from the body of the sensor.";
CM_ SG_ 2230334206 LnrDsplcmntSnsrSnsrFigureOfMerit "Figure of Merit sensor status of Linear Displacement Sensor.

00    Sensor fully functional
01    Sensor degraded
10    Sensor failed
11    Sensor not available";
CM_ SG_ 2230334206 MeasuredLinearDisplacement "Distance to target as measured by the Linear Displacement Sensor.";
CM_ BO_ 2230333950 "Wand Sensor
The wand sensor is an electromechanical sensor that detects the angle of deflection of a wand.";
CM_ SG_ 2230333950 WandSensorFigureOfMerit "Figure of Merit sensor status for a wand sensor.

00    Sensor fully functional
01    Sensor degraded
10    Sensor failed
11    Sensor not available";
CM_ SG_ 2230333950 WandAngle "A wand sensor measures the angle of deflection of a wand from its null position. This parameter reports the measured angle of a wand sensor.";
CM_ BO_ 2364551422 "Wireless Status
Carries commands received by the wireless transceiver from an off-board transmitter and conveys
the status of the on-board wireless transceiver. The message originates from the on-board wireless
transceiver and is directed to an ...";
CM_ SG_ 2364551422 WirelessSignalStrength1 "The absolute received signal strength of the signal received from the off-board transmitter. The signal strength is reported as a Received Signal Strength Indicator (RSSI) value calculated in dBm.";
CM_ SG_ 2364551422 TransmitterID1 "The ID of the off-board transmitter that sent the incoming message received by the wireless transceiver.";
CM_ SG_ 2364551422 TransmitterCmdState "The command contained in the signal received by the wireless transceiver from an off-board transmitter.
0000b - Stop
0001b - Clear
0010b - Field Test
0011b - Transmitter Test
0100b - Standby
0101b to 1101b - Reserved
1110b - Error
1111b - ...";
CM_ SG_ 2364551422 WirelessRollingMessageCounter "A counter incremented with each instance of the Wireless Status message. The counter shall increment from 0 to 64255, rolling over to 0 on the next increment after 64255. The enables recipients of the Wireless Status message to detect problems with ...";
CM_ BO_ 2364551166 "Advanced Emergency Braking System 1
Advanced Emergency Braking System message 1.";
CM_ SG_ 2364551166 TmeToCollisionWithRelevantObject "The time to collision is the duration after which the predicted travelling paths of host vehicle and relevant object lead to a distance of 0m between both.
Note:  It is up to the system manufacturer to choose a suitable calculation method to ...";
CM_ SG_ 2364551166 BndOffPrbabilityOfRelevantObject "Probabilty if monitored relevant object might start a turning maneuver, which could clear the travelling path of the host vehicle.
000 - no indication for a bend off maneuver of the relevant object
001 - low probability for a bend off maneuver of ...";
CM_ SG_ 2364551166 RlvntObjctDtctdFrAdvncdEmrgncyBr "Indication if the advanced emergency braking system (AEBS) is monitoring a relevant object
000 - no relevant object monitored
001 - relevant object is being monitored
010 - relevant object is not being detected reliably
011..101 - reserved
110 ...";
CM_ SG_ 2364551166 CollisionWarningLevel "To implement different HMI (human machine interface) concepts, e.g. visual only, visual/audible, different warning tones etc., the AEBS provides different levels of collision warning.
0000 - no warning
0001 - warning level 1 - lowest
0010 - ...";
CM_ SG_ 2364551166 AdvncdEmrgencyBrakingSystemState "Current operational state of advanced emergency braking system
0000 - system is not ready (initialization not finished)
0001 - system is temporarily not available (e.g. due to boundary conditions necessary for operation)
0010 - system is ...";
CM_ BO_ 2566730238 "Fan Drive #2
This parameter group transfers status and measured information for a second engine coolant fan.  For systems with a single or the primary fan, see PGN 65213.";
CM_ SG_ 2566730238 Fan2DriveBypassCmdStatus "Status of the Fan Drive Bypass Command for the second fan as being commanded by the ECU.  The fan drive bypass diverts pump pressure away from the hydraulic motor to maintain the fan drive pressure.  0% is defined as no bypass (i.e. diverting no fan ...";
CM_ SG_ 2566730238 HydFan2MotorPress "The hydraulic pressure used to drive the second fan system, sensed before the hydraulic fan motor.";
CM_ SG_ 2566730238 Fan2Speed "The speed of the second fan associated with engine coolant system.";
CM_ SG_ 2566730238 Fan2DriveState "This parameter is used to indicate the current state or mode of operation by the second fan drive.
0000 Fan off
0001 Engine system-General
0010 Excessive engine air temperature
0011 Excessive engine oil temperature
0100 Excessive engine coolant ...";
CM_ SG_ 2566730238 EstPercentFan2Speed "Estimated fan speed as a ratio of the fan drive (current speed) to the fully engaged fan drive (maximum fan speed).  A two state fan (off/on) will use 0% and 100% respectively.  A three state fan (off/intermediate/on) will use 0%, 50% and 100% ...";
CM_ BO_ 2566711038 "Vehicle/Chassis Lubrication System 2
Reports vehicle/chassis lubrication systems status";
CM_ SG_ 2566711038 LubricationTimingCycleStatus "Reports the status of the lubrication activation clock.
00 - Paused
01 - Enabled
10 - Error
11 - Not available or not installed
Note:  In some vehicles or machines, lubrication is only required when the vehicle or machine is in certain state e ...";
CM_ SG_ 2566711038 LubricationReservoirLevel "Reports the status of the lubrication system reservior level.  The lubrication reservoir stores the grease for the lubrication system. The lubrication pump draws grease from this reservoir and pushes it into the vehicle/chassis joints
00 - ...";
CM_ SG_ 2566711038 LubricationPumpEnableStatus "Reports the operational status of the lubrication system pump.  In the disabled state, the lubrication pump will not run a lubrication cycle.  In the enabled state, the lubrication system will perform normal operations.
00 - Disabled
01 - Enabled
 ...";
CM_ SG_ 2566711038 LubricationOperationModeStatus "Reports the current operational mode status of the lubrication system.
Automatic is the normal operation mode of lubrication system. In this mode the operator has the privilege to change duty cycle mode, if the lubrication mode in not locked.
In ...";
CM_ SG_ 2566711038 LubricationCycleModeStatus "Reports the current lubrication cycle mode of the lubrication system
000 - Cycle mode # 1 (Lowest Lubrication Frequency)
001 - Cycle mode # 2
010 - Cycle mode # 3 (Highest Lubrication Frequency)
011 to 101 - Reserved
110 - Error
111 - Not ...";
CM_ SG_ 2566711038 LubricationCycleModeLockStatus "Reports status of the ability to change the lubrication cycle mode.  Locking the lubrication mode would prevent the changing of the lubrication cycle mode, perhaps by an operator

00 - Not Locked
01 - Locked
10 - Error
11 - Not available";
CM_ BO_ 2566710782 "Hydraulic Oil Properties
Hydraulic Oil Properties.  This hydraulic fluid is for the entire hydraulics system of a piece of equipment.";
CM_ SG_ 2566710782 HydOilTemp "Hydraulic Oil Temperature.  This hydraulic fluid is for the entire hydraulics system of a piece of equipment.";
CM_ SG_ 2566710782 HydOilRelativeDielectricity "Hydraulic oil relative dielectricity used to describe the hydraulic oil quality.  This hydraulic fluid is for the entire hydraulics system of a piece of equipment.";
CM_ SG_ 2566710782 HydOilDensity "Density of hydraulic oil.  This hydraulic fluid is for the entire hydraulics system of a piece of equipment.";
CM_ SG_ 2566710782 HydOilDynamicViscosity "Dynamic viscosity of hydraulic oil.  This hydraulic fluid is for the entire hydraulics system of a piece of equipment.";
CM_ BO_ 2566710526 "Engine Fuel Properties
Engine Fuel Properties";
CM_ SG_ 2566710526 EngFuelTemp "Engine Fuel Temperature of the first fuel type. See also SPNs 174 or 3468 for alternate resolution.";
CM_ SG_ 2566710526 EngFuelDielectricity "Engine fuel relative dielectricity.";
CM_ SG_ 2566710526 EngFuelDensity "Density of engine fuel";
CM_ SG_ 2566710526 EngFuelDynamicViscosity "Dynamic viscosity of engine fuel";
CM_ BO_ 2432492542 "Engine Exhaust Brake Control
Contains information about the engine exhaust brake system control.";
CM_ SG_ 2432492542 DsredEngTurbo2TurbineOutletPress "The desired gage pressure of the combustion by-products exiting the turbine side of the turbocharger 5 at the current engine operating conditions.";
CM_ SG_ 2432492542 EngTurbo2TurbineOutletPress "Gage pressure of the combustion by-products exiting the turbine side of the turbocharger 2.";
CM_ SG_ 2432492542 EngExhaustBrakeActuatorCmd "The control command applied to the engine exhaust brake actuator, where 0% represents no braking and 100% represents full braking.";
CM_ SG_ 2432492542 DsredEngTurbo1TurbineOutletPress "The desired gage pressure of the combustion by-products exiting the turbine side of the turbocharger 1 at the current engine operating conditions.";
CM_ SG_ 2432492542 EngTurbo1TurbineOutletPress "Gage pressure of the combustion by-products exiting the turbine side of the turbocharger 1.";
BA_DEF_ SG_  "SigType" ENUM  "Default","Range","RangeSigned","ASCII","Discrete","Control","ReferencePGN","DTC","StringDelimiter","StringLength","StringLengthControl","MessageCounter","MessageChecksum";
BA_DEF_ SG_  "GenSigStartValue" INT 0 2147483647;
BA_DEF_ SG_  "GenSigSendType" ENUM  "Cyclic","OnWrite","OnWriteWithRepetition","OnChange","OnChangeWithRepetition","IfActive","IfActiveWithRepetition","NoSigSendType";
BA_DEF_ SG_  "GenSigILSupport" ENUM  "No","Yes";
BA_DEF_ SG_  "GenSigEVName" STRING ;
BA_DEF_ SG_  "SPN" INT 0 524287;
BA_DEF_ BO_  "TpJ1939VarDlc" ENUM  "No","Yes";
BA_DEF_ BO_  "GenMsgCycleTimeFast" INT 0 3600000;
BA_DEF_ BO_  "GenMsgStartDelayTime" INT 0 100000;
BA_DEF_ BO_  "GenMsgILSupport" ENUM  "No","Yes";
BA_DEF_ BO_  "GenMsgDelayTime" INT 0 1000;
BA_DEF_ BO_  "GenMsgRequestable" INT 0 1;
BA_DEF_ BO_  "GenMsgSendType" ENUM  "cyclic","NotUsed","NotUsed","NotUsed","NotUsed","NotUsed","NotUsed","IfActive","noMsgSendType";
BA_DEF_ BO_  "VFrameFormat" ENUM  "StandardCAN","ExtendedCAN","reserved","J1939PG";
BA_DEF_ BO_  "GenMsgCycleTime" INT 0 3600000;
BA_DEF_ SG_  "SystemSignalLongSymbol" STRING ;
BA_DEF_DEF_  "SigType" "Default";
BA_DEF_DEF_  "GenSigStartValue" 0;
BA_DEF_DEF_  "GenSigSendType" "NoSigSendType";
BA_DEF_DEF_  "GenSigILSupport" "Yes";
BA_DEF_DEF_  "GenSigEVName" "Env@Nodename_@Signame";
BA_DEF_DEF_  "SPN" 0;
BA_DEF_DEF_  "TpJ1939VarDlc" "No";
BA_DEF_DEF_  "GenMsgCycleTimeFast" 0;
BA_DEF_DEF_  "GenMsgStartDelayTime" 0;
BA_DEF_DEF_  "GenMsgILSupport" "Yes";
BA_DEF_DEF_  "GenMsgDelayTime" 0;
BA_DEF_DEF_  "GenMsgRequestable" 1;
BA_DEF_DEF_  "GenMsgSendType" "noMsgSendType";
BA_DEF_DEF_  "VFrameFormat" "J1939PG";
BA_DEF_DEF_  "GenMsgCycleTime" 0;
BA_DEF_DEF_  "SystemSignalLongSymbol" "";
BA_ "TpJ1939VarDlc" BO_ 2566705662 1;
BA_ "GenMsgSendType" BO_ 2349465342 0;
BA_ "GenMsgCycleTime" BO_ 2349465342 100;
BA_ "GenMsgSendType" BO_ 2364553726 0;
BA_ "GenMsgCycleTime" BO_ 2364553726 20;
BA_ "GenMsgSendType" BO_ 2364553470 0;
BA_ "GenMsgCycleTime" BO_ 2364553470 20;
BA_ "GenMsgSendType" BO_ 2364553214 0;
BA_ "GenMsgCycleTime" BO_ 2364553214 100;
BA_ "GenMsgSendType" BO_ 2364546814 0;
BA_ "GenMsgCycleTime" BO_ 2364546814 20;
BA_ "TpJ1939VarDlc" BO_ 2565865214 1;
BA_ "GenMsgDelayTime" BO_ 2559049470 100;
BA_ "GenMsgSendType" BO_ 2559049470 0;
BA_ "GenMsgCycleTime" BO_ 2559049470 1000;
BA_ "GenMsgCycleTimeFast" BO_ 2349596414 10;
BA_ "GenMsgSendType" BO_ 2349596414 0;
BA_ "GenMsgCycleTime" BO_ 2349596414 50;
BA_ "GenMsgRequestable" BO_ 2563702526 0;
BA_ "GenMsgRequestable" BO_ 2563636990 0;
BA_ "GenMsgRequestable" BO_ 2563309310 0;
BA_ "GenMsgRequestable" BO_ 2563243774 0;
BA_ "GenMsgDelayTime" BO_ 2558983934 100;
BA_ "GenMsgSendType" BO_ 2558983934 0;
BA_ "GenMsgCycleTime" BO_ 2558983934 100;
BA_ "GenMsgSendType" BO_ 2349727486 0;
BA_ "GenMsgCycleTime" BO_ 2349727486 50;
BA_ "GenMsgSendType" BO_ 2550988542 0;
BA_ "GenMsgCycleTime" BO_ 2550988542 50;
BA_ "GenMsgSendType" BO_ 2566706686 0;
BA_ "GenMsgCycleTime" BO_ 2566706686 500;
BA_ "GenMsgSendType" BO_ 2566704126 0;
BA_ "GenMsgCycleTime" BO_ 2566704126 100;
BA_ "GenMsgSendType" BO_ 2566703870 0;
BA_ "GenMsgCycleTime" BO_ 2566703870 100;
BA_ "GenMsgSendType" BO_ 2566703614 0;
BA_ "GenMsgCycleTime" BO_ 2566703614 100;
BA_ "GenMsgDelayTime" BO_ 2566703358 100;
BA_ "GenMsgSendType" BO_ 2566703358 0;
BA_ "GenMsgCycleTime" BO_ 2566703358 1000;
BA_ "GenMsgSendType" BO_ 2566702590 0;
BA_ "GenMsgCycleTime" BO_ 2566702590 500;
BA_ "GenMsgSendType" BO_ 2566702334 0;
BA_ "GenMsgCycleTime" BO_ 2566702334 500;
BA_ "GenMsgSendType" BO_ 2566702078 0;
BA_ "GenMsgCycleTime" BO_ 2566702078 200;
BA_ "GenMsgDelayTime" BO_ 2566701822 100;
BA_ "GenMsgSendType" BO_ 2566701822 0;
BA_ "GenMsgCycleTime" BO_ 2566701822 1000;
BA_ "GenMsgSendType" BO_ 2431661310 0;
BA_ "GenMsgCycleTime" BO_ 2431661310 50;
BA_ "GenMsgSendType" BO_ 2431661054 0;
BA_ "GenMsgCycleTime" BO_ 2431661054 50;
BA_ "GenMsgSendType" BO_ 2230334206 0;
BA_ "GenMsgCycleTime" BO_ 2230334206 20;
BA_ "GenMsgSendType" BO_ 2230333950 0;
BA_ "GenMsgCycleTime" BO_ 2230333950 20;
BA_ "GenMsgSendType" BO_ 2364551422 0;
BA_ "GenMsgCycleTime" BO_ 2364551422 50;
BA_ "GenMsgDelayTime" BO_ 2364551166 10;
BA_ "GenMsgSendType" BO_ 2364551166 0;
BA_ "GenMsgCycleTime" BO_ 2364551166 50;
BA_ "GenMsgSendType" BO_ 2566730238 0;
BA_ "GenMsgCycleTime" BO_ 2566730238 1000;
BA_ "GenMsgSendType" BO_ 2566711038 0;
BA_ "GenMsgCycleTime" BO_ 2566711038 500;
BA_ "GenMsgSendType" BO_ 2566710782 0;
BA_ "GenMsgCycleTime" BO_ 2566710782 30000;
BA_ "GenMsgSendType" BO_ 2566710526 0;
BA_ "GenMsgCycleTime" BO_ 2566710526 30000;
BA_ "GenMsgSendType" BO_ 2432492542 0;
BA_ "GenMsgCycleTime" BO_ 2432492542 100;
BA_ "SigType" SG_ 2566705662 DTC1 7;
BA_ "SigType" SG_ 2566705662 FlashProtectLamp 5;
BA_ "SPN" SG_ 2566705662 FlashProtectLamp 3041;
BA_ "SigType" SG_ 2566705662 FlashAmberWarningLamp 5;
BA_ "SPN" SG_ 2566705662 FlashAmberWarningLamp 3040;
BA_ "SigType" SG_ 2566705662 FlashRedStopLamp 5;
BA_ "SPN" SG_ 2566705662 FlashRedStopLamp 3039;
BA_ "SigType" SG_ 2566705662 FlashMalfuncIndicatorLamp 5;
BA_ "SPN" SG_ 2566705662 FlashMalfuncIndicatorLamp 3038;
BA_ "SigType" SG_ 2566705662 ProtectLampStatus 5;
BA_ "SPN" SG_ 2566705662 ProtectLampStatus 987;
BA_ "SigType" SG_ 2566705662 AmberWarningLampStatus 5;
BA_ "SPN" SG_ 2566705662 AmberWarningLampStatus 624;
BA_ "SigType" SG_ 2566705662 RedStopLampState 4;
BA_ "SPN" SG_ 2566705662 RedStopLampState 623;
BA_ "SigType" SG_ 2566705662 MalfunctionIndicatorLampStatus 5;
BA_ "SPN" SG_ 2566705662 MalfunctionIndicatorLampStatus 1213;
BA_ "SigType" SG_ 2566705662 DTC5 7;
BA_ "SigType" SG_ 2566705662 DTC4 7;
BA_ "SigType" SG_ 2566705662 DTC3 7;
BA_ "SigType" SG_ 2566705662 DTC2 7;
BA_ "SPN" SG_ 2349465342 StaticRollAngleStatus_5583 5583;
BA_ "SigType" SG_ 2349465342 StaticRollAngle_5582 1;
BA_ "GenSigStartValue" SG_ 2349465342 StaticRollAngle_5582 35;
BA_ "SPN" SG_ 2349465342 StaticRollAngle_5582 5582;
BA_ "SigType" SG_ 2498777086 EngCyl2AverageCombustionDuration 1;
BA_ "SPN" SG_ 2498777086 EngCyl2AverageCombustionDuration 6490;
BA_ "SigType" SG_ 2498777086 EngCyl2AvrgCntrOfCmbustionTiming 1;
BA_ "SPN" SG_ 2498777086 EngCyl2AvrgCntrOfCmbustionTiming 6489;
BA_ "SigType" SG_ 2498777086 EngCyl2AvrgStrtOfCmbustionTiming 1;
BA_ "SPN" SG_ 2498777086 EngCyl2AvrgStrtOfCmbustionTiming 6488;
BA_ "SigType" SG_ 2498777086 EngCyl2IndctedMeanEffectivePress 1;
BA_ "SPN" SG_ 2498777086 EngCyl2IndctedMeanEffectivePress 6487;
BA_ "SigType" SG_ 2498776830 EngCyl1AverageCombustionDuration 1;
BA_ "SPN" SG_ 2498776830 EngCyl1AverageCombustionDuration 6486;
BA_ "SigType" SG_ 2498776830 EngCyl1AvrgCntrOfCmbustionTiming 1;
BA_ "SPN" SG_ 2498776830 EngCyl1AvrgCntrOfCmbustionTiming 6485;
BA_ "SigType" SG_ 2498776830 EngCyl1AvrgStrtOfCmbustionTiming 1;
BA_ "SPN" SG_ 2498776830 EngCyl1AvrgStrtOfCmbustionTiming 6484;
BA_ "SigType" SG_ 2498776830 EngCyl1IndctedMeanEffectivePress 1;
BA_ "SPN" SG_ 2498776830 EngCyl1IndctedMeanEffectivePress 6483;
BA_ "SigType" SG_ 2364558846 MaxPressIncreaseRate 1;
BA_ "SPN" SG_ 2364558846 MaxPressIncreaseRate 7648;
BA_ "SigType" SG_ 2364558846 LowFreqKnockLvl 1;
BA_ "SPN" SG_ 2364558846 LowFreqKnockLvl 7628;
BA_ "SPN" SG_ 2364558846 EngCyl20PrssSensorPreliminaryFMI 6475;
BA_ "SigType" SG_ 2364558846 EngCyl20SynchronousKnockLevel 1;
BA_ "SPN" SG_ 2364558846 EngCyl20SynchronousKnockLevel 6474;
BA_ "SigType" SG_ 2364558846 EngCyl20PeakPress 1;
BA_ "SPN" SG_ 2364558846 EngCyl20PeakPress 6473;
BA_ "SigType" SG_ 2364558846 EngCyl20HeatRelease 1;
BA_ "SPN" SG_ 2364558846 EngCyl20HeatRelease 6472;
BA_ "SigType" SG_ 2364558590 MaxPressIncreaseRate 1;
BA_ "SPN" SG_ 2364558590 MaxPressIncreaseRate 7647;
BA_ "SigType" SG_ 2364558590 LowFreqKnockLvl 1;
BA_ "SPN" SG_ 2364558590 LowFreqKnockLvl 7627;
BA_ "SPN" SG_ 2364558590 EngCyl19PrssSensorPreliminaryFMI 6471;
BA_ "SigType" SG_ 2364558590 EngCyl19SynchronousKnockLevel 1;
BA_ "SPN" SG_ 2364558590 EngCyl19SynchronousKnockLevel 6470;
BA_ "SigType" SG_ 2364558590 EngCyl19PeakPress 1;
BA_ "SPN" SG_ 2364558590 EngCyl19PeakPress 6469;
BA_ "SigType" SG_ 2364558590 EngCyl19HeatRelease 1;
BA_ "SPN" SG_ 2364558590 EngCyl19HeatRelease 6468;
BA_ "SigType" SG_ 2364558334 MaxPressIncreaseRate 1;
BA_ "SPN" SG_ 2364558334 MaxPressIncreaseRate 7646;
BA_ "SigType" SG_ 2364558334 LowFreqKnockLvl 1;
BA_ "SPN" SG_ 2364558334 LowFreqKnockLvl 7626;
BA_ "SPN" SG_ 2364558334 EngCyl18PrssSensorPreliminaryFMI 6467;
BA_ "SigType" SG_ 2364558334 EngCyl18SynchronousKnockLevel 1;
BA_ "SPN" SG_ 2364558334 EngCyl18SynchronousKnockLevel 6466;
BA_ "SigType" SG_ 2364558334 EngCyl18PeakPress 1;
BA_ "SPN" SG_ 2364558334 EngCyl18PeakPress 6465;
BA_ "SigType" SG_ 2364558334 EngCyl18HeatRelease 1;
BA_ "SPN" SG_ 2364558334 EngCyl18HeatRelease 6464;
BA_ "SigType" SG_ 2364558078 MaxPressIncreaseRate 1;
BA_ "SPN" SG_ 2364558078 MaxPressIncreaseRate 7645;
BA_ "SigType" SG_ 2364558078 LowFreqKnockLvl 1;
BA_ "SPN" SG_ 2364558078 LowFreqKnockLvl 7625;
BA_ "SPN" SG_ 2364558078 EngCyl17PrssSensorPreliminaryFMI 6463;
BA_ "SigType" SG_ 2364558078 EngCyl17SynchronousKnockLevel 1;
BA_ "SPN" SG_ 2364558078 EngCyl17SynchronousKnockLevel 6462;
BA_ "SigType" SG_ 2364558078 EngCyl17PeakPress 1;
BA_ "SPN" SG_ 2364558078 EngCyl17PeakPress 6461;
BA_ "SigType" SG_ 2364558078 EngCyl17HeatRelease 1;
BA_ "SPN" SG_ 2364558078 EngCyl17HeatRelease 6460;
BA_ "SigType" SG_ 2364557822 MaxPressIncreaseRate 1;
BA_ "SPN" SG_ 2364557822 MaxPressIncreaseRate 7644;
BA_ "SigType" SG_ 2364557822 LowFreqKnockLvl 1;
BA_ "SPN" SG_ 2364557822 LowFreqKnockLvl 7624;
BA_ "SPN" SG_ 2364557822 EngCyl16PrssSensorPreliminaryFMI 6459;
BA_ "SigType" SG_ 2364557822 EngCyl16SynchronousKnockLevel 1;
BA_ "SPN" SG_ 2364557822 EngCyl16SynchronousKnockLevel 6458;
BA_ "SigType" SG_ 2364557822 EngCyl16PeakPress 1;
BA_ "SPN" SG_ 2364557822 EngCyl16PeakPress 6457;
BA_ "SigType" SG_ 2364557822 EngCyl16HeatRelease 1;
BA_ "SPN" SG_ 2364557822 EngCyl16HeatRelease 6456;
BA_ "SigType" SG_ 2364557566 MaxPressIncreaseRate 1;
BA_ "SPN" SG_ 2364557566 MaxPressIncreaseRate 7643;
BA_ "SigType" SG_ 2364557566 LowFreqKnockLvl 1;
BA_ "SPN" SG_ 2364557566 LowFreqKnockLvl 7623;
BA_ "SPN" SG_ 2364557566 EngCyl15PrssSensorPreliminaryFMI 6455;
BA_ "SigType" SG_ 2364557566 EngCyl15SynchronousKnockLevel 1;
BA_ "SPN" SG_ 2364557566 EngCyl15SynchronousKnockLevel 6454;
BA_ "SigType" SG_ 2364557566 EngCyl15PeakPress 1;
BA_ "SPN" SG_ 2364557566 EngCyl15PeakPress 6453;
BA_ "SigType" SG_ 2364557566 EngCyl15HeatRelease 1;
BA_ "SPN" SG_ 2364557566 EngCyl15HeatRelease 6452;
BA_ "SigType" SG_ 2364557310 MaxPressIncreaseRate 1;
BA_ "SPN" SG_ 2364557310 MaxPressIncreaseRate 7642;
BA_ "SigType" SG_ 2364557310 LowFreqKnockLvl 1;
BA_ "SPN" SG_ 2364557310 LowFreqKnockLvl 7622;
BA_ "SPN" SG_ 2364557310 EngCyl14PrssSensorPreliminaryFMI 6451;
BA_ "SigType" SG_ 2364557310 EngCyl14SynchronousKnockLevel 1;
BA_ "SPN" SG_ 2364557310 EngCyl14SynchronousKnockLevel 6450;
BA_ "SigType" SG_ 2364557310 EngCyl14PeakPress 1;
BA_ "SPN" SG_ 2364557310 EngCyl14PeakPress 6449;
BA_ "SigType" SG_ 2364557310 EngCyl14HeatRelease 1;
BA_ "SPN" SG_ 2364557310 EngCyl14HeatRelease 6448;
BA_ "SigType" SG_ 2364557054 MaxPressIncreaseRate 1;
BA_ "SPN" SG_ 2364557054 MaxPressIncreaseRate 7641;
BA_ "SigType" SG_ 2364557054 LowFreqKnockLvl 1;
BA_ "SPN" SG_ 2364557054 LowFreqKnockLvl 7621;
BA_ "SPN" SG_ 2364557054 EngCyl13PrssSensorPreliminaryFMI 6447;
BA_ "SigType" SG_ 2364557054 EngCyl13SynchronousKnockLevel 1;
BA_ "SPN" SG_ 2364557054 EngCyl13SynchronousKnockLevel 6446;
BA_ "SigType" SG_ 2364557054 EngCyl13PeakPress 1;
BA_ "SPN" SG_ 2364557054 EngCyl13PeakPress 6445;
BA_ "SigType" SG_ 2364557054 EngCyl13HeatRelease 1;
BA_ "SPN" SG_ 2364557054 EngCyl13HeatRelease 6444;
BA_ "SigType" SG_ 2364556798 MaxPressIncreaseRate 1;
BA_ "SPN" SG_ 2364556798 MaxPressIncreaseRate 7640;
BA_ "SigType" SG_ 2364556798 LowFreqKnockLvl 1;
BA_ "SPN" SG_ 2364556798 LowFreqKnockLvl 7620;
BA_ "SPN" SG_ 2364556798 EngCyl12PrssSensorPreliminaryFMI 6443;
BA_ "SigType" SG_ 2364556798 EngCyl12SynchronousKnockLevel 1;
BA_ "SPN" SG_ 2364556798 EngCyl12SynchronousKnockLevel 6442;
BA_ "SigType" SG_ 2364556798 EngCyl12PeakPress 1;
BA_ "SPN" SG_ 2364556798 EngCyl12PeakPress 6441;
BA_ "SigType" SG_ 2364556798 EngCyl12HeatRelease 1;
BA_ "SPN" SG_ 2364556798 EngCyl12HeatRelease 6440;
BA_ "SigType" SG_ 2364556542 MaxPressIncreaseRate 1;
BA_ "SPN" SG_ 2364556542 MaxPressIncreaseRate 7639;
BA_ "SigType" SG_ 2364556542 LowFreqKnockLvl 1;
BA_ "SPN" SG_ 2364556542 LowFreqKnockLvl 7619;
BA_ "SPN" SG_ 2364556542 EngCyl11PrssSensorPreliminaryFMI 6439;
BA_ "SigType" SG_ 2364556542 EngCyl11SynchronousKnockLevel 1;
BA_ "SPN" SG_ 2364556542 EngCyl11SynchronousKnockLevel 6438;
BA_ "SigType" SG_ 2364556542 EngCyl11PeakPress 1;
BA_ "SPN" SG_ 2364556542 EngCyl11PeakPress 6437;
BA_ "SigType" SG_ 2364556542 EngCyl11HeatRelease 1;
BA_ "SPN" SG_ 2364556542 EngCyl11HeatRelease 6436;
BA_ "SigType" SG_ 2364556286 MaxPressIncreaseRate 1;
BA_ "SPN" SG_ 2364556286 MaxPressIncreaseRate 7638;
BA_ "SigType" SG_ 2364556286 LowFreqKnockLvl 1;
BA_ "SPN" SG_ 2364556286 LowFreqKnockLvl 7618;
BA_ "SPN" SG_ 2364556286 EngCyl10PrssSensorPreliminaryFMI 6435;
BA_ "SigType" SG_ 2364556286 EngCyl10SynchronousKnockLevel 1;
BA_ "SPN" SG_ 2364556286 EngCyl10SynchronousKnockLevel 6434;
BA_ "SigType" SG_ 2364556286 EngCyl10PeakPress 1;
BA_ "SPN" SG_ 2364556286 EngCyl10PeakPress 6433;
BA_ "SigType" SG_ 2364556286 EngCyl10HeatRelease 1;
BA_ "SPN" SG_ 2364556286 EngCyl10HeatRelease 6432;
BA_ "SigType" SG_ 2364556030 MaxPressIncreaseRate 1;
BA_ "SPN" SG_ 2364556030 MaxPressIncreaseRate 7637;
BA_ "SigType" SG_ 2364556030 LowFreqKnockLvl 1;
BA_ "SPN" SG_ 2364556030 LowFreqKnockLvl 7617;
BA_ "SPN" SG_ 2364556030 EngCyl9PressSensorPreliminaryFMI 6431;
BA_ "SigType" SG_ 2364556030 EngCyl9SynchronousKnockLevel 1;
BA_ "SPN" SG_ 2364556030 EngCyl9SynchronousKnockLevel 6430;
BA_ "SigType" SG_ 2364556030 EngCyl9PeakPress 1;
BA_ "SPN" SG_ 2364556030 EngCyl9PeakPress 6429;
BA_ "SigType" SG_ 2364556030 EngCyl9HeatRelease 1;
BA_ "SPN" SG_ 2364556030 EngCyl9HeatRelease 6428;
BA_ "SigType" SG_ 2364555774 MaxPressIncreaseRate 1;
BA_ "SPN" SG_ 2364555774 MaxPressIncreaseRate 7636;
BA_ "SigType" SG_ 2364555774 LowFreqKnockLvl 1;
BA_ "SPN" SG_ 2364555774 LowFreqKnockLvl 7616;
BA_ "SPN" SG_ 2364555774 EngCyl8PressSensorPreliminaryFMI 6427;
BA_ "SigType" SG_ 2364555774 EngCyl8SynchronousKnockLevel 1;
BA_ "SPN" SG_ 2364555774 EngCyl8SynchronousKnockLevel 6426;
BA_ "SigType" SG_ 2364555774 EngCyl8PeakPress 1;
BA_ "SPN" SG_ 2364555774 EngCyl8PeakPress 6425;
BA_ "SigType" SG_ 2364555774 EngCyl8HeatRelease 1;
BA_ "SPN" SG_ 2364555774 EngCyl8HeatRelease 6424;
BA_ "SigType" SG_ 2364555518 MaxPressIncreaseRate 1;
BA_ "SPN" SG_ 2364555518 MaxPressIncreaseRate 7635;
BA_ "SigType" SG_ 2364555518 LowFreqKnockLvl 1;
BA_ "SPN" SG_ 2364555518 LowFreqKnockLvl 7615;
BA_ "SPN" SG_ 2364555518 EngCyl7PressSensorPreliminaryFMI 6423;
BA_ "SigType" SG_ 2364555518 EngCyl7SynchronousKnockLevel 1;
BA_ "SPN" SG_ 2364555518 EngCyl7SynchronousKnockLevel 6422;
BA_ "SigType" SG_ 2364555518 EngCyl7PeakPress 1;
BA_ "SPN" SG_ 2364555518 EngCyl7PeakPress 6421;
BA_ "SigType" SG_ 2364555518 EngCyl7HeatRelease 1;
BA_ "SPN" SG_ 2364555518 EngCyl7HeatRelease 6420;
BA_ "SigType" SG_ 2364555262 MaxPressIncreaseRate 1;
BA_ "SPN" SG_ 2364555262 MaxPressIncreaseRate 7634;
BA_ "SigType" SG_ 2364555262 LowFreqKnockLvl 1;
BA_ "SPN" SG_ 2364555262 LowFreqKnockLvl 7614;
BA_ "SPN" SG_ 2364555262 EngCyl6PressSensorPreliminaryFMI 6419;
BA_ "SigType" SG_ 2364555262 EngCyl6SynchronousKnockLevel 1;
BA_ "SPN" SG_ 2364555262 EngCyl6SynchronousKnockLevel 6418;
BA_ "SigType" SG_ 2364555262 EngCyl6PeakPress 1;
BA_ "SPN" SG_ 2364555262 EngCyl6PeakPress 6417;
BA_ "SigType" SG_ 2364555262 EngCyl6HeatRelease 1;
BA_ "SPN" SG_ 2364555262 EngCyl6HeatRelease 6416;
BA_ "SigType" SG_ 2364555006 MaxPressIncreaseRate 1;
BA_ "SPN" SG_ 2364555006 MaxPressIncreaseRate 7633;
BA_ "SigType" SG_ 2364555006 LowFreqKnockLvl 1;
BA_ "SPN" SG_ 2364555006 LowFreqKnockLvl 7613;
BA_ "SPN" SG_ 2364555006 EngCyl5PressSensorPreliminaryFMI 6415;
BA_ "SigType" SG_ 2364555006 EngCyl5SynchronousKnockLevel 1;
BA_ "SPN" SG_ 2364555006 EngCyl5SynchronousKnockLevel 6414;
BA_ "SigType" SG_ 2364555006 EngCyl5PeakPress 1;
BA_ "SPN" SG_ 2364555006 EngCyl5PeakPress 6413;
BA_ "SigType" SG_ 2364555006 EngCyl5HeatRelease 1;
BA_ "SPN" SG_ 2364555006 EngCyl5HeatRelease 6412;
BA_ "SigType" SG_ 2364554750 MaxPressIncreaseRate 1;
BA_ "SPN" SG_ 2364554750 MaxPressIncreaseRate 7632;
BA_ "SigType" SG_ 2364554750 LowFreqKnockLvl 1;
BA_ "SPN" SG_ 2364554750 LowFreqKnockLvl 7612;
BA_ "SPN" SG_ 2364554750 EngCyl4PressSensorPreliminaryFMI 6411;
BA_ "SigType" SG_ 2364554750 EngCyl4SynchronousKnockLevel 1;
BA_ "SPN" SG_ 2364554750 EngCyl4SynchronousKnockLevel 6410;
BA_ "SigType" SG_ 2364554750 EngCyl4PeakPress 1;
BA_ "SPN" SG_ 2364554750 EngCyl4PeakPress 6409;
BA_ "SigType" SG_ 2364554750 EngCyl4HeatRelease 1;
BA_ "SPN" SG_ 2364554750 EngCyl4HeatRelease 6408;
BA_ "SigType" SG_ 2364554494 MaxPressIncreaseRate 1;
BA_ "SPN" SG_ 2364554494 MaxPressIncreaseRate 7631;
BA_ "SigType" SG_ 2364554494 LowFreqKnockLvl 1;
BA_ "SPN" SG_ 2364554494 LowFreqKnockLvl 7611;
BA_ "SPN" SG_ 2364554494 EngCyl3PressSensorPreliminaryFMI 6407;
BA_ "SigType" SG_ 2364554494 EngCyl3SynchronousKnockLevel 1;
BA_ "SPN" SG_ 2364554494 EngCyl3SynchronousKnockLevel 6406;
BA_ "SigType" SG_ 2364554494 EngCyl3PeakPress 1;
BA_ "SPN" SG_ 2364554494 EngCyl3PeakPress 6405;
BA_ "SigType" SG_ 2364554494 EngCyl3HeatRelease 1;
BA_ "SPN" SG_ 2364554494 EngCyl3HeatRelease 6404;
BA_ "SigType" SG_ 2364554238 MaxPressIncreaseRate 1;
BA_ "SPN" SG_ 2364554238 MaxPressIncreaseRate 7630;
BA_ "SigType" SG_ 2364554238 LowFreqKnockLvl 1;
BA_ "SPN" SG_ 2364554238 LowFreqKnockLvl 7610;
BA_ "SPN" SG_ 2364554238 EngCyl2PressSensorPreliminaryFMI 6403;
BA_ "SigType" SG_ 2364554238 EngCyl2SynchronousKnockLevel 1;
BA_ "SPN" SG_ 2364554238 EngCyl2SynchronousKnockLevel 6402;
BA_ "SigType" SG_ 2364554238 EngCyl2PeakPress 1;
BA_ "SPN" SG_ 2364554238 EngCyl2PeakPress 6401;
BA_ "SigType" SG_ 2364554238 EngCyl2HeatRelease 1;
BA_ "SPN" SG_ 2364554238 EngCyl2HeatRelease 6400;
BA_ "SigType" SG_ 2364553982 MaxPressIncreaseRate 1;
BA_ "SPN" SG_ 2364553982 MaxPressIncreaseRate 7629;
BA_ "SigType" SG_ 2364553982 LowFreqKnockLvl 1;
BA_ "SPN" SG_ 2364553982 LowFreqKnockLvl 7609;
BA_ "SPN" SG_ 2364553982 EngCyl1PressSensorPreliminaryFMI 6399;
BA_ "SigType" SG_ 2364553982 EngCyl1SynchronousKnockLevel 1;
BA_ "SPN" SG_ 2364553982 EngCyl1SynchronousKnockLevel 6398;
BA_ "SigType" SG_ 2364553982 EngCyl1PeakPress 1;
BA_ "SPN" SG_ 2364553982 EngCyl1PeakPress 6397;
BA_ "SigType" SG_ 2364553982 EngCyl1HeatRelease 1;
BA_ "SPN" SG_ 2364553982 EngCyl1HeatRelease 6396;
BA_ "SigType" SG_ 2364553726 EngTotalIntakeMassAirFlowRate 1;
BA_ "SPN" SG_ 2364553726 EngTotalIntakeMassAirFlowRate 6393;
BA_ "SigType" SG_ 2364553726 EngDesiredAirFuelRatio 1;
BA_ "SPN" SG_ 2364553726 EngDesiredAirFuelRatio 6392;
BA_ "SigType" SG_ 2364553470 EngCylTorque 1;
BA_ "SPN" SG_ 2364553470 EngCylTorque 6389;
BA_ "SigType" SG_ 2364553470 EngCylDieselMassFlowRateCmd 1;
BA_ "SPN" SG_ 2364553470 EngCylDieselMassFlowRateCmd 6388;
BA_ "SigType" SG_ 2364553470 EngCylGasMassFlowRateCmd 1;
BA_ "SPN" SG_ 2364553470 EngCylGasMassFlowRateCmd 6387;
BA_ "SigType" SG_ 2364553470 EngGasFuelPercentageCmd 1;
BA_ "SPN" SG_ 2364553470 EngGasFuelPercentageCmd 6386;
BA_ "SigType" SG_ 2364553470 EngDualFuelModeCmd 5;
BA_ "SPN" SG_ 2364553470 EngDualFuelModeCmd 6792;
BA_ "SPN" SG_ 2364553214 EngTrbCmprssrBlwffActtr1OprtnStt 6316;
BA_ "SigType" SG_ 2364553214 EngTrbCmprssrBlowoffActuator1Pos 1;
BA_ "SPN" SG_ 2364553214 EngTrbCmprssrBlowoffActuator1Pos 6315;
BA_ "SigType" SG_ 2364553214 EngTrbCmprssrBlwffActtr1DsredPos 1;
BA_ "SPN" SG_ 2364553214 EngTrbCmprssrBlwffActtr1DsredPos 6314;
BA_ "SigType" SG_ 2364553214 EngTrbCmprssrBlwoffActuator1Temp 1;
BA_ "SPN" SG_ 2364553214 EngTrbCmprssrBlwoffActuator1Temp 6313;
BA_ "SPN" SG_ 2364553214 EngTrbCmprssrBlwffActtr1TmpSttus 6312;
BA_ "SPN" SG_ 2364553214 EngTrbCmprssrBlwffActtr1PrlmnryF 6311;
BA_ "SPN" SG_ 2565874430 PersistentLimitStatus 4307;
BA_ "SPN" SG_ 2565874430 MachineSelectedSpeedSource 4308;
BA_ "SigType" SG_ 2565874430 MachineSelectedDirection 4;
BA_ "SPN" SG_ 2565874430 MachineSelectedDirection 4309;
BA_ "SPN" SG_ 2565874430 MachineSelectedDistance 4306;
BA_ "SPN" SG_ 2565874430 MachineSelectedSpeed 4305;
BA_ "SigType" SG_ 2364546814 GeneratorGoverningBias 1;
BA_ "SPN" SG_ 2364546814 GeneratorGoverningBias 3938;
BA_ "SPN" SG_ 2565865214 ManufacturerSpecfn_2550 2550;
BA_ "SigType" SG_ 2566767614 AccelPedal2Channel3 1;
BA_ "SPN" SG_ 2566767614 AccelPedal2Channel3 2626;
BA_ "SigType" SG_ 2566767614 AccelPedal2Channel2 1;
BA_ "SPN" SG_ 2566767614 AccelPedal2Channel2 2625;
BA_ "SigType" SG_ 2566767614 AccelPedal1Channel3 1;
BA_ "SPN" SG_ 2566767614 AccelPedal1Channel3 2624;
BA_ "SigType" SG_ 2566767614 AccelPedal1Channel2 1;
BA_ "SPN" SG_ 2566767614 AccelPedal1Channel2 2623;
BA_ "SPN" SG_ 2559049470 EngFuelingNotDesiredReason_7855 7855;
BA_ "SPN" SG_ 2559049470 TransIdlGovrnrFuelingInhibt_7829 7829;
BA_ "SPN" SG_ 2559049470 EngineFuelingDesiredReason_7789 7789;
BA_ "SigType" SG_ 2559049470 DesiredEngFuelingState_5793 5;
BA_ "SPN" SG_ 2559049470 DesiredEngFuelingState_5793 5793;
BA_ "SPN" SG_ 2559049470 RequestedFuelType_6317 6317;
BA_ "SigType" SG_ 2559049470 EngGasFuelSupplyDsrdPress_6715 1;
BA_ "SPN" SG_ 2559049470 EngGasFuelSupplyDsrdPress_6715 6715;
BA_ "SigType" SG_ 2559049470 EngGasFuelUsageInhibited_6833 4;
BA_ "SPN" SG_ 2559049470 EngGasFuelUsageInhibited_6833 6833;
BA_ "SigType" SG_ 2349596414 AEBS2MessageChecksum_5683 12;
BA_ "SPN" SG_ 2349596414 AEBS2MessageChecksum_5683 5683;
BA_ "SigType" SG_ 2349596414 AEBS2MessageCounter_5682 11;
BA_ "SPN" SG_ 2349596414 AEBS2MessageCounter_5682 5682;
BA_ "SigType" SG_ 2349596414 DrvrActDmndFrAdvEmrgncyBrk_5681 5;
BA_ "SPN" SG_ 2349596414 DrvrActDmndFrAdvEmrgncyBrk_5681 5681;
BA_ "SPN" SG_ 2563571454 DataDictionaryRow_2427 2427;
BA_ "SPN" SG_ 2563571454 DataDictionaryColumn_2428 2428;
BA_ "SPN" SG_ 2563571454 ImplementType_2425 2425;
BA_ "SPN" SG_ 2563571454 ImplementPos_2426 2426;
BA_ "SigType" SG_ 2563571454 DataFormat_ErrorCondition_2419 4;
BA_ "SPN" SG_ 2563571454 DataFormat_ErrorCondition_2419 2419;
BA_ "SigType" SG_ 2563571454 ProcessDataType_2420 4;
BA_ "SPN" SG_ 2563571454 ProcessDataType_2420 2420;
BA_ "SPN" SG_ 2563571454 ProcessDataModifier_2421 2421;
BA_ "SPN" SG_ 2563571454 RepetitionRateParameter_2418 2418;
BA_ "SPN" SG_ 2563505918 ProcessVariableValue_2429 2429;
BA_ "SPN" SG_ 2563505918 DataDictionaryRow_2427 2427;
BA_ "SPN" SG_ 2563505918 DataDictionaryColumn_2428 2428;
BA_ "SPN" SG_ 2563505918 ImplementType_2425 2425;
BA_ "SPN" SG_ 2563505918 ImplementPos_2426 2426;
BA_ "SPN" SG_ 2563505918 CountNumber_2422 2422;
BA_ "SigType" SG_ 2563505918 DataFormat_ErrorCondition_2419 4;
BA_ "SPN" SG_ 2563505918 DataFormat_ErrorCondition_2419 2419;
BA_ "SigType" SG_ 2563505918 ProcessDataType_2420 4;
BA_ "SPN" SG_ 2563505918 ProcessDataType_2420 2420;
BA_ "SPN" SG_ 2563505918 ProcessDataModifier_2421 2421;
BA_ "SigType" SG_ 2563178238 ValveFailSafeMode_2934 4;
BA_ "SPN" SG_ 2563178238 ValveFailSafeMode_2934 2934;
BA_ "SPN" SG_ 2563178238 ValveState_2932 2932;
BA_ "SPN" SG_ 2563178238 RetractPortEstFlow_2940 2940;
BA_ "SPN" SG_ 2563178238 ExtendPortEstFlow_2939 2939;
BA_ "SPN" SG_ 2563112702 ReturnPortPress_2943 2943;
BA_ "SPN" SG_ 2563112702 RetractPortPress_2942 2942;
BA_ "SPN" SG_ 2563112702 ExtendPortPress_2941 2941;
BA_ "SPN" SG_ 2563112702 RetractPortMeasuredFlow_2938 2938;
BA_ "SPN" SG_ 2563112702 ExtendPortMeasuredFlow_2937 2937;
BA_ "SPN" SG_ 2563047166 PortFlowCmd_2944 2944;
BA_ "SystemSignalLongSymbol" SG_ 2358509310 VehicleSystemInstanceQualifierFl "VehicleSystemInstanceQualifierFlag";
BA_ "SystemSignalLongSymbol" SG_ 2358509310 ArbitraryAddressCapableQualifier "ArbitraryAddressCapableQualifierFlag";
BA_ "SigType" SG_ 2558983934 SwitchedPowerOutput18Cmd_6002 5;
BA_ "SPN" SG_ 2558983934 SwitchedPowerOutput18Cmd_6002 6002;
BA_ "SigType" SG_ 2558983934 SwitchedPowerOutput19Cmd_6001 5;
BA_ "SPN" SG_ 2558983934 SwitchedPowerOutput19Cmd_6001 6001;
BA_ "SigType" SG_ 2558983934 SwitchedPowerOutput20Cmd_6000 5;
BA_ "SPN" SG_ 2558983934 SwitchedPowerOutput20Cmd_6000 6000;
BA_ "SigType" SG_ 2558983934 SwitchedPowerOutput13Cmd_5999 5;
BA_ "SPN" SG_ 2558983934 SwitchedPowerOutput13Cmd_5999 5999;
BA_ "SigType" SG_ 2558983934 SwitchedPowerOutput14Cmd_5998 5;
BA_ "SPN" SG_ 2558983934 SwitchedPowerOutput14Cmd_5998 5998;
BA_ "SigType" SG_ 2558983934 SwitchedPowerOutput15Cmd_5997 5;
BA_ "SPN" SG_ 2558983934 SwitchedPowerOutput15Cmd_5997 5997;
BA_ "SigType" SG_ 2558983934 SwitchedPowerOutput16Cmd_5996 5;
BA_ "SPN" SG_ 2558983934 SwitchedPowerOutput16Cmd_5996 5996;
BA_ "SigType" SG_ 2558983934 SwitchedPowerOutput9Cmd_5995 5;
BA_ "SPN" SG_ 2558983934 SwitchedPowerOutput9Cmd_5995 5995;
BA_ "SigType" SG_ 2558983934 SwitchedPowerOutput10Cmd_5994 5;
BA_ "SPN" SG_ 2558983934 SwitchedPowerOutput10Cmd_5994 5994;
BA_ "SigType" SG_ 2558983934 SwitchedPowerOutput29Cmd_6015 5;
BA_ "SPN" SG_ 2558983934 SwitchedPowerOutput29Cmd_6015 6015;
BA_ "SigType" SG_ 2558983934 SwitchedPowerOutput30Cmd_6014 5;
BA_ "SPN" SG_ 2558983934 SwitchedPowerOutput30Cmd_6014 6014;
BA_ "SigType" SG_ 2558983934 SwitchedPowerOutput31Cmd_6013 5;
BA_ "SPN" SG_ 2558983934 SwitchedPowerOutput31Cmd_6013 6013;
BA_ "SigType" SG_ 2558983934 SwitchedPowerOutput32Cmd_6012 5;
BA_ "SPN" SG_ 2558983934 SwitchedPowerOutput32Cmd_6012 6012;
BA_ "SigType" SG_ 2558983934 SwitchedPowerOutput25Cmd_6011 5;
BA_ "SPN" SG_ 2558983934 SwitchedPowerOutput25Cmd_6011 6011;
BA_ "SigType" SG_ 2558983934 SwitchedPowerOutput26Cmd_6010 5;
BA_ "SPN" SG_ 2558983934 SwitchedPowerOutput26Cmd_6010 6010;
BA_ "SigType" SG_ 2558983934 SwitchedPowerOutput27Cmd_6009 5;
BA_ "SPN" SG_ 2558983934 SwitchedPowerOutput27Cmd_6009 6009;
BA_ "SigType" SG_ 2558983934 SwitchedPowerOutput28Cmd_6008 5;
BA_ "SPN" SG_ 2558983934 SwitchedPowerOutput28Cmd_6008 6008;
BA_ "SigType" SG_ 2558983934 SwitchedPowerOutput21Cmd_6007 5;
BA_ "SPN" SG_ 2558983934 SwitchedPowerOutput21Cmd_6007 6007;
BA_ "SigType" SG_ 2558983934 SwitchedPowerOutput22Cmd_6006 5;
BA_ "SPN" SG_ 2558983934 SwitchedPowerOutput22Cmd_6006 6006;
BA_ "SigType" SG_ 2558983934 SwitchedPowerOutput23Cmd_6005 5;
BA_ "SPN" SG_ 2558983934 SwitchedPowerOutput23Cmd_6005 6005;
BA_ "SigType" SG_ 2558983934 SwitchedPowerOutput24Cmd_6004 5;
BA_ "SPN" SG_ 2558983934 SwitchedPowerOutput24Cmd_6004 6004;
BA_ "SigType" SG_ 2558983934 SwitchedPowerOutput17Cmd_6003 5;
BA_ "SPN" SG_ 2558983934 SwitchedPowerOutput17Cmd_6003 6003;
BA_ "SigType" SG_ 2558983934 SwitchedPowerOutput11Cmd_5993 5;
BA_ "SPN" SG_ 2558983934 SwitchedPowerOutput11Cmd_5993 5993;
BA_ "SigType" SG_ 2558983934 SwitchedPowerOutput12Cmd_5992 5;
BA_ "SPN" SG_ 2558983934 SwitchedPowerOutput12Cmd_5992 5992;
BA_ "SigType" SG_ 2558983934 SwitchedPowerOutput5Cmd_5991 5;
BA_ "SPN" SG_ 2558983934 SwitchedPowerOutput5Cmd_5991 5991;
BA_ "SigType" SG_ 2558983934 SwitchedPowerOutput6Cmd_5990 5;
BA_ "SPN" SG_ 2558983934 SwitchedPowerOutput6Cmd_5990 5990;
BA_ "SigType" SG_ 2558983934 SwitchedPowerOutput7Cmd_5989 5;
BA_ "SPN" SG_ 2558983934 SwitchedPowerOutput7Cmd_5989 5989;
BA_ "SigType" SG_ 2558983934 SwitchedPowerOutput8Cmd_5988 5;
BA_ "SPN" SG_ 2558983934 SwitchedPowerOutput8Cmd_5988 5988;
BA_ "SigType" SG_ 2558983934 SwitchedPowerOutput1Cmd_5987 5;
BA_ "SPN" SG_ 2558983934 SwitchedPowerOutput1Cmd_5987 5987;
BA_ "SigType" SG_ 2558983934 SwitchedPowerOutput2Cmd_5986 5;
BA_ "SPN" SG_ 2558983934 SwitchedPowerOutput2Cmd_5986 5986;
BA_ "SigType" SG_ 2558983934 SwitchedPowerOutput3Cmd_5985 5;
BA_ "SPN" SG_ 2558983934 SwitchedPowerOutput3Cmd_5985 5985;
BA_ "SigType" SG_ 2558983934 SwitchedPowerOutput4Cmd_5984 5;
BA_ "SPN" SG_ 2558983934 SwitchedPowerOutput4Cmd_5984 5984;
BA_ "SigType" SG_ 2349727486 TransMode10_6570 5;
BA_ "SPN" SG_ 2349727486 TransMode10_6570 6570;
BA_ "SigType" SG_ 2349727486 TransMode9_6569 5;
BA_ "SPN" SG_ 2349727486 TransMode9_6569 6569;
BA_ "SPN" SG_ 2550988542 EngineClutchEngageReqStatus_7844 7844;
BA_ "SPN" SG_ 2550988542 ReadyForClutchEngmntStatus_7847 7847;
BA_ "SigType" SG_ 2550988542 AccelPedalPos3_28 1;
BA_ "SPN" SG_ 2550988542 AccelPedalPos3_28 28;
BA_ "SigType" SG_ 2566767358 EngFuelIsolationCtrl 5;
BA_ "SPN" SG_ 2566767358 EngFuelIsolationCtrl 7394;
BA_ "SPN" SG_ 2566767358 FuelType 5837;
BA_ "SigType" SG_ 2566767358 EngFuelMassFlowRate 1;
BA_ "SPN" SG_ 2566767358 EngFuelMassFlowRate 5833;
BA_ "SigType" SG_ 2566767358 EngExhstGsRcrcltn1Valve2PosError 1;
BA_ "SPN" SG_ 2566767358 EngExhstGsRcrcltn1Valve2PosError 5830;
BA_ "SigType" SG_ 2566767358 EngExhstGsRcrcltn1Valve1PosError 1;
BA_ "SPN" SG_ 2566767358 EngExhstGsRcrcltn1Valve1PosError 5829;
BA_ "SigType" SG_ 2566706686 TwoMotorSpd 1;
BA_ "SPN" SG_ 2566706686 TwoMotorSpd 7461;
BA_ "SigType" SG_ 2566706686 Htr 1;
BA_ "SPN" SG_ 2566706686 Htr 5706;
BA_ "SigType" SG_ 2566705406 AFT1ParticulateSnsrCur 1;
BA_ "SPN" SG_ 2566705406 AFT1ParticulateSnsrCur 7393;
BA_ "SigType" SG_ 2566705406 AFT2ParticulateSnsr 1;
BA_ "SPN" SG_ 2566705406 AFT2ParticulateSnsr 5836;
BA_ "SigType" SG_ 2566705406 AFT1ParticulateSnsr 1;
BA_ "SPN" SG_ 2566705406 AFT1ParticulateSnsr 5835;
BA_ "SPN" SG_ 2566705150 AFT2InNOxSnsrSelfDiagTrigger 5712;
BA_ "SPN" SG_ 2566705150 AFT2OutNOxSnsrSelfDiagTrigger 5711;
BA_ "SPN" SG_ 2566705150 AFT1InNOxSnsrSelfDiagTrigger 5710;
BA_ "SPN" SG_ 2566705150 AFT1OutNOxSnsrSelfDiagTrigger 5709;
BA_ "SigType" SG_ 2566704382 AFT2OutGasSnsrPwrSupply 5;
BA_ "SPN" SG_ 2566704382 AFT2OutGasSnsrPwrSupply 5761;
BA_ "SigType" SG_ 2566704382 AFT2InGasSnsrPwrSupply 5;
BA_ "SPN" SG_ 2566704382 AFT2InGasSnsrPwrSupply 5760;
BA_ "SigType" SG_ 2566704382 AFT1OutGasSnsrPwrSupply 5;
BA_ "SPN" SG_ 2566704382 AFT1OutGasSnsrPwrSupply 5759;
BA_ "SigType" SG_ 2566704382 AFT1InGasSnsrPwrSupply 5;
BA_ "SPN" SG_ 2566704382 AFT1InGasSnsrPwrSupply 5758;
BA_ "SPN" SG_ 2566704126 EngExhstGsRcrcltn1Acttr2PrlmnryF 5767;
BA_ "SPN" SG_ 2566704126 EngExhstGsRcrcltn1Acttr2OprtnStt 5772;
BA_ "SPN" SG_ 2566704126 EngExhstGsRcrcltn1Acttr1OprtnStt 5771;
BA_ "SigType" SG_ 2566704126 EngExhstGsRcrcltn1Acttr2DsredPos 1;
BA_ "SPN" SG_ 2566704126 EngExhstGsRcrcltn1Acttr2DsredPos 5770;
BA_ "SigType" SG_ 2566704126 EngExhstGsRcrclton1Actuator2Temp 1;
BA_ "SPN" SG_ 2566704126 EngExhstGsRcrclton1Actuator2Temp 5769;
BA_ "SPN" SG_ 2566704126 EngExhstGsRcrcltn1Acttr2TmpSttus 5768;
BA_ "SigType" SG_ 2566704126 EngExhstGsRcrcltn1Acttr1DsredPos 1;
BA_ "SPN" SG_ 2566704126 EngExhstGsRcrcltn1Acttr1DsredPos 5766;
BA_ "SigType" SG_ 2566704126 EngExhstGsRcrclton1Actuator1Temp 1;
BA_ "SPN" SG_ 2566704126 EngExhstGsRcrclton1Actuator1Temp 5765;
BA_ "SPN" SG_ 2566704126 EngExhstGsRcrcltn1Acttr1TmpSttus 5764;
BA_ "SPN" SG_ 2566704126 EngExhstGsRcrcltn1Acttr1PrlmnryF 5763;
BA_ "SPN" SG_ 2566703870 EngExhstGsRcrcltn2Acttr2OprtnStt 5782;
BA_ "SPN" SG_ 2566703870 EngExhstGsRcrcltn2Acttr1OprtnStt 5781;
BA_ "SigType" SG_ 2566703870 EngExhstGsRcrcltn2Acttr2DsredPos 1;
BA_ "SPN" SG_ 2566703870 EngExhstGsRcrcltn2Acttr2DsredPos 5780;
BA_ "SigType" SG_ 2566703870 EngExhstGsRcrclton2Actuator2Temp 1;
BA_ "SPN" SG_ 2566703870 EngExhstGsRcrclton2Actuator2Temp 5779;
BA_ "SPN" SG_ 2566703870 EngExhstGsRcrcltn2Acttr2TmpSttus 5778;
BA_ "SPN" SG_ 2566703870 EngExhstGsRcrcltn2Acttr2PrlmnryF 5777;
BA_ "SigType" SG_ 2566703870 EngExhstGsRcrcltn2Acttr1DsredPos 1;
BA_ "SPN" SG_ 2566703870 EngExhstGsRcrcltn2Acttr1DsredPos 5776;
BA_ "SigType" SG_ 2566703870 EngExhstGsRcrclton2Actuator1Temp 1;
BA_ "SPN" SG_ 2566703870 EngExhstGsRcrclton2Actuator1Temp 5775;
BA_ "SPN" SG_ 2566703870 EngExhstGsRcrcltn2Acttr1TmpSttus 5774;
BA_ "SPN" SG_ 2566703870 EngExhstGsRcrcltn2Acttr1PrlmnryF 5773;
BA_ "SigType" SG_ 2566703614 EngFuelRackFuelSupplyTemp 1;
BA_ "SPN" SG_ 2566703614 EngFuelRackFuelSupplyTemp 7314;
BA_ "SigType" SG_ 2566703614 EngTurboWastegateActuator2Temp 1;
BA_ "SPN" SG_ 2566703614 EngTurboWastegateActuator2Temp 5787;
BA_ "SigType" SG_ 2566703614 EngFuelValve2Temp 1;
BA_ "SPN" SG_ 2566703614 EngFuelValve2Temp 5786;
BA_ "SigType" SG_ 2566703614 EngFuelValve1Temp 1;
BA_ "SPN" SG_ 2566703614 EngFuelValve1Temp 5785;
BA_ "SigType" SG_ 2566703614 EngThrottleValve2Temp 1;
BA_ "SPN" SG_ 2566703614 EngThrottleValve2Temp 5784;
BA_ "SigType" SG_ 2566703614 EngThrottleValve1Temp 1;
BA_ "SPN" SG_ 2566703614 EngThrottleValve1Temp 5783;
BA_ "SPN" SG_ 2566703358 EngFuelingDesiredRqCount 6897;
BA_ "SPN" SG_ 2566703358 EngFuelingInhibitRqCount 6896;
BA_ "SigType" SG_ 2566703358 EngGasSubstitutionFuelPercentage 1;
BA_ "SPN" SG_ 2566703358 EngGasSubstitutionFuelPercentage 6333;
BA_ "SigType" SG_ 2566703358 EngDualFuelMode 5;
BA_ "SPN" SG_ 2566703358 EngDualFuelMode 6791;
BA_ "SPN" SG_ 2566703358 SrcAddrssOfCntrllngDvcFrFlngStte 6307;
BA_ "SPN" SG_ 2566703358 EngFuelingInhibitPreventedReason 5866;
BA_ "SigType" SG_ 2566703358 EngFuelingInhibitAllowed 5;
BA_ "SPN" SG_ 2566703358 EngFuelingInhibitAllowed 5795;
BA_ "SigType" SG_ 2566703358 FeedbackEngFuelingState 5;
BA_ "SPN" SG_ 2566703358 FeedbackEngFuelingState 5794;
BA_ "SPN" SG_ 2566702590 IntmdTempPreliminaryFMI 5863;
BA_ "SigType" SG_ 2566702590 IntmdTemp 1;
BA_ "SPN" SG_ 2566702590 IntmdTemp 5862;
BA_ "SPN" SG_ 2566702334 IntmdTempPreliminaryFMI 5865;
BA_ "SigType" SG_ 2566702334 IntmdTemp 1;
BA_ "SPN" SG_ 2566702334 IntmdTemp 5864;
BA_ "SigType" SG_ 2566702078 SupplyGasMethanePercentage 1;
BA_ "SPN" SG_ 2566702078 SupplyGasMethanePercentage 5867;
BA_ "SigType" SG_ 2566701822 EngAssistStatus 5;
BA_ "SPN" SG_ 2566701822 EngAssistStatus 7418;
BA_ "SigType" SG_ 2566701822 HybrdSystmHghVltgExpsreIndicator 5;
BA_ "SPN" SG_ 2566701822 HybrdSystmHghVltgExpsreIndicator 7454;
BA_ "SigType" SG_ 2566701822 HybrdSystmIntializationIndicator 5;
BA_ "SPN" SG_ 2566701822 HybrdSystmIntializationIndicator 7453;
BA_ "SigType" SG_ 2566701822 HybrdSystmRgnrtvBrakingIndicator 5;
BA_ "SPN" SG_ 2566701822 HybrdSystmRgnrtvBrakingIndicator 7452;
BA_ "SigType" SG_ 2566701822 HybridSystemElectricAltIndicator 5;
BA_ "SPN" SG_ 2566701822 HybridSystemElectricAltIndicator 7451;
BA_ "SigType" SG_ 2566701822 HybrdSystmMtrOvrspedAudibleAlarm 5;
BA_ "SPN" SG_ 2566701822 HybrdSystmMtrOvrspedAudibleAlarm 7450;
BA_ "SigType" SG_ 2566701822 HybrdSystmMtorOverspeedIndicator 5;
BA_ "SPN" SG_ 2566701822 HybrdSystmMtorOverspeedIndicator 7449;
BA_ "SigType" SG_ 2566701822 HybridSystemServiceIndicator 5;
BA_ "SPN" SG_ 2566701822 HybridSystemServiceIndicator 7448;
BA_ "SigType" SG_ 2566701822 PropulsionSystemActive 5;
BA_ "SPN" SG_ 2566701822 PropulsionSystemActive 7315;
BA_ "SigType" SG_ 2566701822 HybridSystemOBDRelatedDTCStatus 5;
BA_ "SPN" SG_ 2566701822 HybridSystemOBDRelatedDTCStatus 6810;
BA_ "SigType" SG_ 2566701822 HybridSystemStopIndicator 5;
BA_ "SPN" SG_ 2566701822 HybridSystemStopIndicator 5874;
BA_ "SigType" SG_ 2566701822 HybridSystemOverheatIndicator 5;
BA_ "SPN" SG_ 2566701822 HybridSystemOverheatIndicator 5873;
BA_ "SigType" SG_ 2566701822 HybridSystemWarningIndicator 5;
BA_ "SPN" SG_ 2566701822 HybridSystemWarningIndicator 5872;
BA_ "SigType" SG_ 2431661310 IntmdNH3SnsrHtrCtrl 5;
BA_ "SPN" SG_ 2431661310 IntmdNH3SnsrHtrCtrl 5861;
BA_ "SPN" SG_ 2431661310 IntmdNH3SnsrHtrPreliminaryFMI 5860;
BA_ "SPN" SG_ 2431661310 IntmdNH3SnsrAtTemp 5859;
BA_ "SigType" SG_ 2431661310 IntmdNH3SnsrPwrInRange 5;
BA_ "SPN" SG_ 2431661310 IntmdNH3SnsrPwrInRange 5858;
BA_ "SigType" SG_ 2431661310 IntmdNH3ReadingStable 5;
BA_ "SPN" SG_ 2431661310 IntmdNH3ReadingStable 5857;
BA_ "SPN" SG_ 2431661310 IntmdNH3SnsrPreliminaryFMI 5856;
BA_ "SigType" SG_ 2431661310 IntmdNH3 1;
BA_ "SPN" SG_ 2431661310 IntmdNH3 5855;
BA_ "SigType" SG_ 2431661054 IntmdNH3SnsrHtrCtrl 5;
BA_ "SPN" SG_ 2431661054 IntmdNH3SnsrHtrCtrl 5854;
BA_ "SPN" SG_ 2431661054 IntmdNH3SnsrHtrPreliminaryFMI 5853;
BA_ "SigType" SG_ 2431661054 IntmdNH3SnsrAtTemp 5;
BA_ "SPN" SG_ 2431661054 IntmdNH3SnsrAtTemp 5852;
BA_ "SigType" SG_ 2431661054 IntmdNH3SnsrPwrInRange 5;
BA_ "SPN" SG_ 2431661054 IntmdNH3SnsrPwrInRange 5851;
BA_ "SigType" SG_ 2431661054 IntmdNH3ReadingStable 5;
BA_ "SPN" SG_ 2431661054 IntmdNH3ReadingStable 5850;
BA_ "SPN" SG_ 2431661054 IntmdNH3SnsrPreliminaryFMI 5849;
BA_ "SigType" SG_ 2431661054 IntmdNH3 1;
BA_ "SPN" SG_ 2431661054 IntmdNH3 5848;
BA_ "SigType" SG_ 2230334206 LnrDsplcmntSnsrSnsrFigureOfMerit 5;
BA_ "SPN" SG_ 2230334206 LnrDsplcmntSnsrSnsrFigureOfMerit 5824;
BA_ "SigType" SG_ 2230334206 MeasuredLinearDisplacement 1;
BA_ "SPN" SG_ 2230334206 MeasuredLinearDisplacement 5823;
BA_ "SigType" SG_ 2230333950 WandSensorFigureOfMerit 5;
BA_ "SPN" SG_ 2230333950 WandSensorFigureOfMerit 5822;
BA_ "SigType" SG_ 2230333950 WandAngle 1;
BA_ "SPN" SG_ 2230333950 WandAngle 5821;
BA_ "SigType" SG_ 2364551422 WirelessSignalStrength1 1;
BA_ "SPN" SG_ 2364551422 WirelessSignalStrength1 5753;
BA_ "SPN" SG_ 2364551422 TransmitterID1 5752;
BA_ "SPN" SG_ 2364551422 TransmitterCmdState 5751;
BA_ "SigType" SG_ 2364551422 WirelessRollingMessageCounter 1;
BA_ "SPN" SG_ 2364551422 WirelessRollingMessageCounter 5750;
BA_ "SigType" SG_ 2364551166 TmeToCollisionWithRelevantObject 1;
BA_ "SPN" SG_ 2364551166 TmeToCollisionWithRelevantObject 5680;
BA_ "SPN" SG_ 2364551166 BndOffPrbabilityOfRelevantObject 5679;
BA_ "SPN" SG_ 2364551166 RlvntObjctDtctdFrAdvncdEmrgncyBr 5678;
BA_ "SPN" SG_ 2364551166 CollisionWarningLevel 5677;
BA_ "SPN" SG_ 2364551166 AdvncdEmrgencyBrakingSystemState 5676;
BA_ "SigType" SG_ 2566730238 Fan2DriveBypassCmdStatus 1;
BA_ "SPN" SG_ 2566730238 Fan2DriveBypassCmdStatus 1708;
BA_ "SigType" SG_ 2566730238 HydFan2MotorPress 1;
BA_ "SPN" SG_ 2566730238 HydFan2MotorPress 1707;
BA_ "SigType" SG_ 2566730238 Fan2Speed 1;
BA_ "SPN" SG_ 2566730238 Fan2Speed 1598;
BA_ "SPN" SG_ 2566730238 Fan2DriveState 1557;
BA_ "SigType" SG_ 2566730238 EstPercentFan2Speed 1;
BA_ "SPN" SG_ 2566730238 EstPercentFan2Speed 1550;
BA_ "SigType" SG_ 2566711038 LubricationTimingCycleStatus 5;
BA_ "SPN" SG_ 2566711038 LubricationTimingCycleStatus 5520;
BA_ "SigType" SG_ 2566711038 LubricationReservoirLevel 4;
BA_ "SPN" SG_ 2566711038 LubricationReservoirLevel 5519;
BA_ "SigType" SG_ 2566711038 LubricationPumpEnableStatus 5;
BA_ "SPN" SG_ 2566711038 LubricationPumpEnableStatus 5518;
BA_ "SPN" SG_ 2566711038 LubricationOperationModeStatus 5517;
BA_ "SPN" SG_ 2566711038 LubricationCycleModeStatus 5516;
BA_ "SigType" SG_ 2566711038 LubricationCycleModeLockStatus 5;
BA_ "SPN" SG_ 2566711038 LubricationCycleModeLockStatus 5515;
BA_ "SigType" SG_ 2566710782 HydOilTemp 1;
BA_ "SPN" SG_ 2566710782 HydOilTemp 5536;
BA_ "SigType" SG_ 2566710782 HydOilRelativeDielectricity 1;
BA_ "SPN" SG_ 2566710782 HydOilRelativeDielectricity 5535;
BA_ "SigType" SG_ 2566710782 HydOilDensity 1;
BA_ "SPN" SG_ 2566710782 HydOilDensity 5534;
BA_ "SigType" SG_ 2566710782 HydOilDynamicViscosity 1;
BA_ "SPN" SG_ 2566710782 HydOilDynamicViscosity 5533;
BA_ "SigType" SG_ 2566710526 EngFuelTemp 1;
BA_ "SPN" SG_ 2566710526 EngFuelTemp 5540;
BA_ "SigType" SG_ 2566710526 EngFuelDielectricity 1;
BA_ "SPN" SG_ 2566710526 EngFuelDielectricity 5539;
BA_ "SigType" SG_ 2566710526 EngFuelDensity 1;
BA_ "SPN" SG_ 2566710526 EngFuelDensity 5538;
BA_ "SigType" SG_ 2566710526 EngFuelDynamicViscosity 1;
BA_ "SPN" SG_ 2566710526 EngFuelDynamicViscosity 5537;
BA_ "SigType" SG_ 2432492542 DsredEngTurbo2TurbineOutletPress 1;
BA_ "SPN" SG_ 2432492542 DsredEngTurbo2TurbineOutletPress 5545;
BA_ "SigType" SG_ 2432492542 EngTurbo2TurbineOutletPress 1;
BA_ "SPN" SG_ 2432492542 EngTurbo2TurbineOutletPress 5544;
BA_ "SigType" SG_ 2432492542 EngExhaustBrakeActuatorCmd 1;
BA_ "SPN" SG_ 2432492542 EngExhaustBrakeActuatorCmd 5543;
BA_ "SigType" SG_ 2432492542 DsredEngTurbo1TurbineOutletPress 1;
BA_ "SPN" SG_ 2432492542 DsredEngTurbo1TurbineOutletPress 5542;
BA_ "SigType" SG_ 2432492542 EngTurbo1TurbineOutletPress 1;
BA_ "SPN" SG_ 2432492542 EngTurbo1TurbineOutletPress 5541;
VAL_ 2566705662 FlashProtectLamp 3 "Unavailable / Do Not Flash" 2 "Reserved" 1 "Fast Flash" 0 "Slow Flash" ;
VAL_ 2566705662 FlashAmberWarningLamp 3 "Unavailable / Do Not Flash" 2 "Reserved" 1 "Fast Flash" 0 "Slow Flash" ;
VAL_ 2566705662 FlashRedStopLamp 3 "Unavailable / Do Not Flash" 2 "Reserved" 1 "Fast Flash" 0 "Slow Flash" ;
VAL_ 2566705662 FlashMalfuncIndicatorLamp 3 "Unavailable / Do Not Flash" 2 "Class C DTC  " 1 "Fast Flash" 0 "Slow Flash" ;
VAL_ 2566705662 ProtectLampStatus 3 "Not available" 2 "Reserved" 1 "Lamp On" 0 "Lamp Off" ;
VAL_ 2566705662 AmberWarningLampStatus 3 "Not available" 2 "Reserved" 1 "Lamp On" 0 "Lamp Off" ;
VAL_ 2566705662 RedStopLampState 3 "Not available" 2 "Reserved" 1 "Lamp On" 0 "Lamp Off" ;
VAL_ 2566705662 MalfunctionIndicatorLampStatus 3 "Not available" 2 "Short MIL for WWH OBD" 1 "Lamp On" 0 "Lamp Off" ;
VAL_ 2349465342 StaticRollAngleStatus_5583 7 "Not available" 6 "Error" 5 "Reserved" 4 "Angle Data Invalid" 3 "Sensor Reboots" 2 "Sensor Defect" 1 "Sensor OK" 0 "Sensor Busy" ;
VAL_ 2364553470 EngDualFuelModeCmd 3 "Not available" 2 "Reserved" 1 "Activate dual fuel mode" 0 "De-activate dual fuel mode" ;
VAL_ 2364553214 EngTrbCmprssrBlwffActtr1OprtnStt 15 "Not available" 14 "Error" 6 "Calibration in Progress" 5 "Uncontrolled Shutdown Active" 4 "Controlled Shutdown Active" 3 "Derate Active" 2 "Alarm High Severity" 1 "Alarm" 0 "Normal" ;
VAL_ 2364553214 EngTrbCmprssrBlwffActtr1TmpSttus 7 "Not available" 6 "Error" 5 "Not Defined" 4 "Low Most severe" 3 "Low Least severe" 2 "In Range" 1 "High Least severe" 0 "High Most severe" ;
VAL_ 2565874430 PersistentLimitStatus 7 "Not available" 6 "Non-recoverable fault" 3 "Limited low" 2 "Limited high" 1 "Operator limited/controlled" 0 "Not limited" ;
VAL_ 2565874430 MachineSelectedSpeedSource 7 "Not available" 4 "'Simulated' speed" 3 "'Blended' speed" 2 "Navigation-based speed" 1 "Ground-based speed" 0 "Wheel-based speed" ;
VAL_ 2565874430 MachineSelectedDirection 2 "Error indication" 1 "Forward" 0 "Reverse" 3 "Not available" ;
VAL_ 2559049470 DesiredEngFuelingState_5793 3 "Don't care / Take no action" 2 "Parameter supported" 1 "Fueling desired" 0 "Fueling not desired" ;
VAL_ 2559049470 RequestedFuelType_6317 255 "Not supported" 254 "Reserved for use in SPN 5837" 24 "Reserved for use in SPN 5837" 23 "Natural Gas" 7 "Propane" 6 "Compressed Natural Gas" 5 "Liquefied Petroleum Gas" 4 "Diesel" 3 "Ethanol" 2 "Methanol" 1 "Gasoline/petrol" 0 "Not available" ;
VAL_ 2559049470 EngGasFuelUsageInhibited_6833 3 "Not available" 2 "Error" 1 "Gaseous Fuel Usage Inhibited" 0 "Gaseous Fuel Usage Not Inhibited" ;
VAL_ 2349596414 DrvrActDmndFrAdvEmrgncyBrk_5681 3 "don’t' care / take no action" 2 "reserved" 1 "the driver wants the Advanced Emergency Braking System to warn or intervene if necessary" 0 "the driver does not want the Advanced Emergency Braking System to warn or intervene at any time" ;
VAL_ 2563571454 DataFormat_ErrorCondition_2419 3 "Not Available or error" 2 "Data format is unsigned Long Integer" 1 "Data format is Floating" 0 "Data format is Long Integer" ;
VAL_ 2563571454 ProcessDataType_2420 3 "Message is Actual value request" 2 "Message is Set Point request" 1 "Data is Actual values" 0 "Data is Set Point" ;
VAL_ 2563505918 DataFormat_ErrorCondition_2419 3 "Not Available or error" 2 "Data format is unsigned Long Integer" 1 "Data format is Floating" 0 "Data format is Long Integer" ;
VAL_ 2563505918 ProcessDataType_2420 3 "Message is Actual value request" 2 "Message is Set Point request" 1 "Data is Actual values" 0 "Data is Set Point" ;
VAL_ 2563178238 ValveFailSafeMode_2934 3 "Don’t Care" 2 "Reserved" 1 "Float" 0 "Block" ;
VAL_ 2563178238 ValveState_2932 15 "Don’t Care" 3 "Floating" 2 "Retract" 1 "Extend" 0 "Blocked" ;
VAL_ 2358509310 NMControlModeIndicator 0 "SetPendingName" 1 "PendingName" 2 "CurrentName" 3 "NameACK" 4 "NameNACK" 5 "ReqPendingName" 6 "ReqCurrentName" 7 "AdoptPendingName" 8 "ReqNameAddressClaim" ;
VAL_ 2358509310 ErrorCode 0 "Security not satisfied" 1 "Item(s) not allowed to change" 2 "Item conflict" 3 "Checksum does not match" 4 "Pending Name not set" 255 "Not Available" 5 "Other" ;
VAL_ 2558983934 SwitchedPowerOutput18Cmd_6002 3 "Take no action" 2 "Reserved" 1 "Output on" 0 "Output off" ;
VAL_ 2558983934 SwitchedPowerOutput19Cmd_6001 3 "Take no action" 2 "Reserved" 1 "Output on" 0 "Output off" ;
VAL_ 2558983934 SwitchedPowerOutput20Cmd_6000 3 "Take no action" 2 "Reserved" 1 "Output on" 0 "Output off" ;
VAL_ 2558983934 SwitchedPowerOutput13Cmd_5999 3 "Take no action" 2 "Reserved" 1 "Output on" 0 "Output off" ;
VAL_ 2558983934 SwitchedPowerOutput14Cmd_5998 3 "Take no action" 2 "Reserved" 1 "Output on" 0 "Output off" ;
VAL_ 2558983934 SwitchedPowerOutput15Cmd_5997 3 "Take no action" 2 "Reserved" 1 "Output on" 0 "Output off" ;
VAL_ 2558983934 SwitchedPowerOutput16Cmd_5996 3 "Take no action" 2 "Reserved" 1 "Output on" 0 "Output off" ;
VAL_ 2558983934 SwitchedPowerOutput9Cmd_5995 3 "Take no action" 2 "Reserved" 1 "Output on" 0 "Output off" ;
VAL_ 2558983934 SwitchedPowerOutput10Cmd_5994 3 "Take no action" 2 "Reserved" 1 "Output on" 0 "Output off" ;
VAL_ 2558983934 SwitchedPowerOutput29Cmd_6015 3 "Take no action" 2 "Reserved" 1 "Output on" 0 "Output off" ;
VAL_ 2558983934 SwitchedPowerOutput30Cmd_6014 3 "Take no action" 2 "Reserved" 1 "Output on" 0 "Output off" ;
VAL_ 2558983934 SwitchedPowerOutput31Cmd_6013 3 "Take no action" 2 "Reserved" 1 "Output on" 0 "Output off" ;
VAL_ 2558983934 SwitchedPowerOutput32Cmd_6012 3 "Take no action" 2 "Reserved" 1 "Output on" 0 "Output off" ;
VAL_ 2558983934 SwitchedPowerOutput25Cmd_6011 3 "Take no action" 2 "Reserved" 1 "Output on" 0 "Output off" ;
VAL_ 2558983934 SwitchedPowerOutput26Cmd_6010 3 "Take no action" 2 "Reserved" 1 "Output on" 0 "Output off" ;
VAL_ 2558983934 SwitchedPowerOutput27Cmd_6009 3 "Take no action" 2 "Reserved" 1 "Output on" 0 "Output off" ;
VAL_ 2558983934 SwitchedPowerOutput28Cmd_6008 3 "Take no action" 2 "Reserved" 1 "Output on" 0 "Output off" ;
VAL_ 2558983934 SwitchedPowerOutput21Cmd_6007 3 "Take no action" 2 "Reserved" 1 "Output on" 0 "Output off" ;
VAL_ 2558983934 SwitchedPowerOutput22Cmd_6006 3 "Take no action" 2 "Reserved" 1 "Output on" 0 "Output off" ;
VAL_ 2558983934 SwitchedPowerOutput23Cmd_6005 3 "Take no action" 2 "Reserved" 1 "Output on" 0 "Output off" ;
VAL_ 2558983934 SwitchedPowerOutput24Cmd_6004 3 "Take no action" 2 "Reserved" 1 "Output on" 0 "Output off" ;
VAL_ 2558983934 SwitchedPowerOutput17Cmd_6003 3 "Take no action" 2 "Reserved" 1 "Output on" 0 "Output off" ;
VAL_ 2558983934 SwitchedPowerOutput11Cmd_5993 3 "Take no action" 2 "Reserved" 1 "Output on" 0 "Output off" ;
VAL_ 2558983934 SwitchedPowerOutput12Cmd_5992 3 "Take no action" 2 "Reserved" 1 "Output on" 0 "Output off" ;
VAL_ 2558983934 SwitchedPowerOutput5Cmd_5991 3 "Take no action" 2 "Reserved" 1 "Output on" 0 "Output off" ;
VAL_ 2558983934 SwitchedPowerOutput6Cmd_5990 3 "Take no action" 2 "Reserved" 1 "Output on" 0 "Output off" ;
VAL_ 2558983934 SwitchedPowerOutput7Cmd_5989 3 "Take no action" 2 "Reserved" 1 "Output on" 0 "Output off" ;
VAL_ 2558983934 SwitchedPowerOutput8Cmd_5988 3 "Take no action" 2 "Reserved" 1 "Output on" 0 "Output off" ;
VAL_ 2558983934 SwitchedPowerOutput1Cmd_5987 3 "Take no action" 2 "Reserved" 1 "Output on" 0 "Output off" ;
VAL_ 2558983934 SwitchedPowerOutput2Cmd_5986 3 "Take no action" 2 "Reserved" 1 "Output on" 0 "Output off" ;
VAL_ 2558983934 SwitchedPowerOutput3Cmd_5985 3 "Take no action" 2 "Reserved" 1 "Output on" 0 "Output off" ;
VAL_ 2558983934 SwitchedPowerOutput4Cmd_5984 3 "Take no action" 2 "Reserved" 1 "Output on" 0 "Output off" ;
VAL_ 2349727486 TransMode10_6570 3 "Take no action" 2 "Reserved" 1 "Enable" 0 "Disable" ;
VAL_ 2349727486 TransMode9_6569 3 "Take no action" 2 "Reserved" 1 "Enable" 0 "Disable" ;
VAL_ 2566767358 EngFuelIsolationCtrl 3 "Don't care / take no action" 2 "Reserved" 1 "Gaseous Fuel is Used" 0 "Gaseous Fuel Migration is Prevented" ;
VAL_ 2566767358 FuelType 255 "Not available, Parameter not supported)" 254 "Error" 28 "Dual Fuel, Diesel and LNG" 27 "Dual Fuel, Diesel and CNG" 26 "Natural Gas, Compressed or Liquefied Natural Gas)" 25 "Bi-fuel using diesel" 24 "Bi-fuel vehicle using NG" 23 "Natural Gas, NG)" 22 "Hybrid vehicle in regeneration mode" 21 "Hybrid vehicle using battery and combustion engine" 20 "Hybrid vehicle using battery" 19 "Hybrid vehicle using diesel engine" 18 "Hybrid vehicle using gasoline engine on ethanol" 17 "Hybrid vehicle using gasoline engine" 16 "Bi-fuel vehicle using battery and combustion engine" 15 "Bi-fuel vehicle using battery" 14 "Bi-fuel vehicle using propane" 13 "Bi-fuel vehicle using CNG" 12 "Bi-fuel vehicle using LPG" 11 "Bi-fuel vehicle using ethanol" 10 "Bi-fuel vehicle using methanol" 9 "Bi-fuel vehicle using gasoline" 8 "Battery/electric" 7 "Propane" 6 "Compressed Natural Gas" 5 "Liquefied Petroleum Gas" 4 "Diesel" 3 "Ethanol" 2 "Methanol" 1 "Gasoline/petrol" 0 "Not available, NONE" ;
VAL_ 2566705150 AFT2InNOxSnsrSelfDiagTrigger 15 "Not supported" 4 "NOx Sensor ATI2 Self Diagnosis Request at After Run" 3 "NOx Sensor ATI2 Self Diagnosis Request at fuel cut" 2 "NOx Sensor ATI2 Self Diagnosis Request at partial load" 1 "NOx Sensor ATI2 Self Diagnosis Request at Lambda=1.0" 0 "Diagnostic mode disabled" ;
VAL_ 2566705150 AFT2OutNOxSnsrSelfDiagTrigger 15 "Not supported" 4 "NOx Sensor ATO2 Self Diagnosis Request at After Run" 3 "NOx Sensor ATO2 Self Diagnosis Request at fuel cut" 2 "NOx Sensor ATO2 Self Diagnosis Request at partial load" 1 "NOx Sensor ATO2 Self Diagnosis Request at Lambda=1.0" 0 "Diagnostic mode disabled" ;
VAL_ 2566705150 AFT1InNOxSnsrSelfDiagTrigger 2 "NOx Sensor ATI1 Self Diagnosis Request at partial load" 1 "NOx Sensor ATI1 Self Diagnosis Request at Lambda=1.0" 0 "Diagnostic mode disabled" 15 "Not supported" 4 "NOx Sensor ATI1 Self Diagnosis Request at After Run" 3 "NOx Sensor ATI1 Self Diagnosis Request at fuel cut" ;
VAL_ 2566705150 AFT1OutNOxSnsrSelfDiagTrigger 15 "Not supported" 4 "NOx Sensor ATO1 Self Diagnosis Request at After Run" 3 "NOx Sensor ATO1 Self Diagnosis Request at fuel cut" 2 "NOx Sensor ATO1 Self Diagnosis Request at partial load" 1 "NOx Sensor ATO1 Self Diagnosis Request at Lambda=1.0" 0 "Diagnostic mode disabled" ;
VAL_ 2566704382 AFT2OutGasSnsrPwrSupply 3 "Unavailable" 2 "Error" 1 "On: The ECU is powering the Aftertreatment 2 Outlet Gas Sensor" 0 "Off" ;
VAL_ 2566704382 AFT2InGasSnsrPwrSupply 3 "Unavailable" 2 "Error" 1 "On: The ECU is powering the Aftertreatment 2 Intake Gas Sensor" 0 "Off" ;
VAL_ 2566704382 AFT1OutGasSnsrPwrSupply 3 "Unavailable" 2 "Error" 1 "On: The ECU is powering the Aftertreatment 1 Outlet Gas Sensor" 0 "Off" ;
VAL_ 2566704382 AFT1InGasSnsrPwrSupply 3 "Unavailable" 2 "Error" 1 "On: The ECU is powering the Aftertreatment 1 Intake Gas Sensor" 0 "Off" ;
VAL_ 2566704126 EngExhstGsRcrcltn1Acttr2OprtnStt 15 "Not available" 14 "Error" 5 "Uncontrolled Shutdown Active" 4 "Controlled Shutdown Active" 3 "Derate Active" 2 "Alarm High Severity" 1 "Alarm" 0 "Normal" ;
VAL_ 2566704126 EngExhstGsRcrcltn1Acttr1OprtnStt 15 "Not available" 14 "Error" 5 "Uncontrolled Shutdown Active" 4 "Controlled Shutdown Active" 3 "Derate Active" 2 "Alarm High Severity" 1 "Alarm" 0 "Normal" ;
VAL_ 2566704126 EngExhstGsRcrcltn1Acttr2TmpSttus 7 "Not available" 6 "Error" 5 "Not Defined" 4 "Low Most severe" 3 "Low Least severe" 2 "In Range " 1 "High Least severe" 0 "High Most severe" ;
VAL_ 2566704126 EngExhstGsRcrcltn1Acttr1TmpSttus 7 "Not available" 6 "Error" 5 "Not Defined" 4 "Low Most severe" 3 "Low Least severe" 2 "In Range " 1 "High Least severe" 0 "High Most severe" ;
VAL_ 2566703870 EngExhstGsRcrcltn2Acttr2OprtnStt 15 "Not available" 14 "Error" 5 "Uncontrolled Shutdown Active" 4 "Controlled Shutdown Active" 3 "Derate Active" 2 "Alarm High Severity" 1 "Alarm" 0 "Normal" ;
VAL_ 2566703870 EngExhstGsRcrcltn2Acttr1OprtnStt 15 "Not available" 14 "Error" 5 "Uncontrolled Shutdown Active" 4 "Controlled Shutdown Active" 3 "Derate Active" 2 "Alarm High Severity" 1 "Alarm" 0 "Normal" ;
VAL_ 2566703870 EngExhstGsRcrcltn2Acttr2TmpSttus 7 "Not available" 6 "Error" 5 "Not Defined" 4 "Low Most severe" 3 "Low Least severe" 2 "In Range " 1 "High Least severe" 0 "High Most severe" ;
VAL_ 2566703870 EngExhstGsRcrcltn2Acttr1TmpSttus 7 "Not available" 6 "Error" 5 "Not Defined" 4 "Low Most severe" 3 "Low Least severe" 2 "In Range " 1 "High Least severe" 0 "High Most severe" ;
VAL_ 2566703358 EngFuelingDesiredRqCount 3 "More than 10 active fueling desired requests" ;
VAL_ 2566703358 EngFuelingInhibitRqCount 3 "More than 10 active fueling inhibit requests" ;
VAL_ 2566703358 EngDualFuelMode 3 "Not available" 2 "Reserved" 1 "Actual dual fuel mode on" 0 "Actual dual fuel mode off" ;
VAL_ 2566703358 EngFuelingInhibitPreventedReason 15 "Not Supported" 12 "Low idle governor operation required" 11 "Engine driven fan request" 10 "Maximum number of engine fuelling inhibit requests" 9 "Insufficient SLI battery charge" 8 "Engine protection" 7 "Engine load too high" 6 "Aftertreatment Protection" 5 "Aftertreatment system is cold" 4 "Service Override" 3 "Engine is cold" 2 "Oil Distribution in engine is incomplete" 1 "Aftertreatment regeneration is active or preparing to be active" 0 "Fueling inhibit allowed" ;
VAL_ 2566703358 EngFuelingInhibitAllowed 3 "Not Supported" 2 "SAE Reserved" 1 "Engine will stop fueling in response to SPN 5793 Desired Engine Fueling State" 0 "Engine currently will not stop fueling in response to SPN 5793 Desired Engine Fueling State" ;
VAL_ 2566703358 FeedbackEngFuelingState 3 "Not Supported" 2 "No active request per SPN 5793 Desired Engine Fueling State or SPN 5795 Engine Fueling Inhibit Allowed = 00" 1 "Engine will be kept running" 0 "Fueling is or will be inhibited" ;
VAL_ 2566701822 EngAssistStatus 3 "Not Available" 2 "Error" 1 "Hybrid system may or may not mechanically assist engine rotation" 0 "Hybrid system is not mechanically assisting engine rotation" ;
VAL_ 2566701822 HybrdSystmHghVltgExpsreIndicator 3 "Not Available" 2 "Error" 1 "System is operational and has detected a compromise" 0 "System is operational and intact" ;
VAL_ 2566701822 HybrdSystmIntializationIndicator 3 "Not Available" 2 "Error" 1 "Hybrid System Initialization Indicator is active" 0 "Hybrid System Initialization Indicator is not active" ;
VAL_ 2566701822 HybrdSystmRgnrtvBrakingIndicator 3 "Not Available" 2 "Regenerative braking is disabled or faulted " 1 "Regenerative braking is active" 0 "Regenerative braking is inactive" ;
VAL_ 2566701822 HybridSystemElectricAltIndicator 3 "Not Available" 2 "Alternator Indicator is flashing" 1 "Alternator Indicator is on" 0 "Alternator Indicator is off" ;
VAL_ 2566701822 HybrdSystmMtrOvrspedAudibleAlarm 3 "Not Available" 2 "Error" 1 "Motor Overspeed Audible Alarm is on" 0 "Motor Overspeed Audible Alarm is off" ;
VAL_ 2566701822 HybrdSystmMtorOverspeedIndicator 3 "Not Available" 2 "Hybrid System Motor Overspeed Indicator is flashing" 1 "Hybrid System Motor Overspeed Indicator is on continously" 0 "Hybrid System Motor Overspeed Indicator is off" ;
VAL_ 2566701822 HybridSystemServiceIndicator 3 "Not Available" 2 "Hybrid Service Indicator is flashing" 1 "Hybrid Service Indicator is on continously" 0 "Hybrid Service Indicator is off" ;
VAL_ 2566701822 PropulsionSystemActive 3 "Not Available" 2 "SAE Reserved" 1 "Propulsion System is ready to move" 0 "Propulsion System is not ready to move vehicle if commanded by operator" ;
VAL_ 2566701822 HybridSystemOBDRelatedDTCStatus 3 "Not available" 2 "SAE Reserved" 1 "Hybrid System has an active OBD related DTC" 0 "Hybrid System does not have an active OBD related DTC" ;
VAL_ 2566701822 HybridSystemStopIndicator 3 "Not available" 2 "Hybrid System Stop Indicator is flashing" 1 "Hybrid System Stop Indicator is on continuously" 0 "Hybrid System Stop Indicator is off" ;
VAL_ 2566701822 HybridSystemOverheatIndicator 3 "Not available" 2 "Hybrid System Temperature Indicator is flashing" 1 "Hybrid System Temperature Indicator is on continuously" 0 "Hybrid System Temperature Indicator is off" ;
VAL_ 2566701822 HybridSystemWarningIndicator 3 "Not available" 2 "Hybrid System Warning Indicator is flashing" 1 "Hybrid System Warning Indicator is on continuously" 0 "Hybrid System Warning Indicator is off" ;
VAL_ 2431661310 IntmdNH3SnsrHtrCtrl 3 "Heater off or Not available" 2 "Preheat 1 " 1 "Preheat 2 " 0 "Automatic " ;
VAL_ 2431661310 IntmdNH3SnsrAtTemp 3 "Not available" 2 "Error" 1 "Heater element is in range" 0 "Heater element is not in range" ;
VAL_ 2431661310 IntmdNH3SnsrPwrInRange 3 "Not available" 2 "Error" 1 "Heater element is in range" 0 "Heater element is not in range" ;
VAL_ 2431661310 IntmdNH3ReadingStable 3 "Not available" 2 "Error" 1 "Reading is stable" 0 "Reading is not stable" ;
VAL_ 2431661054 IntmdNH3SnsrHtrCtrl 3 "Heater off or not available" 2 "Preheat 1 " 1 "Preheat 2 " 0 "Automatic " ;
VAL_ 2431661054 IntmdNH3SnsrAtTemp 3 "Not available" 2 "Error" 1 "Heater element is in range" 0 "Heater element is not in range" ;
VAL_ 2431661054 IntmdNH3SnsrPwrInRange 3 "Not available" 2 "Error" 1 "Power is in range" 0 "Power is not in range" ;
VAL_ 2431661054 IntmdNH3ReadingStable 3 "Not available" 2 "Error" 1 "Reading is stable" 0 "Reading is not stable" ;
VAL_ 2230334206 LnrDsplcmntSnsrSnsrFigureOfMerit 3 "Sensor not available" 2 "Sensor failed" 1 "Sensor degraded" 0 "Sensor fully functional" ;
VAL_ 2230333950 WandSensorFigureOfMerit 3 "Sensor not available" 2 "Sensor failed" 1 "Sensor degraded" 0 "Sensor fully functional" ;
VAL_ 2364551422 TransmitterCmdState 15 "Don't Care" 14 "Error" 4 "Standby" 3 "Transmitter Test" 2 "Field Test" 1 "Clear" 0 "Stop" ;
VAL_ 2364551166 BndOffPrbabilityOfRelevantObject 7 "signal not available / not installed" 6 "error indication" 5 "relevant object is already in a turning maneuver" 4 "highest probability for a bend off maneuver of the relevant object" 3 "high probability for a bend off maneuver of the relevant object" 2 "medium probability for a bend off maneuver of the relevant object" 1 "low probability for a bend off maneuver of the relevant object" 0 "no indication for a bend off maneuver of the relevant object" ;
VAL_ 2364551166 RlvntObjctDtctdFrAdvncdEmrgncyBr 7 "signal not available / not installed" 6 "error indication" 2 "relevant object is not being detected reliably" 1 "relevant object is being monitored" 0 "no relevant object monitored" ;
VAL_ 2364551166 CollisionWarningLevel 15 "don’t care / take no action" 7 "warning level 7" 6 "warning level 6" 5 "warning level 5" 4 "warning level 4" 3 "warning level 3" 2 "warning level 2" 1 "warning level 1" 0 "no warning" ;
VAL_ 2364551166 AdvncdEmrgencyBrakingSystemState 14 "error indication" 8 "system performance and/or sensitivity limited" 7 "emergency braking active" 6 "collision warning with braking" 5 "collision warning active" 4 "driver overrides system" 3 "system is ready and activated" 2 "system is deactivated by driver" 1 "system is temporarily not available" 0 "system is not ready" 15 "not available / not installed" ;
VAL_ 2566730238 Fan2DriveState 15 "Not available" 14 "Other" 13 "Engine brake" 12 "Timer" 11 "A/C system" 10 "Transmission retarder" 9 "Manual control" 8 "Reverse Operation" 7 "Default Operation" 6 "Excessive hydraulic oil temperature" 5 "Excessive transmission oil temperature" 4 "Excessive engine coolant temperature" 3 "Excessive engine oil temperature" 2 "Excessive engine air temperature" 1 "Engine system-General" 0 "Fan off" ;
VAL_ 2566711038 LubricationTimingCycleStatus 3 "Not available or not installed" 2 "Error " 1 "Enabled" 0 "Paused " ;
VAL_ 2566711038 LubricationReservoirLevel 3 "Not available or not installed" 2 "Error " 1 "Reservoir Low" 0 "Reservoir Not Low" ;
VAL_ 2566711038 LubricationPumpEnableStatus 3 "Not available" 2 "Error" 1 "Enabled" 0 "Disabled" ;
VAL_ 2566711038 LubricationOperationModeStatus 7 "Not Available" 6 "Error" 5 "Reserved" 4 "Test Mode # 3" 3 "Test Mode # 2" 2 "Test Mode # 1" 1 "Manual Service Mode" 0 "Automatic Mode" ;
VAL_ 2566711038 LubricationCycleModeStatus 7 "Not available" 6 "Error" 2 "Cycle mode # 3" 1 "Cycle mode # 2" 0 "Cycle mode # 1" ;
VAL_ 2566711038 LubricationCycleModeLockStatus 3 "Not available" 2 "Error" 1 "Locked" 0 "Not Locked" ;
